VERSION "HNNBNNNYNNNNNNNNNNNNNNNNNNNNNNNNNNNNNNNNNN/4/%%%/4/'%**4NNN///"

NS_ :

BS_:

BU_: AAG BCM1 BCM2 ELV Gateway HDSG IEZS MFG MSBBR SAD SAD2 Schwerpanzer_Zusatz SitzMem_BFS SitzMem_FS SitzMem_HBFS SitzMem_HFS SitzMem_SR3 SpoilerSG TSG_BFS TSG_FS VSG VTS DK_Dummy

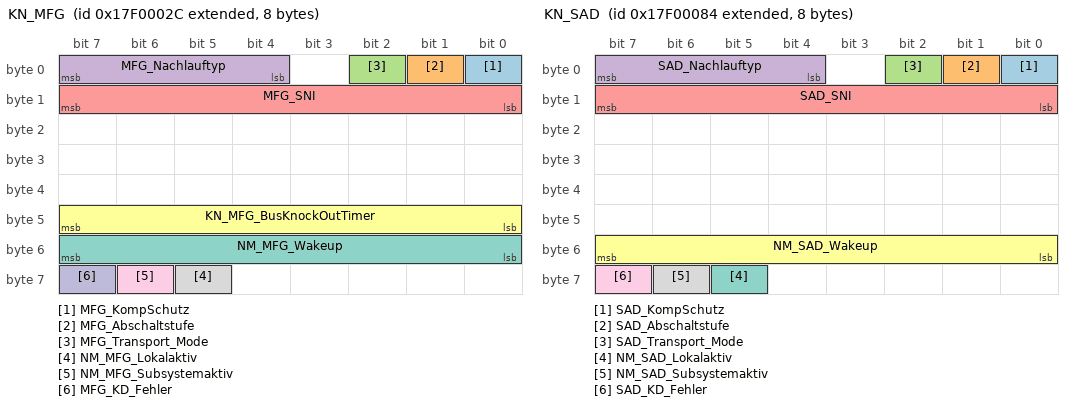
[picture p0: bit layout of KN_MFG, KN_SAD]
BO_ 2549088300 KN_MFG: 8 MFG
 SG_ MFG_KompSchutz : 0|1@1+ (1,0) [0|1] "" Vector__XXX
 SG_ MFG_Abschaltstufe : 1|1@1+ (1,0) [0|1] "" Vector__XXX
 SG_ MFG_Transport_Mode : 2|1@1+ (1,0) [0|1] "" Vector__XXX
 SG_ MFG_Nachlauftyp : 4|4@1+ (1,0) [0|15] ""  Gateway
 SG_ MFG_SNI : 8|8@1+ (1,0) [0|255] ""  Gateway
 SG_ KN_MFG_BusKnockOutTimer : 40|8@1+ (1,0) [0|254] ""  Gateway
 SG_ NM_MFG_Wakeup : 48|8@1+ (1,0) [0|255] "" Vector__XXX
 SG_ NM_MFG_Lokalaktiv : 61|1@1+ (1,0) [0|1] ""  Gateway
 SG_ NM_MFG_Subsystemaktiv : 62|1@1+ (1,0) [0|1] ""  Gateway
 SG_ MFG_KD_Fehler : 63|1@1+ (1,0) [0|1] ""  Gateway

BO_ 2549088388 KN_SAD: 8 SAD
 SG_ SAD_KompSchutz : 0|1@1+ (1,0) [0|1] "" Vector__XXX
 SG_ SAD_Abschaltstufe : 1|1@1+ (1,0) [0|1] "" Vector__XXX
 SG_ SAD_Transport_Mode : 2|1@1+ (1,0) [0|1] "" Vector__XXX
 SG_ SAD_Nachlauftyp : 4|4@1+ (1,0) [0|15] ""  Gateway
 SG_ SAD_SNI : 8|8@1+ (1,0) [0|255] ""  Gateway
 SG_ NM_SAD_Wakeup : 48|8@1+ (1,0) [0|255] "" Vector__XXX
 SG_ NM_SAD_Lokalaktiv : 61|1@1+ (1,0) [0|1] ""  Gateway
 SG_ NM_SAD_Subsystemaktiv : 62|1@1+ (1,0) [0|1] ""  Gateway
 SG_ SAD_KD_Fehler : 63|1@1+ (1,0) [0|1] ""  Gateway

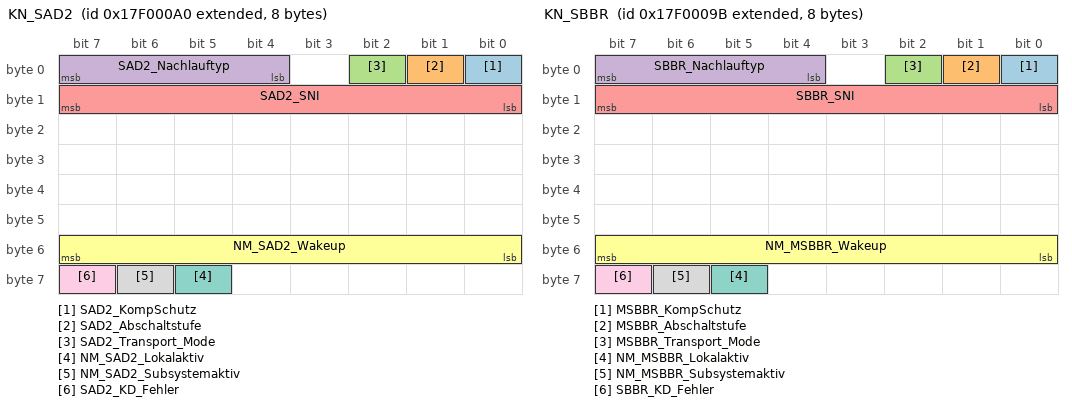
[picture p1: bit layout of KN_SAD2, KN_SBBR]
BO_ 2549088416 KN_SAD2: 8 SAD2
 SG_ SAD2_KompSchutz : 0|1@1+ (1,0) [0|1] "" Vector__XXX
 SG_ SAD2_Abschaltstufe : 1|1@1+ (1,0) [0|1] "" Vector__XXX
 SG_ SAD2_Transport_Mode : 2|1@1+ (1,0) [0|1] "" Vector__XXX
 SG_ SAD2_Nachlauftyp : 4|4@1+ (1,0) [0|15] ""  Gateway
 SG_ SAD2_SNI : 8|8@1+ (1,0) [0|255] ""  Gateway
 SG_ NM_SAD2_Wakeup : 48|8@1+ (1,0) [0|255] "" Vector__XXX
 SG_ NM_SAD2_Lokalaktiv : 61|1@1+ (1,0) [0|1] ""  Gateway
 SG_ NM_SAD2_Subsystemaktiv : 62|1@1+ (1,0) [0|1] "" Vector__XXX
 SG_ SAD2_KD_Fehler : 63|1@1+ (1,0) [0|1] ""  Gateway

BO_ 2549088411 KN_SBBR: 8 MSBBR
 SG_ MSBBR_KompSchutz : 0|1@1+ (1,0) [0|1] "" Vector__XXX
 SG_ MSBBR_Abschaltstufe : 1|1@1+ (1,0) [0|1] "" Vector__XXX
 SG_ MSBBR_Transport_Mode : 2|1@1+ (1,0) [0|1] "" Vector__XXX
 SG_ SBBR_Nachlauftyp : 4|4@1+ (1,0) [0|15] ""  Gateway
 SG_ SBBR_SNI : 8|8@1+ (1,0) [0|255] ""  Gateway
 SG_ NM_MSBBR_Wakeup : 48|8@1+ (1,0) [0|255] "" Vector__XXX
 SG_ NM_MSBBR_Lokalaktiv : 61|1@1+ (1,0) [0|1] ""  Gateway
 SG_ NM_MSBBR_Subsystemaktiv : 62|1@1+ (1,0) [0|1] ""  Gateway
 SG_ SBBR_KD_Fehler : 63|1@1+ (1,0) [0|1] ""  Gateway

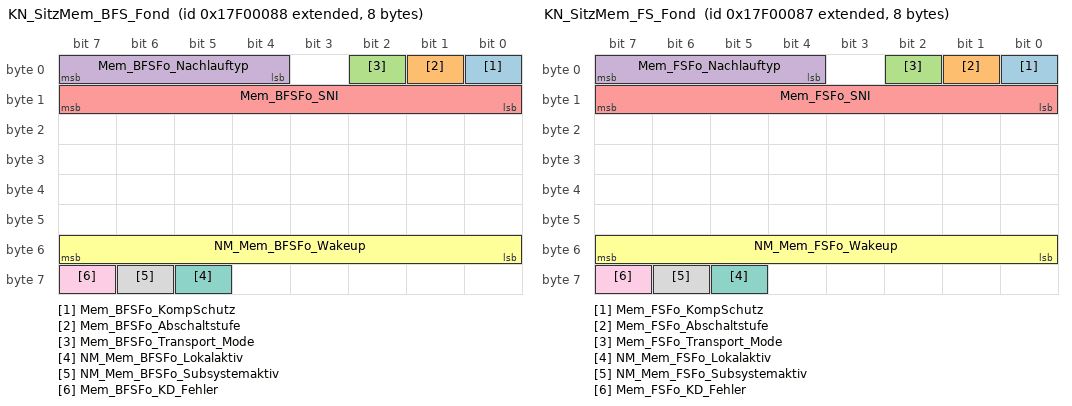
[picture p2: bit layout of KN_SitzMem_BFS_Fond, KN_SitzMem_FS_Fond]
BO_ 2549088392 KN_SitzMem_BFS_Fond: 8 SitzMem_HBFS
 SG_ Mem_BFSFo_KompSchutz : 0|1@1+ (1,0) [0|1] "" Vector__XXX
 SG_ Mem_BFSFo_Abschaltstufe : 1|1@1+ (1,0) [0|1] "" Vector__XXX
 SG_ Mem_BFSFo_Transport_Mode : 2|1@1+ (1,0) [0|1] "" Vector__XXX
 SG_ Mem_BFSFo_Nachlauftyp : 4|4@1+ (1,0) [0|15] ""  Gateway
 SG_ Mem_BFSFo_SNI : 8|8@1+ (1,0) [0|255] ""  Gateway
 SG_ NM_Mem_BFSFo_Wakeup : 48|8@1+ (1,0) [0|255] "" Vector__XXX
 SG_ NM_Mem_BFSFo_Lokalaktiv : 61|1@1+ (1,0) [0|1] ""  Gateway
 SG_ NM_Mem_BFSFo_Subsystemaktiv : 62|1@1+ (1,0) [0|1] ""  Gateway
 SG_ Mem_BFSFo_KD_Fehler : 63|1@1+ (1,0) [0|1] ""  Gateway

BO_ 2549088391 KN_SitzMem_FS_Fond: 8 SitzMem_HFS
 SG_ Mem_FSFo_KompSchutz : 0|1@1+ (1,0) [0|1] "" Vector__XXX
 SG_ Mem_FSFo_Abschaltstufe : 1|1@1+ (1,0) [0|1] "" Vector__XXX
 SG_ Mem_FSFo_Transport_Mode : 2|1@1+ (1,0) [0|1] "" Vector__XXX
 SG_ Mem_FSFo_Nachlauftyp : 4|4@1+ (1,0) [0|15] ""  Gateway
 SG_ Mem_FSFo_SNI : 8|8@1+ (1,0) [0|255] ""  Gateway
 SG_ NM_Mem_FSFo_Wakeup : 48|8@1+ (1,0) [0|255] "" Vector__XXX
 SG_ NM_Mem_FSFo_Lokalaktiv : 61|1@1+ (1,0) [0|1] ""  Gateway
 SG_ NM_Mem_FSFo_Subsystemaktiv : 62|1@1+ (1,0) [0|1] ""  Gateway
 SG_ Mem_FSFo_KD_Fehler : 63|1@1+ (1,0) [0|1] ""  Gateway

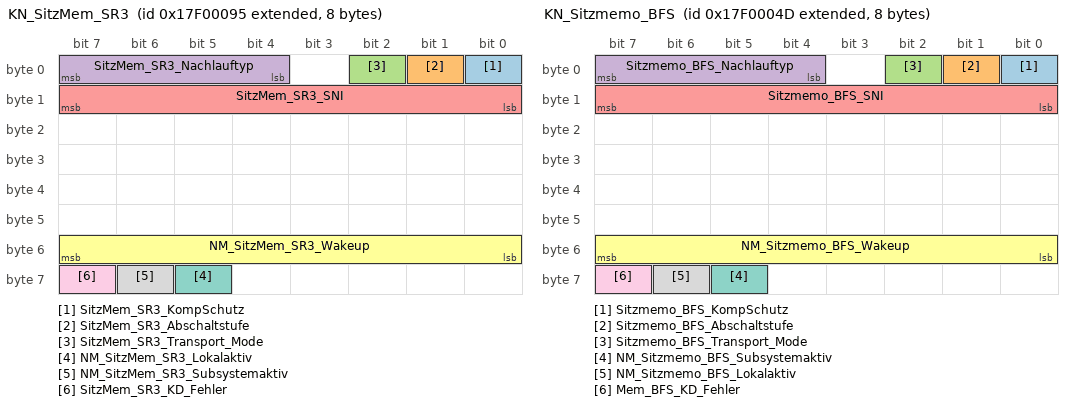
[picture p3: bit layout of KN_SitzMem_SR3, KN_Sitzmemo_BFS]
BO_ 2549088405 KN_SitzMem_SR3: 8 SitzMem_SR3
 SG_ SitzMem_SR3_KompSchutz : 0|1@1+ (1,0) [0|1] "" Vector__XXX
 SG_ SitzMem_SR3_Abschaltstufe : 1|1@1+ (1,0) [0|1] "" Vector__XXX
 SG_ SitzMem_SR3_Transport_Mode : 2|1@1+ (1,0) [0|1] "" Vector__XXX
 SG_ SitzMem_SR3_Nachlauftyp : 4|4@1+ (1,0) [0|15] ""  Gateway
 SG_ SitzMem_SR3_SNI : 8|8@1+ (1,0) [0|255] ""  Gateway
 SG_ NM_SitzMem_SR3_Wakeup : 48|8@1+ (1,0) [0|255] "" Vector__XXX
 SG_ NM_SitzMem_SR3_Lokalaktiv : 61|1@1+ (1,0) [0|1] ""  Gateway
 SG_ NM_SitzMem_SR3_Subsystemaktiv : 62|1@1+ (1,0) [0|1] "" Vector__XXX
 SG_ SitzMem_SR3_KD_Fehler : 63|1@1+ (1,0) [0|1] ""  Gateway

BO_ 2549088333 KN_Sitzmemo_BFS: 8 SitzMem_BFS
 SG_ Sitzmemo_BFS_KompSchutz : 0|1@1+ (1,0) [0|1] "" Vector__XXX
 SG_ Sitzmemo_BFS_Abschaltstufe : 1|1@1+ (1,0) [0|1] "" Vector__XXX
 SG_ Sitzmemo_BFS_Transport_Mode : 2|1@1+ (1,0) [0|1] "" Vector__XXX
 SG_ Sitzmemo_BFS_Nachlauftyp : 4|4@1+ (1,0) [0|15] ""  Gateway
 SG_ Sitzmemo_BFS_SNI : 8|8@1+ (1,0) [0|255] ""  Gateway
 SG_ NM_Sitzmemo_BFS_Wakeup : 48|8@1+ (1,0) [0|255] "" Vector__XXX
 SG_ NM_Sitzmemo_BFS_Subsystemaktiv : 61|1@1+ (1,0) [0|1] ""  Gateway
 SG_ NM_Sitzmemo_BFS_Lokalaktiv : 62|1@1+ (1,0) [0|1] ""  Gateway
 SG_ Mem_BFS_KD_Fehler : 63|1@1+ (1,0) [0|1] ""  Gateway

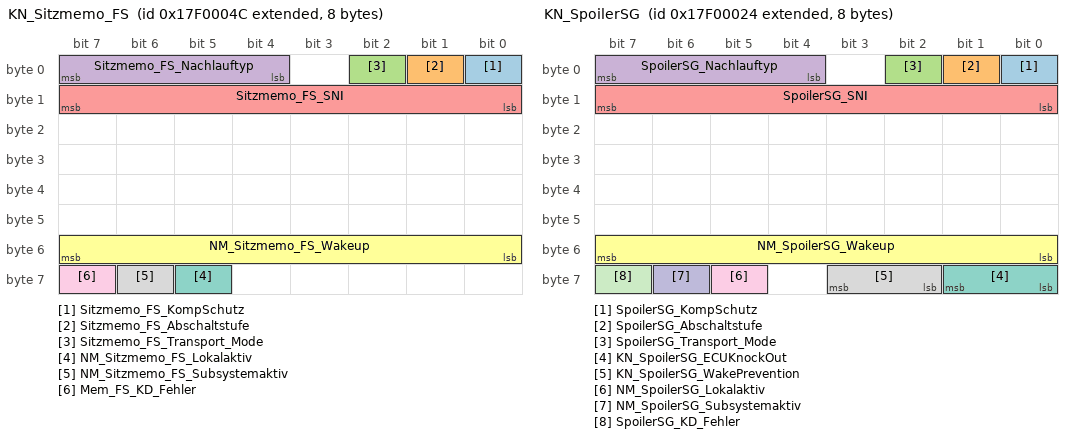
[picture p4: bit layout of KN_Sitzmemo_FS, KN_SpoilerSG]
BO_ 2549088332 KN_Sitzmemo_FS: 8 SitzMem_FS
 SG_ Sitzmemo_FS_KompSchutz : 0|1@1+ (1,0) [0|1] "" Vector__XXX
 SG_ Sitzmemo_FS_Abschaltstufe : 1|1@1+ (1,0) [0|1] "" Vector__XXX
 SG_ Sitzmemo_FS_Transport_Mode : 2|1@1+ (1,0) [0|1] "" Vector__XXX
 SG_ Sitzmemo_FS_Nachlauftyp : 4|4@1+ (1,0) [0|15] ""  Gateway
 SG_ Sitzmemo_FS_SNI : 8|8@1+ (1,0) [0|255] ""  Gateway
 SG_ NM_Sitzmemo_FS_Wakeup : 48|8@1+ (1,0) [0|255] "" Vector__XXX
 SG_ NM_Sitzmemo_FS_Lokalaktiv : 61|1@1+ (1,0) [0|1] ""  Gateway
 SG_ NM_Sitzmemo_FS_Subsystemaktiv : 62|1@1+ (1,0) [0|1] ""  Gateway
 SG_ Mem_FS_KD_Fehler : 63|1@1+ (1,0) [0|1] ""  Gateway

BO_ 2549088292 KN_SpoilerSG: 8 SpoilerSG
 SG_ SpoilerSG_KompSchutz : 0|1@1+ (1,0) [0|1] "" Vector__XXX
 SG_ SpoilerSG_Abschaltstufe : 1|1@1+ (1,0) [0|1] "" Vector__XXX
 SG_ SpoilerSG_Transport_Mode : 2|1@1+ (1,0) [0|1] "" Vector__XXX
 SG_ SpoilerSG_Nachlauftyp : 4|4@1+ (1,0) [0|15] ""  Gateway
 SG_ SpoilerSG_SNI : 8|8@1+ (1,0) [0|255] ""  Gateway
 SG_ NM_SpoilerSG_Wakeup : 48|8@1+ (1,0) [0|255] "" Vector__XXX
 SG_ KN_SpoilerSG_ECUKnockOut : 56|2@1+ (1,0) [0|3] ""  Gateway
 SG_ KN_SpoilerSG_WakePrevention : 58|2@1+ (1,0) [0|3] ""  Gateway
 SG_ NM_SpoilerSG_Lokalaktiv : 61|1@1+ (1,0) [0|1] "" Vector__XXX
 SG_ NM_SpoilerSG_Subsystemaktiv : 62|1@1+ (1,0) [0|1] "" Vector__XXX
 SG_ SpoilerSG_KD_Fehler : 63|1@1+ (1,0) [0|1] ""  Gateway

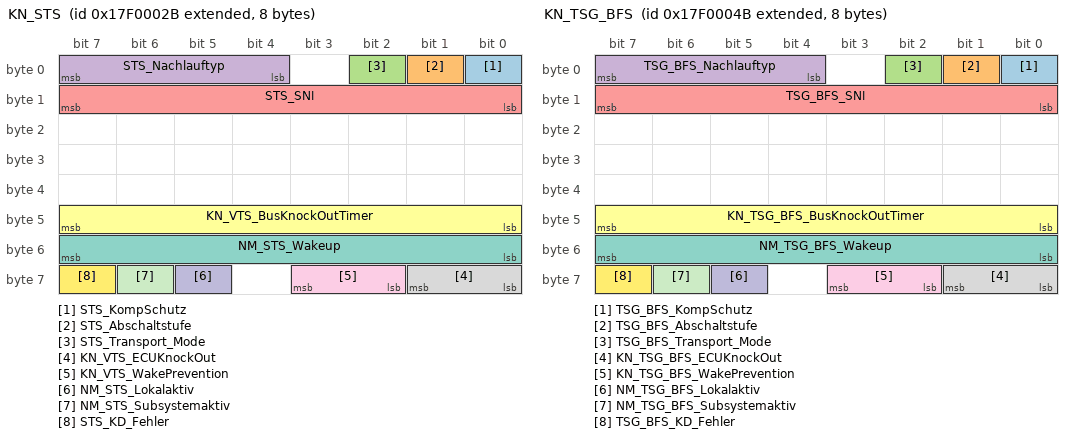
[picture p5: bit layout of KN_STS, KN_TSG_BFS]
BO_ 2549088299 KN_STS: 8 VTS
 SG_ STS_KompSchutz : 0|1@1+ (1,0) [0|1] "" Vector__XXX
 SG_ STS_Abschaltstufe : 1|1@1+ (1,0) [0|1] "" Vector__XXX
 SG_ STS_Transport_Mode : 2|1@1+ (1,0) [0|1] "" Vector__XXX
 SG_ STS_Nachlauftyp : 4|4@1+ (1,0) [0|15] ""  Gateway
 SG_ STS_SNI : 8|8@1+ (1,0) [0|255] ""  Gateway
 SG_ KN_VTS_BusKnockOutTimer : 40|8@1+ (1,0) [0|254] ""  Gateway
 SG_ NM_STS_Wakeup : 48|8@1+ (1,0) [0|255] "" Vector__XXX
 SG_ KN_VTS_ECUKnockOut : 56|2@1+ (1,0) [0|3] ""  Gateway
 SG_ KN_VTS_WakePrevention : 58|2@1+ (1,0) [0|3] ""  Gateway
 SG_ NM_STS_Lokalaktiv : 61|1@1+ (1,0) [0|1] ""  Gateway
 SG_ NM_STS_Subsystemaktiv : 62|1@1+ (1,0) [0|1] ""  Gateway
 SG_ STS_KD_Fehler : 63|1@1+ (1,0) [0|1] ""  Gateway

BO_ 2549088331 KN_TSG_BFS: 8 TSG_BFS
 SG_ TSG_BFS_KompSchutz : 0|1@1+ (1,0) [0|1] "" Vector__XXX
 SG_ TSG_BFS_Abschaltstufe : 1|1@1+ (1,0) [0|1] "" Vector__XXX
 SG_ TSG_BFS_Transport_Mode : 2|1@1+ (1,0) [0|1] "" Vector__XXX
 SG_ TSG_BFS_Nachlauftyp : 4|4@1+ (1,0) [0|15] ""  Gateway
 SG_ TSG_BFS_SNI : 8|8@1+ (1,0) [0|255] ""  Gateway
 SG_ KN_TSG_BFS_BusKnockOutTimer : 40|8@1+ (1,0) [0|254] ""  Gateway
 SG_ NM_TSG_BFS_Wakeup : 48|8@1+ (1,0) [0|255] "" Vector__XXX
 SG_ KN_TSG_BFS_ECUKnockOut : 56|2@1+ (1,0) [0|3] ""  Gateway
 SG_ KN_TSG_BFS_WakePrevention : 58|2@1+ (1,0) [0|3] ""  Gateway
 SG_ NM_TSG_BFS_Lokalaktiv : 61|1@1+ (1,0) [0|1] ""  Gateway
 SG_ NM_TSG_BFS_Subsystemaktiv : 62|1@1+ (1,0) [0|1] ""  Gateway
 SG_ TSG_BFS_KD_Fehler : 63|1@1+ (1,0) [0|1] ""  Gateway

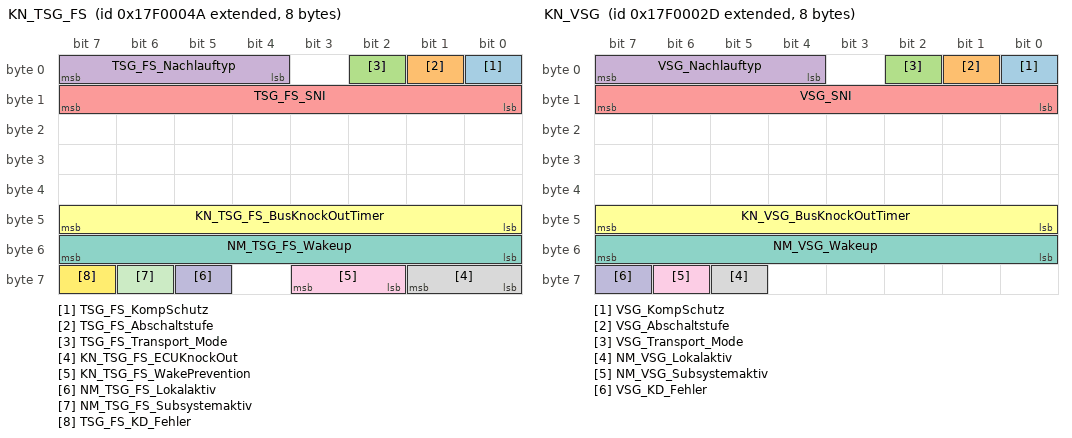
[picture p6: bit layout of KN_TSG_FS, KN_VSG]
BO_ 2549088330 KN_TSG_FS: 8 TSG_FS
 SG_ TSG_FS_KompSchutz : 0|1@1+ (1,0) [0|1] "" Vector__XXX
 SG_ TSG_FS_Abschaltstufe : 1|1@1+ (1,0) [0|1] "" Vector__XXX
 SG_ TSG_FS_Transport_Mode : 2|1@1+ (1,0) [0|1] "" Vector__XXX
 SG_ TSG_FS_Nachlauftyp : 4|4@1+ (1,0) [0|15] ""  Gateway
 SG_ TSG_FS_SNI : 8|8@1+ (1,0) [0|255] ""  Gateway
 SG_ KN_TSG_FS_BusKnockOutTimer : 40|8@1+ (1,0) [0|254] ""  Gateway
 SG_ NM_TSG_FS_Wakeup : 48|8@1+ (1,0) [0|255] "" Vector__XXX
 SG_ KN_TSG_FS_ECUKnockOut : 56|2@1+ (1,0) [0|3] ""  Gateway
 SG_ KN_TSG_FS_WakePrevention : 58|2@1+ (1,0) [0|3] ""  Gateway
 SG_ NM_TSG_FS_Lokalaktiv : 61|1@1+ (1,0) [0|1] ""  Gateway
 SG_ NM_TSG_FS_Subsystemaktiv : 62|1@1+ (1,0) [0|1] ""  Gateway
 SG_ TSG_FS_KD_Fehler : 63|1@1+ (1,0) [0|1] ""  Gateway

BO_ 2549088301 KN_VSG: 8 VSG
 SG_ VSG_KompSchutz : 0|1@1+ (1,0) [0|1] "" Vector__XXX
 SG_ VSG_Abschaltstufe : 1|1@1+ (1,0) [0|1] "" Vector__XXX
 SG_ VSG_Transport_Mode : 2|1@1+ (1,0) [0|1] "" Vector__XXX
 SG_ VSG_Nachlauftyp : 4|4@1+ (1,0) [0|15] ""  Gateway
 SG_ VSG_SNI : 8|8@1+ (1,0) [0|255] ""  Gateway
 SG_ KN_VSG_BusKnockOutTimer : 40|8@1+ (1,0) [0|254] ""  Gateway
 SG_ NM_VSG_Wakeup : 48|8@1+ (1,0) [0|255] "" Vector__XXX
 SG_ NM_VSG_Lokalaktiv : 61|1@1+ (1,0) [0|1] ""  Gateway
 SG_ NM_VSG_Subsystemaktiv : 62|1@1+ (1,0) [0|1] "" Vector__XXX
 SG_ VSG_KD_Fehler : 63|1@1+ (1,0) [0|1] ""  Gateway

BO_ 779 Kombi_01: 8 Gateway
 SG_ KBI_ABS_Lampe : 0|1@1+ (1,0) [0|1] "" Vector__XXX
 SG_ KBI_ESP_Lampe : 1|1@1+ (1,0) [0|1] ""  BCM1
 SG_ KBI_BKL_Lampe : 2|1@1+ (1,0) [0|1] "" Vector__XXX
 SG_ KBI_Airbag_Lampe : 3|1@1+ (1,0) [0|1] "" Vector__XXX
 SG_ KBI_SILA_gueltig : 4|1@1+ (1,0) [0|1] "" Vector__XXX
 SG_ KBI_Lenkung_Lampe : 5|1@1+ (1,0) [0|1] "" Vector__XXX
 SG_ KBI_Vorglueh_System_Lampe : 6|1@1+ (1,0) [0|1] "" Vector__XXX
 SG_ KBI_NV_in_Anzeige : 7|1@1+ (1,0) [0|1] "" Vector__XXX
 SG_ Kombi_01_BZ : 8|4@1+ (1,0) [0|15] "" Vector__XXX
 SG_ KBI_Anzeigestatus_ACC : 12|1@1+ (1,0) [0|1] "" Vector__XXX
 SG_ KBI_Anzeigestatus_GRA : 13|2@1+ (1,0) [0|3] "" Vector__XXX
 SG_ KBI_Oeldruck_Schalter : 15|1@1+ (1,0) [0|1] "" Vector__XXX
 SG_ KBI_Tankwarnung : 16|1@1+ (1,0) [0|1] ""  VTS
 SG_ KBI_MFA_v_Einheit_01 : 17|1@1+ (1,0) [0|1] "" Vector__XXX
 SG_ KBI_im_Stellgliedtest : 18|1@1+ (1,0) [0|1] "" Vector__XXX
 SG_ KBI_Anzeigefehler_LDW : 19|2@1+ (1,0) [0|3] "" Vector__XXX
 SG_ KBI_Oeldruckwarnung : 22|1@1+ (1,0) [0|1] "" Vector__XXX
 SG_ KBI_Handbremse : 23|1@1+ (1,0) [0|1] "" Vector__XXX
 SG_ KBI_V_Digital : 24|9@1+ (1,0) [0|511] "" Vector__XXX
 SG_ KBI_PLA_in_Anzeige : 33|1@1+ (1,0) [0|1] ""  BCM1
 SG_ KBI_Anzeigefehler_NV : 34|1@1+ (1,0) [0|1] "" Vector__XXX
 SG_ KBI_Anzeigestatus_LIM : 35|2@1+ (1,0) [0|3] "" Vector__XXX
 SG_ KBI_ARA_in_Anzeige : 37|1@1+ (1,0) [0|1] "" Vector__XXX
 SG_ KBI_angez_Geschw : 48|10@1+ (0.32,0) [0|325.12] "Unit_KiloMeterPerHour" Vector__XXX
 SG_ KBI_Einheit_Tacho : 58|1@1+ (1,0) [0|1] ""  VTS
 SG_ KBI_Konsistenz_ACC : 59|1@1+ (1,0) [0|1] "" Vector__XXX
 SG_ KBI_Fehler_Anzeige_ACC : 60|1@1+ (1,0) [0|1] "" Vector__XXX
 SG_ KBI_Anzeigefehler_SWA : 61|2@1+ (1,0) [0|3] "" Vector__XXX

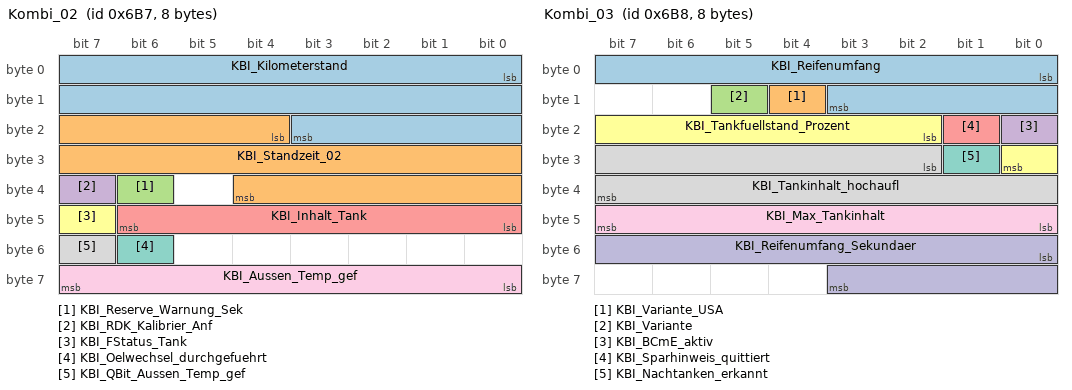
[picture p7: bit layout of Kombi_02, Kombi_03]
BO_ 1719 Kombi_02: 8 Gateway
 SG_ KBI_Kilometerstand : 0|20@1+ (1,0) [0|1048573] "Unit_KiloMeter" Vector__XXX
 SG_ KBI_Standzeit_02 : 20|17@1+ (1,0) [0|131068] "Unit_Secon"  BCM1
 SG_ KBI_Reserve_Warnung_Sek : 38|1@1+ (1,0) [0|1] "" Vector__XXX
 SG_ KBI_RDK_Kalibrier_Anf : 39|1@1+ (1,0) [0|1] "" Vector__XXX
 SG_ KBI_Inhalt_Tank : 40|7@1+ (1,0) [0|125] "Unit_Liter"  VTS
 SG_ KBI_FStatus_Tank : 47|1@1+ (1,0) [0|1] "" Vector__XXX
 SG_ KBI_Oelwechsel_durchgefuehrt : 54|1@1+ (1,0) [0|1] "" Vector__XXX
 SG_ KBI_QBit_Aussen_Temp_gef : 55|1@1+ (1,0) [0|1] ""  BCM1,BCM2,SpoilerSG
 SG_ KBI_Aussen_Temp_gef : 56|8@1+ (0.5,-50) [-50|75] "Unit_DegreCelsi"  SAD2,BCM1,BCM2,HDSG,SAD,SpoilerSG,TSG_BFS,TSG_FS,VSG,VTS

BO_ 1720 Kombi_03: 8 Gateway
 SG_ KBI_Reifenumfang : 0|12@1+ (1,0) [0|4095] "Unit_MilliMeter"  BCM2
 SG_ KBI_Variante_USA : 12|1@1+ (1,0) [0|1] "" Vector__XXX
 SG_ KBI_Variante : 13|1@1+ (1,0) [0|1] "" Vector__XXX
 SG_ KBI_BCmE_aktiv : 16|1@1+ (1,0) [0|1] "" Vector__XXX
 SG_ KBI_Sparhinweis_quittiert : 17|1@1+ (1,0) [0|1] "" Vector__XXX
 SG_ KBI_Tankfuellstand_Prozent : 18|7@1+ (1,0) [0|100] "Unit_PerCent"  VTS
 SG_ KBI_Nachtanken_erkannt : 25|1@1+ (1,0) [0|1] "" Vector__XXX
 SG_ KBI_Tankinhalt_hochaufl : 26|14@1+ (0.01,0) [0|163.81] "Unit_Liter" Vector__XXX
 SG_ KBI_Max_Tankinhalt : 40|8@1+ (0.5,0) [0|126.5] "" Vector__XXX
 SG_ KBI_Reifenumfang_Sekundaer : 48|12@1+ (1,0) [0|4095] "Unit_MilliMeter" Vector__XXX

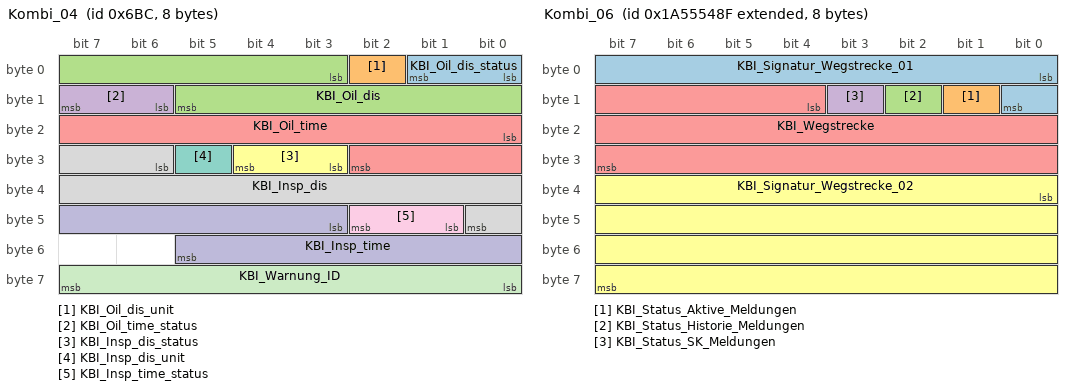
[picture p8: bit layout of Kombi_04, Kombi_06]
BO_ 1724 Kombi_04: 8 Gateway
 SG_ KBI_Oil_dis_status : 0|2@1+ (1,0) [0|3] ""  BCM2
 SG_ KBI_Oil_dis_unit : 2|1@1+ (1,0) [0|1] ""  BCM2
 SG_ KBI_Oil_dis : 3|11@1+ (100,0) [0|204700] ""  BCM2
 SG_ KBI_Oil_time_status : 14|2@1+ (1,0) [0|3] ""  BCM2
 SG_ KBI_Oil_time : 16|11@1+ (1,0) [0|2047] ""  BCM2
 SG_ KBI_Insp_dis_status : 27|2@1+ (1,0) [0|3] ""  BCM2
 SG_ KBI_Insp_dis_unit : 29|1@1+ (1,0) [0|1] ""  BCM2
 SG_ KBI_Insp_dis : 30|11@1+ (100,0) [0|204700] ""  BCM2
 SG_ KBI_Insp_time_status : 41|2@1+ (1,0) [0|3] ""  BCM2
 SG_ KBI_Insp_time : 43|11@1+ (1,0) [0|2047] ""  BCM2
 SG_ KBI_Warnung_ID : 56|8@1+ (1,0) [0|255] ""  BCM2

BO_ 2589283471 Kombi_06: 8 Gateway
 SG_ KBI_Signatur_Wegstrecke_01 : 0|9@1+ (1,0) [0|511] ""  BCM2
 SG_ KBI_Status_Aktive_Meldungen : 9|1@1+ (1,0) [0|1] "" Vector__XXX
 SG_ KBI_Status_Historie_Meldungen : 10|1@1+ (1,0) [0|1] "" Vector__XXX
 SG_ KBI_Status_SK_Meldungen : 11|1@1+ (1,0) [0|1] "" Vector__XXX
 SG_ KBI_Wegstrecke : 12|20@1+ (1,0) [0|1048575] ""  BCM2
 SG_ KBI_Signatur_Wegstrecke_02 : 32|32@1+ (1,0) [0|4294967295] ""  BCM2

BO_ 2549874958 KS_BCM1_Req: 8 Gateway
 SG_ KS_BCM1_Req_Data : 0|64@1+ (1,0) [0|1.84467440737096E+019] ""  BCM1

BO_ 2550006030 KS_BCM1_Resp: 8 BCM1
 SG_ KS_BCM1_Resp_Data : 0|64@1+ (1,0) [0|1.84467440737096E+019] ""  Gateway

BO_ 2549875083 KS_BCM2_Req: 8 Gateway
 SG_ KS_BCM2_Req_Data : 0|64@1+ (1,0) [0|1.84467440737096E+019] ""  BCM2

BO_ 2550006155 KS_BCM2_Resp: 8 BCM2
 SG_ KS_BCM2_Resp_Data : 0|64@1+ (1,0) [0|1.84467440737096E+019] ""  Gateway

BO_ 919 LDW_02: 8 Gateway
 SG_ LDW_Gong : 12|2@1+ (1,0) [0|3] "" Vector__XXX
 SG_ LDW_Frueh_Spaet : 14|2@1+ (1,0) [0|3] "" Vector__XXX
 SG_ LDW_Texte : 16|4@1+ (1,0) [0|15] "" Vector__XXX
 SG_ LDW_Seite_DLCTLC : 20|1@1+ (1,0) [0|1] "" Vector__XXX
 SG_ LDW_Lernmodus : 21|3@1+ (1,0) [0|7] "" Vector__XXX
 SG_ LDW_Anlaufsp_VLR : 24|4@1+ (1,0) [0|15] "" Vector__XXX
 SG_ LDW_Vib_Amp_VLR : 28|4@1+ (1,0) [0|15] "" Vector__XXX
 SG_ LDW_Anlaufzeit_VLR : 32|4@1+ (1,0) [0|15] "" Vector__XXX
 SG_ LDW_Lernmodus_seitenabhaengig : 36|4@1+ (1,0) [0|15] "" Vector__XXX
 SG_ LDW_DLC : 40|8@1+ (0.01,-1.25) [-1.25|1.25] "Unit_Meter" Vector__XXX
 SG_ LDW_TLC : 48|5@1+ (0.1,0) [0|3] "Unit_Secon" Vector__XXX
 SG_ HC_Uss_Anforderung : 53|1@1+ (1,0) [0|1] ""  BCM1
 SG_ EA_Warnblinken : 54|2@1+ (1,0) [0|3] "" Vector__XXX
 SG_ LDW_Warnung_links : 56|1@1+ (1,0) [0|1] "" Vector__XXX
 SG_ LDW_Warnung_rechts : 57|1@1+ (1,0) [0|1] "" Vector__XXX
 SG_ LDW_Codierinfo_fuer_VLR : 58|2@1+ (1,0) [0|3] "" Vector__XXX
 SG_ LDW_Status_LED_gelb : 61|1@1+ (1,0) [0|1] "" Vector__XXX
 SG_ LDW_Status_LED_gruen : 62|1@1+ (1,0) [0|1] "" Vector__XXX

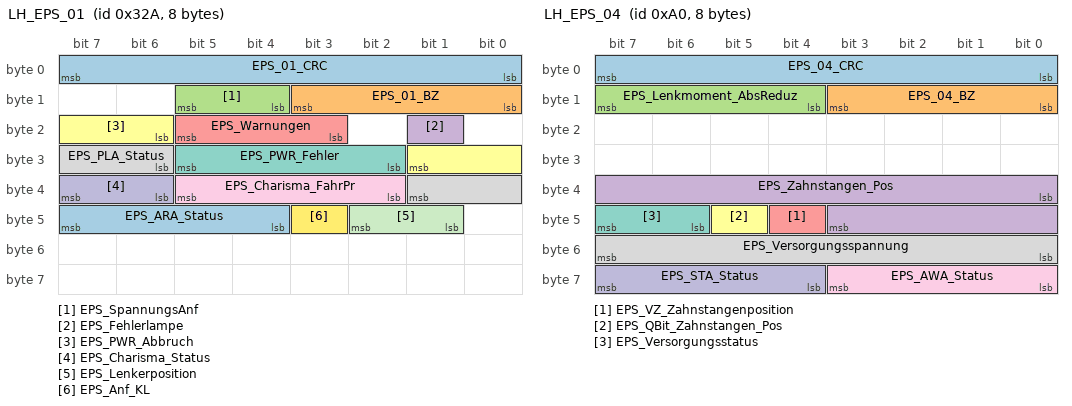
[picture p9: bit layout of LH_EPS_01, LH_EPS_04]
BO_ 810 LH_EPS_01: 8 Gateway
 SG_ EPS_01_CRC : 0|8@1+ (1,0) [0|255] ""  BCM1
 SG_ EPS_01_BZ : 8|4@1+ (1,0) [0|15] ""  BCM1
 SG_ EPS_SpannungsAnf : 12|2@1+ (1,0) [0|3] "" Vector__XXX
 SG_ EPS_Fehlerlampe : 17|1@1+ (1,0) [0|1] "" Vector__XXX
 SG_ EPS_Warnungen : 19|3@1+ (1,0) [0|7] "" Vector__XXX
 SG_ EPS_PWR_Abbruch : 22|4@1+ (1,0) [0|15] ""  BCM1
 SG_ EPS_PWR_Fehler : 26|4@1+ (1,0) [0|15] ""  BCM1
 SG_ EPS_PLA_Status : 30|4@1+ (1,0) [0|15] ""  BCM1
 SG_ EPS_Charisma_FahrPr : 34|4@1+ (1,0) [0|15] "" Vector__XXX
 SG_ EPS_Charisma_Status : 38|2@1+ (1,0) [0|3] "" Vector__XXX
 SG_ EPS_Lenkerposition : 41|2@1+ (1,0) [0|3] "" Vector__XXX
 SG_ EPS_Anf_KL : 43|1@1+ (1,0) [0|1] "" Vector__XXX
 SG_ EPS_ARA_Status : 44|4@1+ (1,0) [0|15] ""  BCM1

BO_ 160 LH_EPS_04: 8 Gateway
 SG_ EPS_04_CRC : 0|8@1+ (1,0) [0|255] ""  BCM1
 SG_ EPS_04_BZ : 8|4@1+ (1,0) [0|15] ""  BCM1
 SG_ EPS_Lenkmoment_AbsReduz : 12|4@1+ (0.62,0.61) [0.61|8.05] "Unit_NewtoMeter"  BCM1
 SG_ EPS_Zahnstangen_Pos : 32|12@1+ (0.02,0) [0|81.86] "Unit_MilliMeter"  BCM1
 SG_ EPS_VZ_Zahnstangenposition : 44|1@1+ (1,0) [0|1] ""  BCM1
 SG_ EPS_QBit_Zahnstangen_Pos : 45|1@1+ (1,0) [0|1] ""  BCM1
 SG_ EPS_Versorgungsstatus : 46|2@1+ (1,0) [0|3] "" Vector__XXX
 SG_ EPS_Versorgungsspannung : 48|8@1+ (0.05,5.05) [5.05|17.7] "Unit_Volt" Vector__XXX
 SG_ EPS_AWA_Status : 56|4@1+ (1,0) [0|15] "" Vector__XXX
 SG_ EPS_STA_Status : 60|4@1+ (1,0) [0|15] "" Vector__XXX

BO_ 981 Licht_Anf_01: 8 BCM1
 SG_ Licht_Anf_01_CRC : 0|8@1+ (1,0) [0|255] ""  AAG,BCM2,Gateway,MSBBR
 SG_ Licht_Anf_01_BZ : 8|4@1+ (1,0) [0|15] ""  AAG,BCM2,Gateway
 SG_ BCM1_Kurvenlicht_links_Anf : 12|1@1+ (1,0) [0|1] ""  Gateway
 SG_ BCM1_Kurvenlicht_rechts_Anf : 13|1@1+ (1,0) [0|1] ""  Gateway
 SG_ BCM1_Standlicht_Anf : 14|1@1+ (1,0) [0|1] ""  Gateway,MFG,MSBBR
 SG_ BCM1_Abblendlicht_Anf : 15|1@1+ (1,0) [0|1] ""  Gateway,MFG
 SG_ BCM1_Fernlicht_Anf : 16|1@1+ (1,0) [0|1] ""  Gateway,MFG
 SG_ BCM1_Nebellicht_Anf : 17|1@1+ (1,0) [0|1] ""  Gateway,MFG
 SG_ BCM1_Parklicht_li_Anf : 18|1@1+ (1,0) [0|1] ""  AAG,BCM2,Gateway,MSBBR
 SG_ BCM1_Parklicht_re_Anf : 19|1@1+ (1,0) [0|1] ""  AAG,BCM2,Gateway,MSBBR
 SG_ BCM1_Nebelschluss_Ahg_Anf : 20|1@1+ (1,0) [0|1] ""  AAG,Gateway,MFG
 SG_ BCM1_Nebelschluss_Fzg_Anf : 21|1@1+ (1,0) [0|1] ""  BCM2,Gateway,MFG,MSBBR
 SG_ BCM1_Schlusslicht_Anf : 22|1@1+ (1,0) [0|1] ""  AAG,BCM2,Gateway,MFG,MSBBR
 SG_ BCM_Rueckfahrlicht_Anf : 23|1@1+ (1,0) [0|1] ""  AAG,BCM2,Gateway,MFG,MSBBR,TSG_BFS,TSG_FS
 SG_ BCM1_Umfeldleuchten_Anf : 25|1@1+ (1,0) [0|1] ""  Gateway,TSG_BFS,TSG_FS
 SG_ BCM1_Tagfahrlicht_Anf : 26|1@1+ (1,0) [0|1] ""  Gateway,MFG
 SG_ BCM1_Regenlicht_Anf : 27|1@1+ (1,0) [0|1] ""  Gateway,MFG,MSBBR
 SG_ BCM1_Autobahnlicht_Anf : 28|1@1+ (1,0) [0|1] ""  Gateway,MFG
 SG_ BCM1_Touristen_Licht_Anf : 29|1@1+ (1,0) [0|1] ""  Gateway,MSBBR
 SG_ BCM1_Gleitende_Leuchtw_Anf : 32|1@1+ (1,0) [0|1] ""  Gateway
 SG_ BCM1_GLW_Fernlicht_Anf : 33|1@1+ (1,0) [0|1] ""  Gateway
 SG_ BCM1_Adaptive_Lichtvert_Anf : 34|1@1+ (1,0) [0|1] ""  Gateway
 SG_ BCM1_CH_LH_aktiv : 40|1@1+ (1,0) [0|1] ""  Gateway,MSBBR
 SG_ BCM1_Allwetterlicht_Anf : 41|1@1+ (1,0) [0|1] ""  Gateway,MSBBR

BO_ 982 Licht_hinten_01: 8 BCM2
 SG_ BCM2_Bremsl_durch_ECD : 5|1@1+ (1,0) [0|1] ""  Gateway
 SG_ LH_Aussenlicht_def : 7|1@1+ (1,0) [0|1] ""  Gateway,VTS
 SG_ LH_Standlicht_H_aktiv : 8|1@1+ (1,0) [0|1] ""  Gateway
 SG_ LH_Parklicht_HL_aktiv : 9|1@1+ (1,0) [0|1] ""  Gateway
 SG_ LH_Parklicht_HR_aktiv : 10|1@1+ (1,0) [0|1] ""  Gateway
 SG_ LH_Bremslicht_H_aktiv : 11|1@1+ (1,0) [0|1] ""  Gateway
 SG_ LH_Nebelschluss_aktiv : 12|1@1+ (1,0) [0|1] ""  BCM1,Gateway
 SG_ LH_Rueckfahrlicht_aktiv : 13|1@1+ (1,0) [0|1] ""  Gateway,SitzMem_FS,TSG_BFS,TSG_FS
 SG_ LH_Blinker_HL_akt : 14|1@1+ (1,0) [0|1] ""  Gateway
 SG_ LH_Blinker_HR_akt : 15|1@1+ (1,0) [0|1] ""  Gateway
 SG_ LH_Blinker_li_def : 16|1@1+ (1,0) [0|1] ""  Gateway,VTS
 SG_ LH_Bremsl_li_def : 17|1@1+ (1,0) [0|1] ""  Gateway,VTS
 SG_ LH_Schlusslicht_li_def : 18|1@1+ (1,0) [0|1] ""  Gateway,VTS
 SG_ LH_Rueckf_li_def : 19|1@1+ (1,0) [0|1] ""  Gateway,VTS
 SG_ LH_Nebel_li_def : 20|1@1+ (1,0) [0|1] ""  Gateway,VTS
 SG_ LH_Schluss_Brems_Nebel_li_def : 21|1@1+ (1,0) [0|1] ""  Gateway,VTS
 SG_ LH_Schluss_Brems_Nebel_re_def : 22|1@1+ (1,0) [0|1] ""  Gateway,VTS
 SG_ LH_Schluss_Brems_li_def : 24|1@1+ (1,0) [0|1] ""  Gateway,VTS
 SG_ LH_Schluss_Nebel_li_def : 25|1@1+ (1,0) [0|1] ""  Gateway,VTS
 SG_ LH_SL_BRL_BLK_li_def : 26|1@1+ (1,0) [0|1] ""  Gateway
 SG_ LH_Brems_Blk_li_def : 27|1@1+ (1,0) [0|1] ""  Gateway,VTS
 SG_ LH_Blinker_re_def : 32|1@1+ (1,0) [0|1] ""  Gateway,VTS
 SG_ LH_Bremsl_re_def : 33|1@1+ (1,0) [0|1] ""  Gateway,VTS
 SG_ LH_Schlusslicht_re_def : 34|1@1+ (1,0) [0|1] ""  Gateway,VTS
 SG_ LH_Rueckf_re_def : 35|1@1+ (1,0) [0|1] ""  Gateway,VTS
 SG_ LH_Nebel_re_def : 36|1@1+ (1,0) [0|1] ""  Gateway,VTS
 SG_ LH_Schluss_Brems_re_def : 40|1@1+ (1,0) [0|1] ""  Gateway,VTS
 SG_ LH_Schluss_Nebel_re_def : 41|1@1+ (1,0) [0|1] ""  Gateway,VTS
 SG_ LH_SL_BRL_BLK_re_def : 42|1@1+ (1,0) [0|1] ""  Gateway,VTS
 SG_ LH_Brems_Blk_re_def : 43|1@1+ (1,0) [0|1] ""  Gateway,VTS
 SG_ LH_Kennzl_def : 48|1@1+ (1,0) [0|1] ""  Gateway,VTS
 SG_ LH_3_Bremsl_def : 49|1@1+ (1,0) [0|1] ""  Gateway,VTS
 SG_ LH_Nebel_mi_def : 50|1@1+ (1,0) [0|1] ""  Gateway,VTS
 SG_ LH_Rueckf_mi_def : 51|1@1+ (1,0) [0|1] ""  Gateway,VTS
 SG_ LH_Bremsl_li_ges_def : 54|1@1+ (1,0) [0|1] ""  Gateway,VTS
 SG_ LH_Bremsl_re_ges_def : 55|1@1+ (1,0) [0|1] ""  Gateway,VTS

BO_ 1624 Licht_vorne_01: 8 BCM1
 SG_ Licht_Vorne_01_CRC : 0|8@1+ (1,0) [0|255] ""  BCM2,Gateway
 SG_ Licht_Vorne_01_BZ : 8|4@1+ (1,0) [0|15] ""  BCM2,Gateway
 SG_ LV_Standlicht_Anzeige : 12|1@1+ (1,0) [0|1] ""  Gateway,VTS
 SG_ LV_Abblendlicht_Anzeige : 13|1@1+ (1,0) [0|1] ""  Gateway,VTS
 SG_ LV_Fernlicht_Anzeige : 14|1@1+ (1,0) [0|1] ""  Gateway,VTS
 SG_ LV_Nebellicht_Anzeige : 15|1@1+ (1,0) [0|1] ""  Gateway,VTS
 SG_ LV_Nebelschlusslicht_Anzeige : 16|1@1+ (1,0) [0|1] ""  Gateway
 SG_ LV_Tagfahrlicht_Anzeige : 17|1@1+ (1,0) [0|1] ""  Gateway,VTS
 SG_ LV_AFL_aktiv_Anzeige : 18|1@1+ (1,0) [0|1] ""  Gateway
 SG_ LV_AFL_defekt : 19|1@1+ (1,0) [0|1] ""  Gateway,VTS
 SG_ LV_Blinker_li_def : 20|1@1+ (1,0) [0|1] ""  BCM2,Gateway,VTS
 SG_ LV_Standlicht_li_def : 21|1@1+ (1,0) [0|1] ""  Gateway,VTS
 SG_ LV_Abblendlicht_li_def : 22|1@1+ (1,0) [0|1] ""  Gateway
 SG_ LV_Fernlicht_li_def : 23|1@1+ (1,0) [0|1] ""  Gateway,VTS
 SG_ LV_Nebellicht_li_def : 24|1@1+ (1,0) [0|1] ""  Gateway,VTS
 SG_ LV_Blk_li_Seite_def : 25|1@1+ (1,0) [0|1] ""  Gateway,VTS
 SG_ LV_Tagfahrlicht_li_def : 26|1@1+ (1,0) [0|1] ""  Gateway,VTS
 SG_ LV_FLA_aktiv_Anzeige : 27|1@1+ (1,0) [0|1] ""  Gateway
 SG_ LV_FLA_defekt : 28|1@1+ (1,0) [0|1] ""  Gateway,VTS
 SG_ LV_FLA_Sensor_blockiert : 29|1@1+ (1,0) [0|1] ""  Gateway
 SG_ LV_Blinker_re_def : 30|1@1+ (1,0) [0|1] ""  BCM2,Gateway,VTS
 SG_ LV_Standlicht_re_def : 31|1@1+ (1,0) [0|1] ""  Gateway,VTS
 SG_ LV_Abblendlicht_re_def : 32|1@1+ (1,0) [0|1] ""  Gateway,VTS
 SG_ LV_Fernlicht_re_def : 33|1@1+ (1,0) [0|1] ""  Gateway,VTS
 SG_ LV_Nebellicht_re_def : 34|1@1+ (1,0) [0|1] ""  Gateway,VTS
 SG_ LV_Blk_re_Seite_def : 35|1@1+ (1,0) [0|1] ""  Gateway,VTS
 SG_ LV_Tagfahrlicht_re_def : 36|1@1+ (1,0) [0|1] ""  Gateway,VTS
 SG_ LV_Aussenlicht_def : 37|1@1+ (1,0) [0|1] ""  Gateway
 SG_ LV_Abblendlicht_TFL_li_def : 38|1@1+ (1,0) [0|1] ""  Gateway,VTS
 SG_ LV_Nebellicht_TFL_li_def : 39|1@1+ (1,0) [0|1] ""  Gateway,VTS
 SG_ LV_Standlicht_TFL_li_def : 40|1@1+ (1,0) [0|1] ""  Gateway,VTS
 SG_ LV_Abblend_Fernlicht_li_def : 41|1@1+ (1,0) [0|1] ""  Gateway,VTS
 SG_ LV_Abblendlicht_TFL_re_def : 42|1@1+ (1,0) [0|1] ""  Gateway,VTS
 SG_ LV_Nebellicht_TFL_re_def : 43|1@1+ (1,0) [0|1] ""  Gateway,VTS
 SG_ LV_Standlicht_TFL_re_def : 44|1@1+ (1,0) [0|1] ""  Gateway,VTS
 SG_ LV_Abblend_Fernlicht_re_def : 45|1@1+ (1,0) [0|1] ""  Gateway,VTS
 SG_ LV_Abbiegelicht_li_def : 46|1@1+ (1,0) [0|1] ""  Gateway
 SG_ LV_Abbiegelicht_re_def : 47|1@1+ (1,0) [0|1] ""  Gateway
 SG_ BCM1_Linksverkehr : 48|1@1+ (1,0) [0|1] ""  Gateway
 SG_ BCM1_Licht_Dunkelheit_aktiv : 49|1@1+ (1,0) [0|1] ""  Gateway,MFG
 SG_ LV_LED_Scheinwerfer_li_def : 50|1@1+ (1,0) [0|1] ""  Gateway
 SG_ LV_LED_Scheinwerfer_re_def : 51|1@1+ (1,0) [0|1] ""  Gateway
 SG_ LV_Blinker_VL_aktiv : 52|1@1+ (1,0) [0|1] ""  BCM2,Gateway
 SG_ LV_Blinker_VR_aktiv : 53|1@1+ (1,0) [0|1] ""  BCM2,Gateway

BO_ 917 LWR_AFS_01: 8 BCM1
 SG_ AFS_Abbiegelicht_li_Anf : 0|1@1+ (1,0) [0|1] ""  Gateway
 SG_ AFS_Abbiegelicht_re_Anf : 1|1@1+ (1,0) [0|1] ""  Gateway
 SG_ AFS_Abbiegelicht_Dimm_Anf : 2|1@1+ (1,0) [0|1] ""  Gateway
 SG_ AFS_Verfuegbarkeit_GLW : 3|1@1+ (1,0) [0|1] ""  Gateway
 SG_ AFS_Status_adaptive_LV : 4|1@1+ (1,0) [0|1] ""  Gateway
 SG_ AFS_Fernlicht_li_defekt : 5|1@1+ (1,0) [0|1] ""  Gateway
 SG_ AFS_Fernlicht_re_defekt : 6|1@1+ (1,0) [0|1] ""  Gateway
 SG_ AFS_Fernlicht_Status : 7|1@1+ (1,0) [0|1] ""  Gateway
 SG_ LWR_AFS_01_BZ : 8|4@1+ (1,0) [0|15] ""  Gateway
 SG_ AFS_Lampe : 12|1@1+ (1,0) [0|1] ""  Gateway
 SG_ LWR_Lampe : 13|1@1+ (1,0) [0|1] ""  Gateway
 SG_ AFS_Fehlertext : 14|1@1+ (1,0) [0|1] ""  Gateway
 SG_ AFS_LED_Blinkmode : 15|1@1+ (1,0) [0|1] ""  Gateway
 SG_ LWR_Touristenmodus_aktiv : 16|1@1+ (1,0) [0|1] ""  Gateway
 SG_ AFS_Charisma_FahrPr : 17|4@1+ (1,0) [0|15] ""  Gateway
 SG_ AFS_Charisma_Status : 21|2@1+ (1,0) [0|3] ""  Gateway
 SG_ LWR_Sicherheitsposition_re : 23|1@1+ (1,0) [0|1] ""  Gateway
 SG_ AFS_Allwetterlicht : 24|1@1+ (1,0) [0|1] ""  Gateway
 SG_ LWR_Touristenmodus_verbaut : 25|1@1+ (1,0) [0|1] ""  Gateway
 SG_ AFS_adaptive_LV_verbaut : 26|1@1+ (1,0) [0|1] ""  Gateway
 SG_ LWR_Reisemodus_Texte : 27|2@1+ (1,0) [0|3] ""  Gateway
 SG_ GLW_Sensor_blockiert : 29|1@1+ (1,0) [0|1] ""  Gateway
 SG_ AFS_Charisma_Umschaltung : 30|2@1+ (1,0) [0|3] ""  Gateway
 SG_ LWR_Pos_Schrittmotor : 32|8@1+ (0.4,0) [0|100] "Unit_PerCent"  Gateway
 SG_ LWR_Hoehenwert_VL : 40|8@1+ (1,-127) [-127|126] ""  Gateway
 SG_ LWR_Hoehenwert_HL : 48|8@1+ (1,-127) [-127|126] ""  Gateway
 SG_ AFS_Ersatzlicht_Links : 56|1@1+ (1,0) [0|1] ""  Gateway
 SG_ AFS_Ersatzlicht_Rechts : 57|1@1+ (1,0) [0|1] ""  Gateway
 SG_ LWR_AFS_Grundeinstellung : 58|1@1+ (1,0) [0|1] ""  Gateway
 SG_ LWR_AFS_Parametrisierung : 59|1@1+ (1,0) [0|1] ""  Gateway
 SG_ LWR_Initialisierungslauf : 60|1@1+ (1,0) [0|1] ""  Gateway
 SG_ LWR_Sicherheitsposition_li : 61|1@1+ (1,0) [0|1] ""  Gateway
 SG_ LWR_Modus : 62|1@1+ (1,0) [0|1] ""  Gateway

CM_ SG_ 2549088300 MFG_KompSchutz "Funktionseinschränkung aufgrund Komponentenschutz aktiv";
CM_ SG_ 2549088300 MFG_Abschaltstufe "Funktionseinschränkung aufgrund aktiver Abschaltstufe";
CM_ SG_ 2549088300 MFG_Transport_Mode "Funktionseinschränkung aufgrund aktivem Transport Mode und/oder Transport Schutz";
CM_ SG_ 2549088300 MFG_Nachlauftyp "Abgebildet wird die von der Hardware vorgegebene Möglichkeit, die Kommunikation nach Klemme 15 = AUS aufrecht zu erhalten. Es wird ein Init-Wert gesendet.
0 = Kommunikation nur bei KL15=EIN (kein Nachlauf, nicht weckfähig)
1 = Kommunikation nach KL15=AU";
CM_ SG_ 2549088300 MFG_SNI "Das Signal beinhaltet den Source Node Identifier (Knotenadresse, die auch in der Abbildungsvorschrift zur CAN-ID für die NM-High Botschaft verwendet wird).";
CM_ SG_ 2549088300 KN_MFG_BusKnockOutTimer "Ausgabe des BusKnockOut-Timer in der Knotenbotschaft";
CM_ SG_ 2549088300 NM_MFG_Wakeup "enthält die Weckursache; stehen mehrere Weckursachen parallel an, dann muss der kleinste Wert übertragen werden
";
CM_ SG_ 2549088300 NM_MFG_Lokalaktiv "Zeigt an ob das SG nach Klemme15 AUS und nach entsprechender MAX Aktivzeit noch aktiv war
B8";
CM_ SG_ 2549088300 NM_MFG_Subsystemaktiv "Zeigt an ob ein Subsystem des SGs nach Klemme15 AUS und nach entsprechender MAX Aktivzeit noch aktiv war";
CM_ SG_ 2549088300 MFG_KD_Fehler "Status Kundendienstfehlerspeichereinträge
";
CM_ SG_ 2549088388 SAD_KompSchutz "Funktionseinschränkung aufgrund Komponentenschutz aktiv";
CM_ SG_ 2549088388 SAD_Abschaltstufe "Funktionseinschränkung aufgrund aktiver Abschaltstufe";
CM_ SG_ 2549088388 SAD_Transport_Mode "Funktionseinschränkung aufgrund aktivem Transport Mode und/oder Transport Schutz";
CM_ SG_ 2549088388 SAD_Nachlauftyp "Abgebildet wird die von der Hardware vorgegebene Möglichkeit, die Kommunikation nach Klemme 15 = AUS aufrecht zu erhalten. Es wird ein Init-Wert gesendet.
0 = Kommunikation nur bei KL15=EIN (kein Nachlauf, nicht weckfähig)
1 = Kommunikation nach KL15=AU";
CM_ SG_ 2549088388 SAD_SNI "Das Signal beinhaltet den Source Node Identifier (Knotenadresse, die auch in der Abbildungsvorschrift zur CAN-ID für die NM-High Botschaft verwendet wird).";
CM_ SG_ 2549088388 NM_SAD_Wakeup "enthält die Weckursache; stehen mehrere Weckursachen parallel an, dann muss der kleinste Wert übertragen werden";
CM_ SG_ 2549088388 NM_SAD_Lokalaktiv "Zeigt an ob das SG nach Klemme15 AUS und nach entsprechender MAX Aktivzeit noch aktiv war
alt";
CM_ SG_ 2549088388 NM_SAD_Subsystemaktiv "Zeigt an ob ein Subsystem des SGs nach Klemme15 AUS und nach entsprechender MAX Aktivzeit noch aktiv war";
CM_ SG_ 2549088388 SAD_KD_Fehler "Status Kundendienst-Fehlerspeicher";
CM_ SG_ 2549088416 SAD2_KompSchutz "Funktionseinschränkung aufgrund Komponentenschutz aktiv";
CM_ SG_ 2549088416 SAD2_Abschaltstufe "Funktionseinschränkung aufgrund aktiver Abschaltstufe";
CM_ SG_ 2549088416 SAD2_Transport_Mode "Funktionseinschränkung aufgrund aktivem Transport Mode und/oder Transport Schutz";
CM_ SG_ 2549088416 SAD2_Nachlauftyp "Abgebildet wird die von der Hardware vorgegebene Möglichkeit, die Kommunikation nach Klemme 15 = AUS aufrecht zu erhalten. Es wird ein Init-Wert gesendet.
0 = Kommunikation nur bei KL15=EIN (kein Nachlauf, nicht weckfähig)
1 = Kommunikation nach KL15=AU";
CM_ SG_ 2549088416 SAD2_SNI "Das Signal beinhaltet den Source Node Identifier (Knotenadresse, die auch in der Abbildungsvorschrift zur CAN-ID für die NM-High Botschaft verwendet wird).";
CM_ SG_ 2549088416 NM_SAD2_Wakeup "enthält die Weckursache; stehen mehrere Weckursachen parallel an, dann muss der kleinste Wert übertragen werden
";
CM_ SG_ 2549088416 NM_SAD2_Lokalaktiv "Zeigt an ob das SG nach Klemme15 AUS und nach entsprechender MAX Aktivzeit noch aktiv war
alt";
CM_ SG_ 2549088416 NM_SAD2_Subsystemaktiv "Zeigt an ob ein Subsystem des SGs nach Klemme15 AUS und nach entsprechender MAX Aktivzeit noch aktiv war";
CM_ SG_ 2549088416 SAD2_KD_Fehler "Status Kundendienst-Fehlerspeicher";
CM_ SG_ 2549088411 MSBBR_KompSchutz "Funktionseinschränkung aufgrund Komponentenschutz aktiv";
CM_ SG_ 2549088411 MSBBR_Abschaltstufe "Funktionseinschränkung aufgrund aktiver Abschaltstufe";
CM_ SG_ 2549088411 MSBBR_Transport_Mode "Funktionseinschränkung aufgrund aktivem Transport Mode und/oder Transport Schutz";
CM_ SG_ 2549088411 SBBR_Nachlauftyp "Abgebildet wird die von der Hardware vorgegebene Möglichkeit, die Kommunikation nach Klemme 15 = AUS aufrecht zu erhalten. Es wird ein Init-Wert gesendet.
0 = Kommunikation nur bei KL15=EIN (kein Nachlauf, nicht weckfähig)
1 = Kommunikation nach KL15=AU";
CM_ SG_ 2549088411 SBBR_SNI "Das Signal beinhaltet den Source Node Identifier (Knotenadresse, die auch in der Abbildungsvorschrift zur CAN-ID für die NM-High Botschaft verwendet wird).";
CM_ SG_ 2549088411 NM_MSBBR_Wakeup "enthält die Weckursache; stehen mehrere Weckursachen parallel an, dann muss der kleinste Wert übertragen werden";
CM_ SG_ 2549088411 NM_MSBBR_Lokalaktiv "Zeigt an ob das SG nach Klemme15 AUS und nach entsprechender MAX Aktivzeit noch aktiv war
B8";
CM_ SG_ 2549088411 NM_MSBBR_Subsystemaktiv "Zeigt an ob ein Subsystem des SGs nach Klemme15 AUS und nach entsprechender MAX Aktivzeit noch aktiv war";
CM_ SG_ 2549088411 SBBR_KD_Fehler "Status Kundendienst-Fehlerspeicher";
CM_ SG_ 2549088392 Mem_BFSFo_KompSchutz "Funktionseinschränkung aufgrund Komponentenschutz aktiv";
CM_ SG_ 2549088392 Mem_BFSFo_Abschaltstufe "Funktionseinschränkung aufgrund aktiver Abschaltstufe";
CM_ SG_ 2549088392 Mem_BFSFo_Transport_Mode "Funktionseinschränkung aufgrund aktivem Transport Mode und/oder Transport Schutz";
CM_ SG_ 2549088392 Mem_BFSFo_Nachlauftyp "Abgebildet wird die von der Hardware vorgegebene Möglichkeit, die Kommunikation nach Klemme 15 = AUS aufrecht zu erhalten. Es wird ein Init-Wert gesendet.
0 = Kommunikation nur bei KL15=EIN (kein Nachlauf, nicht weckfähig)
1 = Kommunikation nach KL15=AU";
CM_ SG_ 2549088392 Mem_BFSFo_SNI "Das Signal beinhaltet den Source Node Identifier (Knotenadresse, die auch in der Abbildungsvorschrift zur CAN-ID für die NM-High Botschaft verwendet wird).";
CM_ SG_ 2549088392 NM_Mem_BFSFo_Wakeup "enthält die Weckursache; stehen mehrere Weckursachen parallel an, dann muss der kleinste Wert übertragen werden";
CM_ SG_ 2549088392 NM_Mem_BFSFo_Lokalaktiv "Zeigt an ob das SG nach Klemme15 AUS und nach entsprechender MAX Aktivzeit noch aktiv war";
CM_ SG_ 2549088392 NM_Mem_BFSFo_Subsystemaktiv "Zeigt an ob ein Subsystem des SGs nach Klemme15 AUS und nach entsprechender MAX Aktivzeit noch aktiv war";
CM_ SG_ 2549088392 Mem_BFSFo_KD_Fehler "Status Kundendienstfehlerspeichereinträge
";
CM_ SG_ 2549088391 Mem_FSFo_KompSchutz "Funktionseinschränkung aufgrund Komponentenschutz aktiv";
CM_ SG_ 2549088391 Mem_FSFo_Abschaltstufe "Funktionseinschränkung aufgrund aktiver Abschaltstufe";
CM_ SG_ 2549088391 Mem_FSFo_Transport_Mode "Funktionseinschränkung aufgrund aktivem Transport Mode und/oder Transport Schutz";
CM_ SG_ 2549088391 Mem_FSFo_Nachlauftyp "Abgebildet wird die von der Hardware vorgegebene Möglichkeit, die Kommunikation nach Klemme 15 = AUS aufrecht zu erhalten. Es wird ein Init-Wert gesendet.
0 = Kommunikation nur bei KL15=EIN (kein Nachlauf, nicht weckfähig)
1 = Kommunikation nach KL15=AU";
CM_ SG_ 2549088391 Mem_FSFo_SNI "Das Signal beinhaltet den Source Node Identifier (Knotenadresse, die auch in der Abbildungsvorschrift zur CAN-ID für die NM-High Botschaft verwendet wird).";
CM_ SG_ 2549088391 NM_Mem_FSFo_Wakeup "enthält die Weckursache; stehen mehrere Weckursachen parallel an, dann muss der kleinste Wert übertragen werden";
CM_ SG_ 2549088391 NM_Mem_FSFo_Lokalaktiv "Zeigt an ob das SG nach Klemme15 AUS und nach entsprechender MAX Aktivzeit noch aktiv war";
CM_ SG_ 2549088391 NM_Mem_FSFo_Subsystemaktiv "Zeigt an ob ein Subsystem des SGs nach Klemme15 AUS und nach entsprechender MAX Aktivzeit noch aktiv war";
CM_ SG_ 2549088391 Mem_FSFo_KD_Fehler "Status Kundendienstfehlerspeichereinträge
";
CM_ SG_ 2549088405 SitzMem_SR3_KompSchutz "Funktionseinschränkung aufgrund Komponentenschutz aktiv";
CM_ SG_ 2549088405 SitzMem_SR3_Abschaltstufe "Funktionseinschränkung aufgrund aktiver Abschaltstufe";
CM_ SG_ 2549088405 SitzMem_SR3_Transport_Mode "Funktionseinschränkung aufgrund aktivem Transport Mode und/oder Transport Schutz";
CM_ SG_ 2549088405 SitzMem_SR3_Nachlauftyp "Abgebildet wird die von der Hardware vorgegebene Möglichkeit, die Kommunikation nach Klemme 15 = AUS aufrecht zu erhalten. Es wird ein Init-Wert gesendet.
0 = Kommunikation nur bei KL15=EIN (kein Nachlauf, nicht weckfähig)
1 = Kommunikation nach KL15=AU";
CM_ SG_ 2549088405 SitzMem_SR3_SNI "Das Signal beinhaltet den Source Node Identifier (Knotenadresse, die auch in der Abbildungsvorschrift zur CAN-ID für die NM-High Botschaft verwendet wird).";
CM_ SG_ 2549088405 NM_SitzMem_SR3_Wakeup "enthält die Weckursache; stehen mehrere Weckursachen parallel an, dann muss der kleinste Wert übertragen werden";
CM_ SG_ 2549088405 NM_SitzMem_SR3_Lokalaktiv "Zeigt an ob das SG nach Klemme15 AUS und nach entsprechender MAX Aktivzeit noch aktiv war";
CM_ SG_ 2549088405 NM_SitzMem_SR3_Subsystemaktiv "Zeigt an ob ein Subsystem des SGs nach Klemme15 AUS und nach entsprechender MAX Aktivzeit noch aktiv war";
CM_ SG_ 2549088405 SitzMem_SR3_KD_Fehler "Status Kundendienstfehlerspeichereinträge
";
CM_ SG_ 2549088333 Sitzmemo_BFS_KompSchutz "Funktionseinschränkung aufgrund Komponentenschutz aktiv";
CM_ SG_ 2549088333 Sitzmemo_BFS_Abschaltstufe "Funktionseinschränkung aufgrund aktiver Abschaltstufe";
CM_ SG_ 2549088333 Sitzmemo_BFS_Transport_Mode "Funktionseinschränkung aufgrund aktivem Transport Mode und/oder Transport Schutz";
CM_ SG_ 2549088333 Sitzmemo_BFS_Nachlauftyp "Abgebildet wird die von der Hardware vorgegebene Möglichkeit, die Kommunikation nach Klemme 15 = AUS aufrecht zu erhalten. Es wird ein Init-Wert gesendet.
0 = Kommunikation nur bei KL15=EIN (kein Nachlauf, nicht weckfähig)
1 = Kommunikation nach KL15=AU";
CM_ SG_ 2549088333 Sitzmemo_BFS_SNI "Das Signal beinhaltet den Source Node Identifier (Knotenadresse, die auch in der Abbildungsvorschrift zur CAN-ID für die NM-High Botschaft verwendet wird).";
CM_ SG_ 2549088333 NM_Sitzmemo_BFS_Wakeup "enthält die Weckursache; stehen mehrere Weckursachen parallel an, dann muss der kleinste Wert übertragen werden";
CM_ SG_ 2549088333 NM_Sitzmemo_BFS_Subsystemaktiv "Zeigt an ob ein Subsystem des SGs nach Klemme15 AUS und nach entsprechender MAX Aktivzeit noch aktiv war";
CM_ SG_ 2549088333 NM_Sitzmemo_BFS_Lokalaktiv "Zeigt an ob das SG nach Klemme15 AUS und nach entsprechender MAX Aktivzeit noch aktiv war";
CM_ SG_ 2549088333 Mem_BFS_KD_Fehler "Status Kundendienstfehlerspeichereinträge
";
CM_ SG_ 2549088332 Sitzmemo_FS_KompSchutz "Funktionseinschränkung aufgrund Komponentenschutz aktiv";
CM_ SG_ 2549088332 Sitzmemo_FS_Abschaltstufe "Funktionseinschränkung aufgrund aktiver Abschaltstufe";
CM_ SG_ 2549088332 Sitzmemo_FS_Transport_Mode "Funktionseinschränkung aufgrund aktivem Transport Mode und/oder Transport Schutz";
CM_ SG_ 2549088332 Sitzmemo_FS_Nachlauftyp "Abgebildet wird die von der Hardware vorgegebene Möglichkeit, die Kommunikation nach Klemme 15 = AUS aufrecht zu erhalten. Es wird ein Init-Wert gesendet.
0 = Kommunikation nur bei KL15=EIN (kein Nachlauf, nicht weckfähig)
1 = Kommunikation nach KL15=AU";
CM_ SG_ 2549088332 Sitzmemo_FS_SNI "Das Signal beinhaltet den Source Node Identifier (Knotenadresse, die auch in der Abbildungsvorschrift zur CAN-ID für die NM-High Botschaft verwendet wird).";
CM_ SG_ 2549088332 NM_Sitzmemo_FS_Wakeup "enthält die Weckursache; stehen mehrere Weckursachen parallel an, dann muss der kleinste Wert übertragen werden";
CM_ SG_ 2549088332 NM_Sitzmemo_FS_Lokalaktiv "Zeigt an ob das SG nach Klemme15 AUS und nach entsprechender MAX Aktivzeit noch aktiv war";
CM_ SG_ 2549088332 NM_Sitzmemo_FS_Subsystemaktiv "Zeigt an ob ein Subsystem des SGs nach Klemme15 AUS und nach entsprechender MAX Aktivzeit noch aktiv war";
CM_ SG_ 2549088332 Mem_FS_KD_Fehler "Status Kundendienstfehlerspeichereinträge
";
CM_ SG_ 2549088292 SpoilerSG_KompSchutz "Funktionseinschränkung aufgrund Komponentenschutz aktiv";
CM_ SG_ 2549088292 SpoilerSG_Abschaltstufe "Funktionseinschränkung aufgrund aktiver Abschaltstufe";
CM_ SG_ 2549088292 SpoilerSG_Transport_Mode "Funktionseinschränkung aufgrund aktivem Transport Mode und/oder Transport Schutz";
CM_ SG_ 2549088292 SpoilerSG_Nachlauftyp "Abgebildet wird die von der Hardware vorgegebene Möglichkeit, die Kommunikation nach Klemme 15 = AUS aufrecht zu erhalten. Es wird ein Init-Wert gesendet.
0 = Kommunikation nur bei KL15=EIN (kein Nachlauf, nicht weckfähig)
1 = Kommunikation nach KL15=AU";
CM_ SG_ 2549088292 SpoilerSG_SNI "Das Signal beinhaltet den Source Node Identifier (Knotenadresse, die auch in der Abbildungsvorschrift zur CAN-ID für die NM-High Botschaft verwendet wird).";
CM_ SG_ 2549088292 NM_SpoilerSG_Wakeup "enthält die Weckursache; stehen mehrere Weckursachen parallel an, dann muss der kleinste Wert übertragen werden";
CM_ SG_ 2549088292 KN_SpoilerSG_ECUKnockOut "Ausgabe des ECUKnockout-Status in der Knotenbotschaft";
CM_ SG_ 2549088292 KN_SpoilerSG_WakePrevention "Ausgabe des WakePrevention-Status in der Knotenbotschaft";
CM_ SG_ 2549088292 NM_SpoilerSG_Lokalaktiv "Zeigt an ob das SG nach Klemme15 AUS und nach entsprechender MAX Aktivzeit noch aktiv war
B8";
CM_ SG_ 2549088292 NM_SpoilerSG_Subsystemaktiv "Zeigt an ob ein Subsystem des SGs nach Klemme15 AUS und nach entsprechender MAX Aktivzeit noch aktiv war";
CM_ SG_ 2549088292 SpoilerSG_KD_Fehler "Status Kundendienstfehlerspeichereinträge
";
CM_ SG_ 2549088299 STS_KompSchutz "Funktionseinschränkung aufgrund Komponentenschutz aktiv";
CM_ SG_ 2549088299 STS_Abschaltstufe "Funktionseinschränkung aufgrund aktiver Abschaltstufe";
CM_ SG_ 2549088299 STS_Transport_Mode "Funktionseinschränkung aufgrund aktivem Transport Mode und/oder Transport Schutz";
CM_ SG_ 2549088299 STS_Nachlauftyp "Abgebildet wird die von der Hardware vorgegebene Möglichkeit, die Kommunikation nach Klemme 15 = AUS aufrecht zu erhalten. Es wird ein Init-Wert gesendet.
0 = Kommunikation nur bei KL15=EIN (kein Nachlauf, nicht weckfähig)
1 = Kommunikation nach KL15=AU";
CM_ SG_ 2549088299 STS_SNI "Das Signal beinhaltet den Source Node Identifier (Knotenadresse, die auch in der Abbildungsvorschrift zur CAN-ID für die NM-High Botschaft verwendet wird).";
CM_ SG_ 2549088299 KN_VTS_BusKnockOutTimer "Ausgabe des BusKnockOut-Timer in der Knotenbotschaft";
CM_ SG_ 2549088299 NM_STS_Wakeup "enthält die Weckursache; stehen mehrere Weckursachen parallel an, dann muss der kleinste Wert übertragen werden";
CM_ SG_ 2549088299 KN_VTS_ECUKnockOut "Ausgabe des ECUKnockout-Status in der Knotenbotschaft";
CM_ SG_ 2549088299 KN_VTS_WakePrevention "Ausgabe des WakePrevention-Status in der Knotenbotschaft";
CM_ SG_ 2549088299 NM_STS_Lokalaktiv "Zeigt an ob das SG nach Klemme15 AUS und nach entsprechender MAX Aktivzeit noch aktiv war
alt";
CM_ SG_ 2549088299 NM_STS_Subsystemaktiv "Zeigt an ob ein Subsystem des SGs nach Klemme15 AUS und nach entsprechender MAX Aktivzeit noch aktiv war";
CM_ SG_ 2549088299 STS_KD_Fehler "Status Kundendienstfehlerspeichereinträge
";
CM_ SG_ 2549088331 TSG_BFS_KompSchutz "Funktionseinschränkung aufgrund Komponentenschutz aktiv";
CM_ SG_ 2549088331 TSG_BFS_Abschaltstufe "Funktionseinschränkung aufgrund aktiver Abschaltstufe";
CM_ SG_ 2549088331 TSG_BFS_Transport_Mode "Funktionseinschränkung aufgrund aktivem Transport Mode und/oder Transport Schutz";
CM_ SG_ 2549088331 TSG_BFS_Nachlauftyp "Abgebildet wird die von der Hardware vorgegebene Möglichkeit, die Kommunikation nach Klemme 15 = AUS aufrecht zu erhalten. Es wird ein Init-Wert gesendet.
0 = Kommunikation nur bei KL15=EIN (kein Nachlauf, nicht weckfähig)
1 = Kommunikation nach KL15=AU";
CM_ SG_ 2549088331 TSG_BFS_SNI "Das Signal beinhaltet den Source Node Identifier (Knotenadresse, die auch in der Abbildungsvorschrift zur CAN-ID für die NM-High Botschaft verwendet wird).";
CM_ SG_ 2549088331 KN_TSG_BFS_BusKnockOutTimer "Ausgabe des BusKnockOut-Timer in der Knotenbotschaft";
CM_ SG_ 2549088331 NM_TSG_BFS_Wakeup "enthält die Weckursache; stehen mehrere Weckursachen parallel an, dann muss der kleinste Wert übertragen werden";
CM_ SG_ 2549088331 KN_TSG_BFS_ECUKnockOut "Ausgabe des ECUKnockout-Status in der Knotenbotschaft";
CM_ SG_ 2549088331 KN_TSG_BFS_WakePrevention "Ausgabe des WakePrevention-Status in der Knotenbotschaft";
CM_ SG_ 2549088331 NM_TSG_BFS_Lokalaktiv "Zeigt an ob das SG nach Klemme15 AUS und nach entsprechender MAX Aktivzeit noch aktiv war";
CM_ SG_ 2549088331 NM_TSG_BFS_Subsystemaktiv "Zeigt an ob ein Subsystem des SGs nach Klemme15 AUS und nach entsprechender MAX Aktivzeit noch aktiv war";
CM_ SG_ 2549088331 TSG_BFS_KD_Fehler "Status Kundendienstfehlerspeichereinträge
";
CM_ SG_ 2549088330 TSG_FS_KompSchutz "Funktionseinschränkung aufgrund Komponentenschutz aktiv";
CM_ SG_ 2549088330 TSG_FS_Abschaltstufe "Funktionseinschränkung aufgrund aktiver Abschaltstufe";
CM_ SG_ 2549088330 TSG_FS_Transport_Mode "Funktionseinschränkung aufgrund aktivem Transport Mode und/oder Transport Schutz";
CM_ SG_ 2549088330 TSG_FS_Nachlauftyp "Abgebildet wird die von der Hardware vorgegebene Möglichkeit, die Kommunikation nach Klemme 15 = AUS aufrecht zu erhalten. Es wird ein Init-Wert gesendet.
0 = Kommunikation nur bei KL15=EIN (kein Nachlauf, nicht weckfähig)
1 = Kommunikation nach KL15=AU";
CM_ SG_ 2549088330 TSG_FS_SNI "Das Signal beinhaltet den Source Node Identifier (Knotenadresse, die auch in der Abbildungsvorschrift zur CAN-ID für die NM-High Botschaft verwendet wird).";
CM_ SG_ 2549088330 KN_TSG_FS_BusKnockOutTimer "Ausgabe des BusKnockOut-Timer in der Knotenbotschaft";
CM_ SG_ 2549088330 NM_TSG_FS_Wakeup "enthält die Weckursache; stehen mehrere Weckursachen parallel an, dann muss der kleinste Wert übertragen werden";
CM_ SG_ 2549088330 KN_TSG_FS_ECUKnockOut "Ausgabe des ECUKnockout-Status in der Knotenbotschaft";
CM_ SG_ 2549088330 KN_TSG_FS_WakePrevention "Ausgabe des WakePrevention-Status in der Knotenbotschaft";
CM_ SG_ 2549088330 NM_TSG_FS_Lokalaktiv "Zeigt an ob das SG nach Klemme15 AUS und nach entsprechender MAX Aktivzeit noch aktiv war";
CM_ SG_ 2549088330 NM_TSG_FS_Subsystemaktiv "Zeigt an ob ein Subsystem des SGs nach Klemme15 AUS und nach entsprechender MAX Aktivzeit noch aktiv war";
CM_ SG_ 2549088330 TSG_FS_KD_Fehler "Status Kundendienstfehlerspeichereinträge
";
CM_ SG_ 2549088301 VSG_KompSchutz "Funktionseinschränkung aufgrund Komponentenschutz aktiv";
CM_ SG_ 2549088301 VSG_Abschaltstufe "Funktionseinschränkung aufgrund aktiver Abschaltstufe";
CM_ SG_ 2549088301 VSG_Transport_Mode "Funktionseinschränkung aufgrund aktivem Transport Mode und/oder Transport Schutz";
CM_ SG_ 2549088301 VSG_Nachlauftyp "Abgebildet wird die von der Hardware vorgegebene Möglichkeit, die Kommunikation nach Klemme 15 = AUS aufrecht zu erhalten. Es wird ein Init-Wert gesendet.
0 = Kommunikation nur bei KL15=EIN (kein Nachlauf, nicht weckfähig)
1 = Kommunikation nach KL15=AU";
CM_ SG_ 2549088301 VSG_SNI "Das Signal beinhaltet den Source Node Identifier (Knotenadresse, die auch in der Abbildungsvorschrift zur CAN-ID für die NM-High Botschaft verwendet wird).";
CM_ SG_ 2549088301 KN_VSG_BusKnockOutTimer "Ausgabe des BusKnockOut-Timer in der Knotenbotschaft";
CM_ SG_ 2549088301 NM_VSG_Wakeup "enthält die Weckursache; stehen mehrere Weckursachen parallel an, dann muss der kleinste Wert übertragen werden";
CM_ SG_ 2549088301 NM_VSG_Lokalaktiv "Zeigt an ob das SG nach Klemme15 AUS und nach entsprechender MAX Aktivzeit noch aktiv war";
CM_ SG_ 2549088301 NM_VSG_Subsystemaktiv "Zeigt an ob ein Subsystem des SGs nach Klemme15 AUS und nach entsprechender MAX Aktivzeit noch aktiv war";
CM_ SG_ 2549088301 VSG_KD_Fehler "Status Kundendienstfehlerspeichereinträge
";
CM_ BO_ 779 "MQB";
CM_ SG_ 779 KBI_ABS_Lampe "ABS-Sicherheits-Lampe wurde eingeschaltet.";
CM_ SG_ 779 KBI_ESP_Lampe "ESP-Sicherheits-Lampe wurde eingeschaltet ";
CM_ SG_ 779 KBI_BKL_Lampe "Sicherheits-Lampe Bremskontrolle wurde eingeschaltet;
";
CM_ SG_ 779 KBI_Airbag_Lampe "Airbag Sicherheits-Lampe wurde eingeschaltet ";
CM_ SG_ 779 KBI_SILA_gueltig "Rückmeldeinformation (Bit 1-6) ist gültig";
CM_ SG_ 779 KBI_Lenkung_Lampe "Sicherheits-Lampe der Lenkung (Lenkhilfe EPS, Audi-Dynamic-Steering ...) wurde eingeschaltet.

0x0 = Lenkungs-Lampe aus
0x1 = Lenkungs-Lampe ein";
CM_ SG_ 779 KBI_Vorglueh_System_Lampe "Rückmeldung der Vorglühlampe bzw. Motor Systemlampe (MO_Systemlampe) an den Motor (bei Diesel und Otto!). Hardwaremässig gleiche LED im Kombi (EPC- oder Glühwendel), Unterscheidung nur über Ziffernblatt.";
CM_ SG_ 779 KBI_NV_in_Anzeige "Das Bit gibt dem NV die Information, ob NV-Bild im Kombi in der Anzeige ist. (Information ist notwendig um Kontrasverstellungen nur dann zuzulassen, wenn der Fahrer das Feedback über das  Kombidisplay bekommt.)";
CM_ SG_ 779 KBI_Anzeigestatus_ACC "Status der ACC-Anzeige im nicht permanenten Displaybereich";
CM_ SG_ 779 KBI_Anzeigestatus_GRA "Anzeigestatus der GRA High Wunschgeschwindigkeitsanzeige im Kombiinstrument.
Bei VW bedeutet 'nicht vorhanden' GRA-low fähig (LED immer verbaut).
0 = nicht vorhanden
1 = Wunschgeschwindigkeits-Anzeigemöglichkeit vorhanden
2 = reserviert
3 = Fehler (B";
CM_ SG_ 779 KBI_Oeldruck_Schalter "Das Signal bildet den Status des Öldrucks über den am Kombi angeschlossenen Öldruckschalter ab.";
CM_ SG_ 779 KBI_Tankwarnung "Fahrer wird gewarnt, dass er den Reservebereich erreicht hat. Fzg.spezifische Warnschwelle";
CM_ SG_ 779 KBI_MFA_v_Einheit_01 "Einheit der Geschwindigkeit, die vom Fahrer im Car-Menü gewählt wurde. Veränderliche Grösse, im Gegensatz zur Einheit des Tachokranzes.";
CM_ SG_ 779 KBI_im_Stellgliedtest "Kombi im Stellgliedtest, Signal muss eingelesen werden, um Fehlfunktion aufgrund der Bewegung der Stellglieder (Drehzahlmesser, Tacho) des Kombis zu verhindern";
CM_ SG_ 779 KBI_Oeldruckwarnung "Öldruckwarnung im Kombi aktiv";
CM_ SG_ 779 KBI_Handbremse "Handbremsen-Information vom Kombi.
Das Signal bezieht sich ausschließlich auf den Zustand der konventionellen Handbremse.";
CM_ SG_ 779 KBI_V_Digital "Ausgabe der im Kombi angezeigten digitalen Geschwindigkeit.

Einheit ist im KBI_MFA_v_Einheit_01 definiert";
CM_ SG_ 779 KBI_PLA_in_Anzeige "Das Signal wird als aktive Rückmeldung genutzt, ob die Info des PLA im Kombi angezeigt wird. Wenn nach Anforderung des Displays das Signal zweimal auf 0 ist, wird der Parkvorgang abgebrochen.
Ein Kombi, dass PLA Anzeige nicht unterstützt, schickt dauerha";
CM_ SG_ 779 KBI_Anzeigefehler_NV "Über dieses Signal teilt das Kombiinstrument dem Nightvision-Steuergerät mit, dass ein Fehler vom Kombiinstrument diagnostiziert wurde, der zur Abschaltung der Nightvision-Funktion führen muss.";
CM_ SG_ 779 KBI_Anzeigestatus_LIM "Anzeigestatus der Speedlimiter Wunschgeschwindigkeitsanzeige im Kombiinstrument (permanenter Anzeigebereich)
0 = nicht vorhanden
1 = Wunschgeschwindigkeits-Anzeigemöglichkeit vorhanden
2 = reserviert
3 = Fehler (Botschaftsüberwachung, Timeout, Akustik";
CM_ SG_ 779 KBI_ARA_in_Anzeige "Anzeige von ARA im Kombi aktiv";
CM_ SG_ 779 KBI_angez_Geschw "Im Tacho angezeigte Geschwindigkeit inklusive der Voreilung

";
CM_ SG_ 779 KBI_Einheit_Tacho "Information, ob es sich um Meilen- oder Kmh-Kombi handelt, Einheit des Tachos entspricht dem Zifferblatt, Grösse ist nicht veränderlich";
CM_ SG_ 779 KBI_Konsistenz_ACC "Rückmeldung an ACC, dass die Botschaften zur Ansteuerung von Anzeigen nicht bzw. nicht konsistent empfangen wurden (Timeout-, BZ-, CHK- und DLC-Fehler)                                                                                                        ";
CM_ SG_ 779 KBI_Fehler_Anzeige_ACC "Rückmeldung an ACC, dass mindestens eine der ACC-relevanten Anzeigen -rote Fahrerübernahme, Mitteldisplay, Gong - fehlerhaft sind.";
CM_ SG_ 779 KBI_Anzeigefehler_SWA "Signal bezieht sich nur auf die SWA-Lampe, Vorhalt für Kombis mit SWA-Lampe. ";
CM_ SG_ 1719 KBI_Kilometerstand "Fehler wird ausgegeben, falls Kilometerstand nicht restaurierbar
";
CM_ SG_ 1719 KBI_Standzeit_02 "Zähler welcher die Standzeit des Motors wiedergibt.
Das Signal beschreibt den Anteil der Motor-Standzeit zwischen Zündung aus und nächstem Motorstart.";
CM_ SG_ 1719 KBI_Reserve_Warnung_Sek "Signalisiert die Reservewarnung für die Energiespeicher CNG, LPG, HV-Batterie.
Fahrer wird gewarnt, dass er den Reservebereich erreicht hat. Fzg.spezifische Warnschwelle.";
CM_ SG_ 1719 KBI_RDK_Kalibrier_Anf "Bei gesetztem Bit soll die RDK die aktuellen Istdrücke zu Solldrücken übernehmen (nur bei Nichtverbau einer Headunit erforderlich).";
CM_ SG_ 1719 KBI_Inhalt_Tank "Restmenge 2 bzw. 2,5l nicht auflösbar

";
CM_ SG_ 1719 KBI_FStatus_Tank "Signal wird gesetzt:

a) Während der Fehlerentprellzeit (20 s Entprellung)

b) Bei erkanntem Fehler wird der Tankinhalt während der laufenden KL15-Phase über den 
    Verbrauch zurückgerechnet. In dieser Zeit ist das Bit ebenfalls gesetzt. Nach einem";
CM_ SG_ 1719 KBI_Oelwechsel_durchgefuehrt "Nach einen Ölwechsel (Service) ist die Ethanol Warmfahrwarnung zu unterdrücken.";
CM_ SG_ 1719 KBI_QBit_Aussen_Temp_gef "0x0 = gültiger Wert
0x1 = Ersatz-, Init- oder Fehlerwert";
CM_ SG_ 1720 KBI_Reifenumfang "Mittlerer Radumfang aus der K-Zahl gerechnet in Millimeter.  Byte 2 Bit 5,4 reserviert, Byte 2 Bit 3..0 und Byte 1 Bit 7..0; Wertebereich 0..4096 mm
";
CM_ SG_ 1720 KBI_Variante_USA "In diesem Signal wird die HW-Variante des Kombis ausgegeben, ACC plausibilisiert auf dieses Signal hin seine US-Codierung";
CM_ SG_ 1720 KBI_Variante "Zeigt an ob es sich um ein konventionelles Zeiger-Kombiinstrument handelt oder um eine Volldisplay-Kombiinstrument";
CM_ SG_ 1720 KBI_BCmE_aktiv "Anzeige BCmE aktiv (BCmE-Screen oder Einsparhinweis in der Anzeige)";
CM_ SG_ 1720 KBI_Sparhinweis_quittiert "angezeigter Sparhinweis ist quittiert. Signal wird nach zwei Sendebotschaften wieder auf '0' gesetzt.";
CM_ SG_ 1720 KBI_Tankfuellstand_Prozent "Tankfüllstand in %";
CM_ SG_ 1720 KBI_Nachtanken_erkannt "Statusinformation Nachtankmodus";
CM_ SG_ 1720 KBI_Tankinhalt_hochaufl "angezeigter Tankinhalt hochauflösend zur Restreichweitenberechnung";
CM_ SG_ 1720 KBI_Max_Tankinhalt "Mitteilung des maximalen Tankinhalts an das Reichweitenmodul";
CM_ SG_ 1720 KBI_Reifenumfang_Sekundaer "Fahrzeuge mit unterschiedlichen Reifenumfängen Vorderachse / Hinterachse:

Primärachse: KBI_Reifenumfang
Sekundärachse: KBI_Reifenumfang_Sekundaer
";
CM_ SG_ 1724 KBI_Oil_dis_status "Ölwechselstatus Distanz:";
CM_ SG_ 1724 KBI_Oil_dis_unit "Einheit Distanz bis zum Ölwechsel:";
CM_ SG_ 1724 KBI_Oil_dis "Distanz bis zum Ölwechsel:

Einheitenloser Wert. Einheit im Signal 'KBI_Oil_distance_unit'";
CM_ SG_ 1724 KBI_Oil_time_status "Ölwechselstatus Zeit:";
CM_ SG_ 1724 KBI_Oil_time "Zeit bis zum Ölwechsel:

Angabe in Tagen";
CM_ SG_ 1724 KBI_Insp_dis_status "Einheit Distanz bis zur Inspektion:";
CM_ SG_ 1724 KBI_Insp_dis_unit "Einheit Distanz bis zur Inspektion:";
CM_ SG_ 1724 KBI_Insp_dis "Distanz bis zur Inspektion:

Einheitenloser Wert. Einheit im Signal 'KBI_Inspection_distance_unit'";
CM_ SG_ 1724 KBI_Insp_time_status "Inspektionsstatus Zeit:";
CM_ SG_ 1724 KBI_Insp_time "Zeit bis zur Inspektion:

Angabe in Tagen";
CM_ SG_ 1724 KBI_Warnung_ID "ID, die einer Warnung im Kombi entspricht und entsprechend der Anzeige im Kombi gesetzt wird.";
CM_ SG_ 2589283471 KBI_Signatur_Wegstrecke_01 "Signatur_01 der Wegstreckendaten des Kombiinstruments";
CM_ SG_ 2589283471 KBI_Status_Aktive_Meldungen "Signalisiert im Kombi eine Änderung im Servicekey 3 Messwerteblock für aktive Meldungen  ";
CM_ SG_ 2589283471 KBI_Status_Historie_Meldungen "Signalisiert im Kombi eine Änderung im Servicekey 3 Messwerteblock für Historie Meldungen  ";
CM_ SG_ 2589283471 KBI_Status_SK_Meldungen "Signalisiert im Kombi eine Änderung im Servicekey 3 Messwerteblock für Servicekey Meldungen  ";
CM_ SG_ 2589283471 KBI_Wegstrecke "Kilometerstand des Kombis zu Wegstreckensicherheitszwecken";
CM_ SG_ 2589283471 KBI_Signatur_Wegstrecke_02 "Signatur_02 der Wegstreckendaten des Kombiinstruments";
CM_ SG_ 2549874958 KS_BCM1_Req_Data "Komponentenschutz (Funktion 01h). Request mit NA des Slaves.";
CM_ SG_ 2550006030 KS_BCM1_Resp_Data "Komponentenschutz (Funktion 01h). Response mit eigener NA.";
CM_ SG_ 2549875083 KS_BCM2_Req_Data "Komponentenschutz (Funktion 01h). Request mit NA des Slaves.";
CM_ SG_ 2550006155 KS_BCM2_Resp_Data "Komponentenschutz (Funktion 01h). Response mit eigener NA.";
CM_ BO_ 919 "ab MQB ohne CHK/BZ, LDW_SW_Warnung_links/rechts, KD-Fehler und mit Zyklus 100ms";
CM_ SG_ 919 LDW_Gong "Löst ein definiertes akustisches Signal aus.";
CM_ SG_ 919 LDW_Frueh_Spaet "Im MMI eingestellter, aktiver Lenkeingriffszeitpunkt:
0: frueh, frueh aktiv
1: frueh, spaet aktiv
2: spaet, spaet aktiv
3: Fehler";
CM_ SG_ 919 LDW_Texte "Bei Anzeige eines Fehlertextes im Kombi ertönt ein akustisches Signal";
CM_ SG_ 919 LDW_Seite_DLCTLC "Zuordnung auf welche Seite sich LDW_DLC bzw. LDW_TLC beziehen";
CM_ SG_ 919 LDW_Lernmodus "Signal dient zur Ansteuerung von Funktionsanzeigen im Mitteldisplay des Kombiinstruments (neue Funktion im MLB)";
CM_ SG_ 919 LDW_Lernmodus_seitenabhaengig "Signal dient zur Ansteuerung von Funktionsanzeigen im Mitteldisplay des Kombiinstruments für die Seitenabhänige Liniendetektion (neue Funktion ab D4)";
CM_ SG_ 919 LDW_DLC "distance to line, Abstand vom Fahrzeug zur Fahrbahnmarkierung
Der Wert gibt die Breite der Restspur zur Linie wieder (Abstand vom Fahrzeugäußerem zur Linie) (Wert POSITIV wenn Fahrzeug in der Spur - Wert NEGATIV wenn Fahrzeug über der Linie)";
CM_ SG_ 919 LDW_TLC "time to line, Zeit bis das Fahrzeug die Fahrbahnmarkierung überquert";
CM_ SG_ 919 HC_Uss_Anforderung "Ansteuerung der vorderen PLA (VLS, VRS) und APS Sensoren (VL, VR)
0 = Ultraschallsensoren Aus
1 = Ultraschallsensoren An";
CM_ SG_ 919 EA_Warnblinken "Anforderung Warnblinken durch Funktion Emergency Alert";
CM_ SG_ 919 LDW_Codierinfo_fuer_VLR "Vorhalt LDW-Codierinfo";
CM_ SG_ 919 LDW_Status_LED_gruen " ";
CM_ BO_ 810 "MQB: 50ms (für CAN-SG), geändertes Charisma, Entfall KD-Fehler";
CM_ SG_ 810 EPS_01_CRC "Für MLB:
'Berechnung siehe Lastenheft 'Kommunikationsabsicherung für FlexRay und CAN''

Ab MQB und MLBevo:
'Berechnung siehe Lastenheft 'End-to-End Kommunikationsabsicherung''

Endwerte siehe Begleitdokument 'S-PDU Kennungsfolgen'
";
CM_ SG_ 810 EPS_SpannungsAnf "Forderung des EPS-SG's zur Spannungsanhebung.";
CM_ SG_ 810 EPS_Fehlerlampe "Steuert direkt die Fehlerlampe Lenkhilfe (gelb); kein Aufprüfen bei Neustart, keine Rückleseinformation in Kombi-Botschaft (nur für VW526 Hybrid)";
CM_ SG_ 810 EPS_Warnungen "Diese Bits werden verwendet, um im Kombi Texte, Lampen oder Bilder für die Lenkhilfe darzustellen
Audi MLB/RSe:
Text_1: Lenkung defekt (Prio 1)
Text_2: Lenkung Systemstörung (Prio 2)
VW526:
Text_1 (ID_TXT_1026.1): Ausfall Lenkunterstützung
Text_2 (I";
CM_ SG_ 810 EPS_PWR_Abbruch "Dieses Signal gibt das Abbruchkriterium für PLA und ARA an.";
CM_ SG_ 810 EPS_PWR_Fehler "Gibt den Fehler aus wenn eine Lenkwinkelanforderung nicht ausgeführt werden konnte.";
CM_ SG_ 810 EPS_PLA_Status "Zustand der Statusmaschine der EPS für die korrespondierenden Statusmaschine im PLA.";
CM_ SG_ 810 EPS_Charisma_FahrPr "MLBevo: Aktuelles Fahrprogramm des Charisma-Teilnehmers (siehe Systemlastenheft Drive Select)
MQB: Istwert der Kennlinie (siehe Systemlastenheft MQB FPA)";
CM_ SG_ 810 EPS_Charisma_Status "Rückmeldung an den Charisma-Master

Wert 0x3 ist nur für Fahrzeuge ab MQB relevant";
CM_ SG_ 810 EPS_Lenkerposition "Position des Lenkers im Fahrzeug";
CM_ SG_ 810 EPS_Anf_KL "Nach Überschreiten einer oberen Grenztemperatur innerhalb des Steuergerätes der Lenkhilfe fordert die EPS die Zuschaltung einer externen Kühlung durch den Kühlerlüfter an.
Es besteht kein technischer Zusammenhang mit einer Batterie_ab - Erkennung in der ";
CM_ SG_ 810 EPS_ARA_Status "Anforderung vom Anhängerrangierassistent. 
16 Statuswerte";
CM_ SG_ 160 EPS_04_CRC "Für MLB:
'Berechnung siehe Lastenheft 'Kommunikationsabsicherung für FlexRay und CAN''

Ab MQB und MLBevo:
'Berechnung siehe Lastenheft 'End-to-End Kommunikationsabsicherung''

Endwerte siehe Begleitdokument 'S-PDU Kennungsfolgen'";
CM_ SG_ 160 EPS_04_BZ "Botschaftszähler";
CM_ SG_ 160 EPS_Lenkmoment_AbsReduz "Gibt den Absolutwert des aktuelle Handlenkmoment mit einer Auflösung von 0 ,62 Nm aus";
CM_ SG_ 160 EPS_Zahnstangen_Pos "Position/Verschiebung der Zahnstange bzgl. Lenkungsmitte";
CM_ SG_ 160 EPS_VZ_Zahnstangenposition "Vorzeichen der Position/Verschiebung der Zahnstange bzgl. Lenkungsmitte
Vorzeichen:
(Fahreransicht: positiv = links von der Nullstellung des Lenkrades)
Nullstellung = +0mm";
CM_ SG_ 160 EPS_QBit_Zahnstangen_Pos "beschreibt die Qualität/Vertrauenswürdigkeit der Zahnstangenposition";
CM_ SG_ 160 EPS_Versorgungsstatus "Erkennung Störung im Versorgungspfad
";
CM_ SG_ 160 EPS_Versorgungsspannung "Gibt die am Steuergerät anliegende Spannung aus.
";
CM_ SG_ 160 EPS_AWA_Status "beschreibt den Status der AWA-Funktion im EPS-Steuergerät. (Ausweich-Assistent)";
CM_ SG_ 160 EPS_STA_Status "beschreibt den Status der STA-Funktion im EPS-Steuergerät. (Stauassistent)";
CM_ SG_ 981 Licht_Anf_01_CRC "Für MLB:
'Berechnung siehe Lastenheft 'Kommunikationsabsicherung für FlexRay und CAN''

Ab MQB und MLBevo:
'Berechnung siehe Lastenheft 'End-to-End Kommunikationsabsicherung''

Endwerte siehe Begleitdokument 'S-PDU Kennungsfolgen'";
CM_ SG_ 981 Licht_Anf_01_BZ "4bit Botschaftszaehler, wird mit jeder Sendebotschaft inkrementiert";
CM_ SG_ 981 BCM1_Kurvenlicht_links_Anf "Ansteuerung linkes Kurvenlicht/Abbiegelicht duch BCM1";
CM_ SG_ 981 BCM1_Kurvenlicht_rechts_Anf "Ansteuerung rechtes Kurvenlicht/Abbiegelicht duch BCM1";
CM_ SG_ 981 BCM1_Standlicht_Anf "Anforderung: Schlusslicht (Sollzustand)";
CM_ SG_ 981 BCM1_Abblendlicht_Anf "Anforderung Abblendlicht
";
CM_ SG_ 981 BCM1_Fernlicht_Anf "Anforderung Fernlicht
";
CM_ SG_ 981 BCM1_Nebellicht_Anf "Anforderung Nebellicht
";
CM_ SG_ 981 BCM1_Parklicht_li_Anf "Anforderung: Parklicht links (Sollzustand)
";
CM_ SG_ 981 BCM1_Parklicht_re_Anf "Anforderung: Parklicht rechts (Sollzustand)
";
CM_ SG_ 981 BCM1_Nebelschluss_Ahg_Anf "Anforderung: Nebelschlusslicht Anhänger (Sollzustand)
";
CM_ SG_ 981 BCM1_Nebelschluss_Fzg_Anf "Anforderung: Nebelschlusslicht Fahrzeug (Sollzustand)
";
CM_ SG_ 981 BCM1_Schlusslicht_Anf "Anforderung: Schlusslicht Fahrzeug (Sollzustand)
";
CM_ SG_ 981 BCM_Rueckfahrlicht_Anf "Anforderung Rückfahrlicht (Sollzustand). 
Das Signal wird entprellt (typisch 400ms) und bei KL15EIN gesendet. Das Signal ist unabhängig von der Position des Heckdeckels (kein Überhitzungsschutz).";
CM_ SG_ 981 BCM1_Umfeldleuchten_Anf "Anforderung für Umfeldleuchten";
CM_ SG_ 981 BCM1_Tagfahrlicht_Anf "Anforderung: Tagfahrlicht (Sollzustand)";
CM_ SG_ 981 BCM1_Regenlicht_Anf "Anforderung: Regenlicht (Sollzustand)
";
CM_ SG_ 981 BCM1_Autobahnlicht_Anf "Anforderung Autobahnlicht
";
CM_ SG_ 981 BCM1_Touristen_Licht_Anf "Anforderung: Touristenlicht (Sollzustand)";
CM_ SG_ 981 BCM1_Gleitende_Leuchtw_Anf "Funktion 'Gleitende Leuchtweite' im AFS-SG  freischalten";
CM_ SG_ 981 BCM1_GLW_Fernlicht_Anf "Harte Fernlichtanforderung von BCM1 an die Funktion 'gleitende Leuchtweite' im AFS-SG";
CM_ SG_ 981 BCM1_Adaptive_Lichtvert_Anf "Funktion 'Adaptive Lichtverteilung' im AFS-SG  Ein- und Ausschalten";
CM_ SG_ 981 BCM1_CH_LH_aktiv "Status Comming / Leaving Home
";
CM_ SG_ 981 BCM1_Allwetterlicht_Anf "Anforderung eines Allwetterlichts (über AFS-SG realisiert): Licht für schlechte Sichtverhältnisse";
CM_ BO_ 982 "MQB";
CM_ SG_ 982 BCM2_Bremsl_durch_ECD "Bremslicht (ECD-Bremsung)
";
CM_ SG_ 982 LH_Aussenlicht_def "Aussenlicht kann nicht mehr korrekt angesteuert werden (EEPROM Codierung kann nicht mehr ausgelesen werden)
";
CM_ SG_ 982 LH_Standlicht_H_aktiv "Standlicht hinten
";
CM_ SG_ 982 LH_Parklicht_HL_aktiv "Parklicht hinten links 
";
CM_ SG_ 982 LH_Parklicht_HR_aktiv "Parklicht hinten rechts 
";
CM_ SG_ 982 LH_Bremslicht_H_aktiv "Bremslicht hinten
";
CM_ SG_ 982 LH_Nebelschluss_aktiv "Nebelschlusslicht
";
CM_ SG_ 982 LH_Rueckfahrlicht_aktiv "Rueckfahrlicht
";
CM_ SG_ 982 LH_Blinker_HL_akt "Blinker hinten links
";
CM_ SG_ 982 LH_Blinker_HR_akt "Blinker hinten rechts
";
CM_ SG_ 982 LH_Blinker_li_def "Fehlerstatus Blinker hinten links
";
CM_ SG_ 982 LH_Bremsl_li_def "Fehlerstatus Bremslicht hinten links (Detektion Einzelausfall)
";
CM_ SG_ 982 LH_Schlusslicht_li_def "Fehlererkennung Schlusslicht hinten links
";
CM_ SG_ 982 LH_Rueckf_li_def "Fehlererkennung Rückfahrlicht hinten links
";
CM_ SG_ 982 LH_Nebel_li_def "Fehlererkennung Nebelschlusslicht hinten links
";
CM_ SG_ 982 LH_Schluss_Brems_Nebel_li_def "Signal wird gesetzt, wenn eine Unterbrechung oder  ein Kurzschluss am Lampenausgang für Schluss_Brems_Nebelschlusslicht erkannt wird.";
CM_ SG_ 982 LH_Schluss_Brems_Nebel_re_def "Signal wird gesetzt, wenn eine Unterbrechung oder  ein Kurzschluss am Lampenausgang für Schluss_Brems_Nebelschlusslicht erkannt wird.";
CM_ SG_ 982 LH_Schluss_Brems_li_def "Konfiguration SL+ BRL + PL links und SL+ BRL  links
";
CM_ SG_ 982 LH_Schluss_Nebel_li_def "Konfiguration SL + NSL links oder SL + NSL + PL links
";
CM_ SG_ 982 LH_SL_BRL_BLK_li_def "Konfiguration SL + BRL + BLK links oder SL + BRL + BLK + PL links
";
CM_ SG_ 982 LH_Brems_Blk_li_def "Konfiguration BRL + BLK links 
";
CM_ SG_ 982 LH_Blinker_re_def "Fehlerstatus Blinker hinten rechts
";
CM_ SG_ 982 LH_Bremsl_re_def "Fehlerstatus Bremslicht hinten rechts  (Detektion Einzelausfall)
";
CM_ SG_ 982 LH_Schlusslicht_re_def "Fehlererkennung Schlusslicht hinten rechts
";
CM_ SG_ 982 LH_Rueckf_re_def "Fehlererkennung Rückfahrlicht hinten rechts
";
CM_ SG_ 982 LH_Nebel_re_def "Fehlererkennung Nebelschlusslicht hinten rechts
";
CM_ SG_ 982 LH_Schluss_Brems_re_def "Konfiguration SL+ BRL + PL rechts und SL+ BRL  rechts
";
CM_ SG_ 982 LH_Schluss_Nebel_re_def "Konfiguration SL + NSL rechts oder SL + NSL + PL rechts
";
CM_ SG_ 982 LH_SL_BRL_BLK_re_def "Konfiguration SL + BRL + BLK rechts oder SL + BRL + BLK + PL rechts
";
CM_ SG_ 982 LH_Brems_Blk_re_def "Konfiguration BRL + BLK rechts
";
CM_ SG_ 982 LH_Kennzl_def "Fehlerstatus Kennzeichenbeleuchtung hinten
";
CM_ SG_ 982 LH_3_Bremsl_def "Fehlerstatus 3. Bremsleuchte
";
CM_ SG_ 982 LH_Nebel_mi_def "Fehlererkennung Nebelschlusslicht hinten Mitte


";
CM_ SG_ 982 LH_Rueckf_mi_def "Fehlererkennung Rückfahrlicht Mitte
";
CM_ SG_ 982 LH_Bremsl_li_ges_def "Fehlerstatus Bremslicht hinten links (Detektion Totalausfall)
";
CM_ SG_ 982 LH_Bremsl_re_ges_def "Fehlerstatus Bremslicht hinten rechts (Detektion Totalausfall)";
CM_ SG_ 1624 Licht_Vorne_01_CRC "Für MLB:
'Berechnung siehe Lastenheft 'Kommunikationsabsicherung für FlexRay und CAN''

Ab MQB und MLBevo:
'Berechnung siehe Lastenheft 'End-to-End Kommunikationsabsicherung''

Endwerte siehe Begleitdokument 'S-PDU Kennungsfolgen'";
CM_ SG_ 1624 LV_Standlicht_Anzeige "Anzeige Standlicht
";
CM_ SG_ 1624 LV_Abblendlicht_Anzeige "Abblendlicht aktiv";
CM_ SG_ 1624 LV_Fernlicht_Anzeige "Fernlicht_aktiv";
CM_ SG_ 1624 LV_Nebellicht_Anzeige "Nebellicht_aktiv
";
CM_ SG_ 1624 LV_Nebelschlusslicht_Anzeige "Nebelschlusslicht_aktiv
";
CM_ SG_ 1624 LV_Tagfahrlicht_Anzeige "Anzeige Tagfahrlicht
";
CM_ SG_ 1624 LV_AFL_aktiv_Anzeige "Anzeige AFL-Funktion";
CM_ SG_ 1624 LV_AFL_defekt "Fehlerstatus AFL
";
CM_ SG_ 1624 LV_Blinker_li_def "Fehlerstatus Blinker vorne links
";
CM_ SG_ 1624 LV_Standlicht_li_def "Fehlerstatus Standlicht vorne links
";
CM_ SG_ 1624 LV_Abblendlicht_li_def "Fehlerstatus Abblendlicht vorne links 
";
CM_ SG_ 1624 LV_Fernlicht_li_def "Fehlerstatus Fernlicht vorne links
";
CM_ SG_ 1624 LV_Nebellicht_li_def "Fehlerstatus Nebelscheinwerfer vorne links
";
CM_ SG_ 1624 LV_Blk_li_Seite_def "Fehlerstatus Seitenblinker links
";
CM_ SG_ 1624 LV_Tagfahrlicht_li_def "Fehlerstatus Tagfahrlicht links
";
CM_ SG_ 1624 LV_FLA_aktiv_Anzeige "Ansteuerung FLA-Lampe im Kombi (BCM1 Bedienmaster)";
CM_ SG_ 1624 LV_FLA_defekt "Fehlerstatus FLA (Anzeige des entsprechenden Fehlertext im Kombi)";
CM_ SG_ 1624 LV_FLA_Sensor_blockiert "Status FLA-Sensor (Anzeige des entsprechenden Fehlertext im Kombi)";
CM_ SG_ 1624 LV_Blinker_re_def "Fehlerstatus Blinker vorne rechts
";
CM_ SG_ 1624 LV_Standlicht_re_def "Fehlerstatus Standlicht vorne rechts
";
CM_ SG_ 1624 LV_Abblendlicht_re_def "Fehlerstatus Abblendlicht vorne rechts
";
CM_ SG_ 1624 LV_Fernlicht_re_def "Fehlerstatus Fernlicht vorne rechts
";
CM_ SG_ 1624 LV_Nebellicht_re_def "Fehlerstatus Nebelscheinwerfer vorne rechts
";
CM_ SG_ 1624 LV_Blk_re_Seite_def "Fehlerstatus Blinker Seite rechts
";
CM_ SG_ 1624 LV_Tagfahrlicht_re_def "Fehlerstatus Tagfahrlicht rechts";
CM_ SG_ 1624 LV_Aussenlicht_def "Aussenlicht kann nicht mehr korrekt angesteuert werden (EEPROM Codierung kann nicht mehr ausgelesen werden)
";
CM_ SG_ 1624 LV_Abblendlicht_TFL_li_def "Fehlerstatus Abblendlicht und Tagfahrlicht links
";
CM_ SG_ 1624 LV_Nebellicht_TFL_li_def "Fehlerstatus Nebellicht und Tagfahrlicht links ";
CM_ SG_ 1624 LV_Standlicht_TFL_li_def "Fehlerstatus Standlicht und Tagfahrlicht links ";
CM_ SG_ 1624 LV_Abblend_Fernlicht_li_def "Fehlerstatus Abblendlicht und Fernlicht links ";
CM_ SG_ 1624 LV_Abblendlicht_TFL_re_def "Fehlerstatus Abblendlicht und Tagfahrlicht rechts ";
CM_ SG_ 1624 LV_Nebellicht_TFL_re_def "Fehlerstatus Nebellicht und Tagfahrlicht rechts";
CM_ SG_ 1624 LV_Standlicht_TFL_re_def "Fehlerstatus Standlicht und Tagfahrlicht rechts ";
CM_ SG_ 1624 LV_Abblend_Fernlicht_re_def "Fehlerstatus Abblendlicht und Fernlicht rechts";
CM_ SG_ 1624 LV_Abbiegelicht_li_def "Fehlerstatus Abbiegelicht vorne links
";
CM_ SG_ 1624 LV_Abbiegelicht_re_def "Fehlerstatus Abbiegelicht vorne rechts
";
CM_ SG_ 1624 BCM1_Linksverkehr "Information über Aufbauzustand des Fzg:
0 = Scheinwerfer für Rechtsverkehr
1 = Scheinwerfer für Linksverkehr";
CM_ SG_ 1624 BCM1_Licht_Dunkelheit_aktiv "Licht aktiv aufgrund von Dunkelheit (nicht bei Autobahn-, Tagfahr- oder Regenlicht)
";
CM_ SG_ 1624 LV_LED_Scheinwerfer_li_def "Fehlerstatus LED-Scheinwerfer links
";
CM_ SG_ 1624 LV_LED_Scheinwerfer_re_def "Fehlerstatus LED-Scheinwerfer rechts";
CM_ SG_ 1624 LV_Blinker_VL_aktiv "Blinker vorne links
";
CM_ SG_ 1624 LV_Blinker_VR_aktiv "Blinker vorne links
";
CM_ BO_ 917 "MLB";
CM_ SG_ 917 AFS_Abbiegelicht_li_Anf "Anforderung das Abbiegelicht links einzuschalten";
CM_ SG_ 917 AFS_Abbiegelicht_re_Anf "Anforderung das Abbiegelicht rechts einzuschalten";
CM_ SG_ 917 AFS_Abbiegelicht_Dimm_Anf "Beschreibt ob das Abbiegelicht gedimmt oder hart einschalten werden soll. Dimmkurve ist Empfänger hinterlegt.";
CM_ SG_ 917 AFS_Verfuegbarkeit_GLW "Beschreibt die Verfügbarkeit der Gleitenden Leuchtweite / Fernlichtassistenz - Verfügbarkeit bedeutet, dass die Funktion Gleitende Leuchtweite möglich ist";
CM_ SG_ 917 AFS_Status_adaptive_LV "Gibt den Status der adaptiven Lichtverteilung an";
CM_ SG_ 917 AFS_Fernlicht_li_defekt "Beschreibt ob das Fernlicht des linken Scheinwerfers defekt ist";
CM_ SG_ 917 AFS_Fernlicht_re_defekt "Beschreibt ob das Fernlicht des rechten Scheinwerfers defekt ist";
CM_ SG_ 917 AFS_Fernlicht_Status "Beschreibt ob das Fernlicht aktiv oder inaktiv ist";
CM_ SG_ 917 AFS_Lampe "Status der Fehlerlampe: aktuell anliegender Fehlerzustand des dynamischen oder statischen Kurvenlichtes";
CM_ SG_ 917 LWR_Lampe "Status der Fehlerlampe: aktuell anliegender Fehlerzustand";
CM_ SG_ 917 AFS_Fehlertext "Fehlertext wird im Kombi angezeigt (z.Zt nur bei VW)";
CM_ SG_ 917 AFS_LED_Blinkmode "Lampe soll im Warnfall mit 1Hz blinken, wenn das Bit gesetzt ist (z.Zt nur bei VW)";
CM_ SG_ 917 LWR_Touristenmodus_aktiv "Über MMI sendet BCM1 eine Anforderung Touristenmodus an die LWR. Diese sendet als Rückmeldung an BCM1, dass der Touristenmodus aktiv geschaltet wurde";
CM_ SG_ 917 AFS_Charisma_FahrPr "MLBevo: Aktuelles Fahrprogramm des Charisma-Teilnehmers (siehe Systemlastenheft Drive Select)
MQB: Istwert der Kennlinie (siehe Systemlastenheft MQB FPA)";
CM_ SG_ 917 AFS_Charisma_Status "Charisma Systemstatus des Charisma-Teilnehmers

Wert 0x3 ist nur für Fahrzeuge ab MQB relevant";
CM_ SG_ 917 LWR_Sicherheitsposition_re "Rechter Scheinwerfer in Sicherheitsposition.";
CM_ SG_ 917 AFS_Allwetterlicht "Status ¿Allwetterlicht¿ - Licht für schlechte Sichtverhältnisse
(bei Defekt -> nicht aktiv)";
CM_ SG_ 917 LWR_Touristenmodus_verbaut "Verfügbarkeit der Touristenfunktion im AFS/LWR-SG.
(Das BCM steuert mit diesem Signal die Einblendung des entsprechenden Menüs)";
CM_ SG_ 917 AFS_adaptive_LV_verbaut "Verfügbarkeit der adaptiven Lichtverteilung im AFS-SG.
(Das BCM steuert mit diesem Signal die Einblendung des entsprechenden Menüs)";
CM_ SG_ 917 LWR_Reisemodus_Texte "Anzeige der eingestellten Verkehrsart bei aktivem Touristenlicht";
CM_ SG_ 917 GLW_Sensor_blockiert "Das Signal zeigt an, dass die Kamera zur Zeit keine Sicht hat. 
Verhalten wie Fernlichassisten. 
Weiterleitung des Signals vom BCM an das KOMBI";
CM_ SG_ 917 AFS_Charisma_Umschaltung "Erkennung  Umschaltaufforderung des Charisma-Teilnehmers";
CM_ SG_ 917 LWR_Pos_Schrittmotor "Position des Aktuators in Prozent des maximalen Stellweges; vor dem Initialisierungslauf (Motorstart) wird der Initwert ausgegeben: 
0% : tiefste Stellung (auf Block) des Schrittmotors;
100% : maximaler Verstellweg des Schrittmotors (nicht die Grenze de";
CM_ SG_ 917 LWR_Hoehenwert_VL "Aktueller Höhensensorwert Vorne Links

0x7F = 0 mm";
CM_ SG_ 917 LWR_Hoehenwert_HL "Aktueller Höhensensorwert Hinten Links
MSS LB überträgt den Aktueller Höhensensorwert Vorne Rechts.

0x7F = 0 mm";
CM_ SG_ 917 AFS_Ersatzlicht_Links "Bei aktivierter Ersatzlichtfunktion wird das Abblendlicht ausgeschaltet und eine Ersatzlichtquelle eingeschaltet (z.Zt. B7)";
CM_ SG_ 917 AFS_Ersatzlicht_Rechts "Bei aktivierter Ersatzlichtfunktion wird das Abblendlicht ausgeschaltet und eine Ersatzlichtquelle eingeschaltet (z.Zt. B7)";
CM_ SG_ 917 LWR_AFS_Grundeinstellung "Grundeinstellung des Abblendlichtes am Lichteinstellkasten im Service oder Bandende mit Tester erfolgt! (auch für das dynamische Kurvernlicht)";
CM_ SG_ 917 LWR_AFS_Parametrisierung "Parametrisierung wählt die Fahrzeugvariante und die AFS-Variante aus";
CM_ SG_ 917 LWR_Initialisierungslauf "Initialisierungslauf der Schrittmotoren, erfolgt defaultmäßig beim Motorstart";
CM_ SG_ 917 LWR_Sicherheitsposition_li "Rechter Scheinwerfer in Sicherheitsposition.";
CM_ SG_ 917 LWR_Modus "Schnelle oder langsame Regelart der LWR";
BA_DEF_ BO_  "DiagRequest" ENUM  "No","Yes";
BA_DEF_ BO_  "DiagResponse" ENUM  "No","Yes";
BA_DEF_ BO_  "DiagState" ENUM  "No","Yes";
BA_DEF_ BO_  "GenMsgChkConstant" HEX 0 4095;
BA_DEF_ BO_  "GenMsgCycleTime" INT 0 65535;
BA_DEF_ BO_  "GenMsgCycleTimeFast" INT 0 65535;
BA_DEF_ BO_  "GenMsgDelayTime" INT 0 100000;
BA_DEF_ BO_  "GenMsgILSupport" ENUM  "No","Yes";
BA_DEF_ BO_  "GenMsgNrOfRepetition" INT 0 100;
BA_DEF_ BO_  "GenMsgPDUConstants" STRING ;
BA_DEF_ BO_  "GenMsgSendType" ENUM  "Cyclic","not_used","not_used","not_used","not_used","not_used","not_used","IfActive","NoMsgSendType";
BA_DEF_ BO_  "GenMsgStartDelayTime" INT 0 100000;
BA_DEF_ BO_  "NmMessage" ENUM  "No","Yes";
BA_DEF_ BO_  "NmhMessage" ENUM  "No","Yes";
BA_DEF_ BO_  "MsgType" ENUM  "Application","NM ","NMH","TP2.0","ISO-TP ","BAP","EID";
BA_DEF_ BO_  "VAGTP20_API" HEX 0 255;
BA_DEF_ BO_  "VAGTP20_DynConnection" ENUM  "No","Yes";
BA_DEF_ BO_  "VAGTP20_DynSetup" ENUM  "No","Yes";
BA_DEF_ BO_  "VAGTP20_StatConnection" ENUM  "No","Yes";
BA_DEF_ SG_  "GenSigActiveRepetitions" INT -2147483648 2147483647;
BA_DEF_ SG_  "GenSigInactiveValue" INT -2147483648 2147483647;
BA_DEF_ SG_  "GenSigSendType" ENUM  "Cyclic","OnWrite","OnWriteWithRepetition","OnChange","OnChangeWithRepetition","IfActive","IfActiveWithRepetition","NoSigSendType","OnChangeAndIfActive","OnChangeAndIfActiveWithRepetition";
BA_DEF_ SG_  "GenSigStartValue" INT -2147483648 2147483647;
BA_DEF_ SG_  "NWM-WakeupAllowed" ENUM  "No","Yes";
BA_DEF_ SG_  "GenSigFuncType" ENUM  "NoFunction","MsgCounter","CRC-8","XOR","XOR-2","DatedBit","SW-Kl15","CHK","Constant","Protocol","CRC-8-SAE_J1850";
BA_DEF_ SG_  "GenSigSwitchedByIgnition" ENUM  "No","Yes";
BA_DEF_ SG_  "Fehlerwert" HEX 0 2147483647;
BA_DEF_ SG_  "GenSigMissingSourceValue" HEX 0 2147483647;
BA_DEF_REL_ BU_SG_REL_  "GenSigTimeoutTime" INT 0 65535;
BA_DEF_DEF_  "DiagRequest" "No";
BA_DEF_DEF_  "DiagResponse" "No";
BA_DEF_DEF_  "DiagState" "No";
BA_DEF_DEF_  "GenMsgChkConstant" 0;
BA_DEF_DEF_  "GenMsgCycleTime" 0;
BA_DEF_DEF_  "GenMsgCycleTimeFast" 0;
BA_DEF_DEF_  "GenMsgDelayTime" 0;
BA_DEF_DEF_  "GenMsgILSupport" "No";
BA_DEF_DEF_  "GenMsgNrOfRepetition" 0;
BA_DEF_DEF_  "GenMsgPDUConstants" "";
BA_DEF_DEF_  "GenMsgSendType" "NoMsgSendType";
BA_DEF_DEF_  "GenMsgStartDelayTime" 0;
BA_DEF_DEF_  "NmMessage" "No";
BA_DEF_DEF_  "NmhMessage" "No";
BA_DEF_DEF_  "MsgType" "Application";
BA_DEF_DEF_  "VAGTP20_API" 0;
BA_DEF_DEF_  "VAGTP20_DynConnection" "No";
BA_DEF_DEF_  "VAGTP20_DynSetup" "No";
BA_DEF_DEF_  "VAGTP20_StatConnection" "No";
BA_DEF_DEF_  "GenSigActiveRepetitions" 0;
BA_DEF_DEF_  "GenSigInactiveValue" 0;
BA_DEF_DEF_  "GenSigSendType" "NoSigSendType";
BA_DEF_DEF_  "GenSigStartValue" 0;
BA_DEF_DEF_  "NWM-WakeupAllowed" "No";
BA_DEF_DEF_  "GenSigFuncType" "NoFunction";
BA_DEF_DEF_  "GenSigSwitchedByIgnition" "Yes";
BA_DEF_DEF_  "Fehlerwert" 0;
BA_DEF_DEF_  "GenSigMissingSourceValue" 0;
BA_DEF_DEF_REL_ "GenSigTimeoutTime" 0;
BA_ "GenMsgSendType" BO_ 2549088300 0;
BA_ "GenMsgILSupport" BO_ 2549088300 1;
BA_ "GenMsgCycleTime" BO_ 2549088300 500;
BA_ "GenMsgSendType" BO_ 2549088388 0;
BA_ "GenMsgILSupport" BO_ 2549088388 1;
BA_ "GenMsgCycleTime" BO_ 2549088388 500;
BA_ "GenMsgSendType" BO_ 2549088416 0;
BA_ "GenMsgILSupport" BO_ 2549088416 1;
BA_ "GenMsgCycleTime" BO_ 2549088416 500;
BA_ "GenMsgSendType" BO_ 2549088411 0;
BA_ "GenMsgILSupport" BO_ 2549088411 1;
BA_ "GenMsgCycleTime" BO_ 2549088411 500;
BA_ "GenMsgSendType" BO_ 2549088392 0;
BA_ "GenMsgILSupport" BO_ 2549088392 1;
BA_ "GenMsgCycleTime" BO_ 2549088392 500;
BA_ "GenMsgSendType" BO_ 2549088391 0;
BA_ "GenMsgILSupport" BO_ 2549088391 1;
BA_ "GenMsgCycleTime" BO_ 2549088391 500;
BA_ "GenMsgSendType" BO_ 2549088405 0;
BA_ "GenMsgILSupport" BO_ 2549088405 1;
BA_ "GenMsgCycleTime" BO_ 2549088405 500;
BA_ "GenMsgSendType" BO_ 2549088333 0;
BA_ "GenMsgILSupport" BO_ 2549088333 1;
BA_ "GenMsgCycleTime" BO_ 2549088333 500;
BA_ "GenMsgSendType" BO_ 2549088332 0;
BA_ "GenMsgILSupport" BO_ 2549088332 1;
BA_ "GenMsgCycleTime" BO_ 2549088332 500;
BA_ "GenMsgSendType" BO_ 2549088292 0;
BA_ "GenMsgILSupport" BO_ 2549088292 1;
BA_ "GenMsgCycleTime" BO_ 2549088292 500;
BA_ "GenMsgSendType" BO_ 2549088299 0;
BA_ "GenMsgILSupport" BO_ 2549088299 1;
BA_ "GenMsgCycleTime" BO_ 2549088299 500;
BA_ "GenMsgSendType" BO_ 2549088331 0;
BA_ "GenMsgILSupport" BO_ 2549088331 1;
BA_ "GenMsgCycleTime" BO_ 2549088331 500;
BA_ "GenMsgSendType" BO_ 2549088330 0;
BA_ "GenMsgILSupport" BO_ 2549088330 1;
BA_ "GenMsgCycleTime" BO_ 2549088330 500;
BA_ "GenMsgSendType" BO_ 2549088301 0;
BA_ "GenMsgILSupport" BO_ 2549088301 1;
BA_ "GenMsgCycleTime" BO_ 2549088301 500;
BA_ "GenMsgSendType" BO_ 779 0;
BA_ "GenMsgILSupport" BO_ 779 1;
BA_ "GenMsgDelayTime" BO_ 779 50;
BA_ "GenMsgCycleTime" BO_ 779 200;
BA_ "GenMsgSendType" BO_ 1719 0;
BA_ "GenMsgILSupport" BO_ 1719 1;
BA_ "GenMsgDelayTime" BO_ 1719 100;
BA_ "GenMsgCycleTime" BO_ 1719 1000;
BA_ "GenMsgSendType" BO_ 1720 0;
BA_ "GenMsgILSupport" BO_ 1720 1;
BA_ "GenMsgCycleTime" BO_ 1720 1000;
BA_ "GenMsgSendType" BO_ 1724 0;
BA_ "GenMsgILSupport" BO_ 1724 1;
BA_ "GenMsgCycleTime" BO_ 1724 1000;
BA_ "GenMsgSendType" BO_ 2589283471 0;
BA_ "GenMsgILSupport" BO_ 2589283471 1;
BA_ "GenMsgDelayTime" BO_ 2589283471 100;
BA_ "GenMsgCycleTime" BO_ 2589283471 1000;
BA_ "MsgType" BO_ 2549874958 4;
BA_ "MsgType" BO_ 2550006030 4;
BA_ "MsgType" BO_ 2549875083 4;
BA_ "MsgType" BO_ 2550006155 4;
BA_ "GenMsgSendType" BO_ 919 0;
BA_ "GenMsgILSupport" BO_ 919 1;
BA_ "GenMsgDelayTime" BO_ 919 40;
BA_ "GenMsgCycleTime" BO_ 919 80;
BA_ "GenMsgSendType" BO_ 810 0;
BA_ "GenMsgPDUConstants" BO_ 810 "0x29,0x29,0x29,0x29,0x29,0x29,0x29,0x29,0x29,0x29,0x29,0x29,0x29,0x29,0x29,0x29";
BA_ "GenMsgILSupport" BO_ 810 1;
BA_ "GenMsgCycleTime" BO_ 810 40;
BA_ "GenMsgChkConstant" BO_ 810 41;
BA_ "GenMsgSendType" BO_ 160 0;
BA_ "GenMsgPDUConstants" BO_ 160 "0x4a,0xb4,0xe8,0x24,0x99,0x5a,0x59,0x8b,0x1e,0xaa,0x94,0xb6,0x09,0xd5,0xaf,0x97";
BA_ "GenMsgILSupport" BO_ 160 1;
BA_ "GenMsgCycleTime" BO_ 160 10;
BA_ "GenMsgSendType" BO_ 981 0;
BA_ "GenMsgPDUConstants" BO_ 981 "0xc5,0x39,0xc7,0xf9,0x92,0xd8,0x24,0xce,0xf1,0xb5,0x7a,0xc4,0xbc,0x60,0xe3,0xd1";
BA_ "GenMsgILSupport" BO_ 981 1;
BA_ "GenMsgCycleTime" BO_ 981 100;
BA_ "GenMsgSendType" BO_ 982 0;
BA_ "GenMsgILSupport" BO_ 982 1;
BA_ "GenMsgCycleTime" BO_ 982 100;
BA_ "GenMsgSendType" BO_ 1624 0;
BA_ "GenMsgPDUConstants" BO_ 1624 "0x46,0x0f,0xe0,0xcc,0xbe,0xb1,0xd7,0xf1,0x1f,0x31,0xc1,0x25,0xb4,0x3e,0xc8,0xa3";
BA_ "GenMsgILSupport" BO_ 1624 1;
BA_ "GenMsgDelayTime" BO_ 1624 50;
BA_ "GenMsgCycleTime" BO_ 1624 1000;
BA_ "GenMsgSendType" BO_ 917 0;
BA_ "GenMsgILSupport" BO_ 917 1;
BA_ "GenMsgDelayTime" BO_ 917 10;
BA_ "GenMsgCycleTime" BO_ 917 100;
BA_ "GenSigSwitchedByIgnition" SG_ 2549088300 MFG_KompSchutz 0;
BA_ "GenSigSendType" SG_ 2549088300 MFG_KompSchutz 0;
BA_ "GenSigSwitchedByIgnition" SG_ 2549088300 MFG_Abschaltstufe 0;
BA_ "GenSigSendType" SG_ 2549088300 MFG_Abschaltstufe 0;
BA_ "GenSigSwitchedByIgnition" SG_ 2549088300 MFG_Transport_Mode 0;
BA_ "GenSigSendType" SG_ 2549088300 MFG_Transport_Mode 0;
BA_ "GenSigSwitchedByIgnition" SG_ 2549088300 MFG_Nachlauftyp 0;
BA_ "GenSigStartValue" SG_ 2549088300 MFG_Nachlauftyp 2;
BA_ "GenSigSendType" SG_ 2549088300 MFG_Nachlauftyp 0;
BA_ "GenSigSwitchedByIgnition" SG_ 2549088300 MFG_SNI 0;
BA_ "GenSigStartValue" SG_ 2549088300 MFG_SNI 44;
BA_ "GenSigSendType" SG_ 2549088300 MFG_SNI 0;
BA_ "GenSigSwitchedByIgnition" SG_ 2549088300 KN_MFG_BusKnockOutTimer 0;
BA_ "GenSigSendType" SG_ 2549088300 KN_MFG_BusKnockOutTimer 0;
BA_ "GenSigSwitchedByIgnition" SG_ 2549088300 NM_MFG_Wakeup 0;
BA_ "NWM-WakeupAllowed" SG_ 2549088300 NM_MFG_Wakeup 1;
BA_ "GenSigSendType" SG_ 2549088300 NM_MFG_Wakeup 0;
BA_ "GenSigSwitchedByIgnition" SG_ 2549088300 NM_MFG_Lokalaktiv 0;
BA_ "GenSigSendType" SG_ 2549088300 NM_MFG_Lokalaktiv 0;
BA_ "GenSigSwitchedByIgnition" SG_ 2549088300 NM_MFG_Subsystemaktiv 0;
BA_ "GenSigSendType" SG_ 2549088300 NM_MFG_Subsystemaktiv 0;
BA_ "GenSigSwitchedByIgnition" SG_ 2549088300 MFG_KD_Fehler 0;
BA_ "GenSigSendType" SG_ 2549088300 MFG_KD_Fehler 0;
BA_ "GenSigSwitchedByIgnition" SG_ 2549088388 SAD_KompSchutz 0;
BA_ "GenSigSendType" SG_ 2549088388 SAD_KompSchutz 0;
BA_ "GenSigSwitchedByIgnition" SG_ 2549088388 SAD_Abschaltstufe 0;
BA_ "GenSigSendType" SG_ 2549088388 SAD_Abschaltstufe 0;
BA_ "GenSigSwitchedByIgnition" SG_ 2549088388 SAD_Transport_Mode 0;
BA_ "GenSigSendType" SG_ 2549088388 SAD_Transport_Mode 0;
BA_ "GenSigSwitchedByIgnition" SG_ 2549088388 SAD_Nachlauftyp 0;
BA_ "GenSigStartValue" SG_ 2549088388 SAD_Nachlauftyp 2;
BA_ "GenSigSendType" SG_ 2549088388 SAD_Nachlauftyp 0;
BA_ "GenSigSwitchedByIgnition" SG_ 2549088388 SAD_SNI 0;
BA_ "GenSigStartValue" SG_ 2549088388 SAD_SNI 132;
BA_ "GenSigSendType" SG_ 2549088388 SAD_SNI 0;
BA_ "GenSigSwitchedByIgnition" SG_ 2549088388 NM_SAD_Wakeup 0;
BA_ "NWM-WakeupAllowed" SG_ 2549088388 NM_SAD_Wakeup 1;
BA_ "GenSigSendType" SG_ 2549088388 NM_SAD_Wakeup 0;
BA_ "GenSigSwitchedByIgnition" SG_ 2549088388 NM_SAD_Lokalaktiv 0;
BA_ "GenSigSendType" SG_ 2549088388 NM_SAD_Lokalaktiv 0;
BA_ "GenSigSwitchedByIgnition" SG_ 2549088388 NM_SAD_Subsystemaktiv 0;
BA_ "GenSigSendType" SG_ 2549088388 NM_SAD_Subsystemaktiv 0;
BA_ "GenSigSwitchedByIgnition" SG_ 2549088388 SAD_KD_Fehler 0;
BA_ "GenSigSendType" SG_ 2549088388 SAD_KD_Fehler 0;
BA_ "GenSigSwitchedByIgnition" SG_ 2549088416 SAD2_KompSchutz 0;
BA_ "GenSigSendType" SG_ 2549088416 SAD2_KompSchutz 0;
BA_ "GenSigSwitchedByIgnition" SG_ 2549088416 SAD2_Abschaltstufe 0;
BA_ "GenSigSendType" SG_ 2549088416 SAD2_Abschaltstufe 0;
BA_ "GenSigSwitchedByIgnition" SG_ 2549088416 SAD2_Transport_Mode 0;
BA_ "GenSigSendType" SG_ 2549088416 SAD2_Transport_Mode 0;
BA_ "GenSigSwitchedByIgnition" SG_ 2549088416 SAD2_Nachlauftyp 0;
BA_ "GenSigStartValue" SG_ 2549088416 SAD2_Nachlauftyp 2;
BA_ "GenSigSendType" SG_ 2549088416 SAD2_Nachlauftyp 0;
BA_ "GenSigSwitchedByIgnition" SG_ 2549088416 SAD2_SNI 0;
BA_ "GenSigStartValue" SG_ 2549088416 SAD2_SNI 160;
BA_ "GenSigSendType" SG_ 2549088416 SAD2_SNI 0;
BA_ "GenSigSwitchedByIgnition" SG_ 2549088416 NM_SAD2_Wakeup 0;
BA_ "NWM-WakeupAllowed" SG_ 2549088416 NM_SAD2_Wakeup 1;
BA_ "GenSigSendType" SG_ 2549088416 NM_SAD2_Wakeup 0;
BA_ "GenSigSwitchedByIgnition" SG_ 2549088416 NM_SAD2_Lokalaktiv 0;
BA_ "GenSigSendType" SG_ 2549088416 NM_SAD2_Lokalaktiv 0;
BA_ "GenSigSwitchedByIgnition" SG_ 2549088416 NM_SAD2_Subsystemaktiv 0;
BA_ "GenSigSendType" SG_ 2549088416 NM_SAD2_Subsystemaktiv 0;
BA_ "GenSigSwitchedByIgnition" SG_ 2549088416 SAD2_KD_Fehler 0;
BA_ "GenSigSendType" SG_ 2549088416 SAD2_KD_Fehler 0;
BA_ "GenSigSwitchedByIgnition" SG_ 2549088411 MSBBR_KompSchutz 0;
BA_ "GenSigSendType" SG_ 2549088411 MSBBR_KompSchutz 0;
BA_ "GenSigSwitchedByIgnition" SG_ 2549088411 MSBBR_Abschaltstufe 0;
BA_ "GenSigSendType" SG_ 2549088411 MSBBR_Abschaltstufe 0;
BA_ "GenSigSwitchedByIgnition" SG_ 2549088411 MSBBR_Transport_Mode 0;
BA_ "GenSigSendType" SG_ 2549088411 MSBBR_Transport_Mode 0;
BA_ "GenSigSwitchedByIgnition" SG_ 2549088411 SBBR_Nachlauftyp 0;
BA_ "GenSigStartValue" SG_ 2549088411 SBBR_Nachlauftyp 2;
BA_ "GenSigSendType" SG_ 2549088411 SBBR_Nachlauftyp 0;
BA_ "GenSigSwitchedByIgnition" SG_ 2549088411 SBBR_SNI 0;
BA_ "GenSigStartValue" SG_ 2549088411 SBBR_SNI 155;
BA_ "GenSigSendType" SG_ 2549088411 SBBR_SNI 0;
BA_ "GenSigSwitchedByIgnition" SG_ 2549088411 NM_MSBBR_Wakeup 0;
BA_ "NWM-WakeupAllowed" SG_ 2549088411 NM_MSBBR_Wakeup 1;
BA_ "GenSigSendType" SG_ 2549088411 NM_MSBBR_Wakeup 0;
BA_ "GenSigSwitchedByIgnition" SG_ 2549088411 NM_MSBBR_Lokalaktiv 0;
BA_ "GenSigSendType" SG_ 2549088411 NM_MSBBR_Lokalaktiv 0;
BA_ "GenSigSwitchedByIgnition" SG_ 2549088411 NM_MSBBR_Subsystemaktiv 0;
BA_ "GenSigSendType" SG_ 2549088411 NM_MSBBR_Subsystemaktiv 0;
BA_ "GenSigSwitchedByIgnition" SG_ 2549088411 SBBR_KD_Fehler 0;
BA_ "GenSigSendType" SG_ 2549088411 SBBR_KD_Fehler 0;
BA_ "GenSigSwitchedByIgnition" SG_ 2549088392 Mem_BFSFo_KompSchutz 0;
BA_ "GenSigSendType" SG_ 2549088392 Mem_BFSFo_KompSchutz 0;
BA_ "GenSigSwitchedByIgnition" SG_ 2549088392 Mem_BFSFo_Abschaltstufe 0;
BA_ "GenSigSendType" SG_ 2549088392 Mem_BFSFo_Abschaltstufe 0;
BA_ "GenSigSwitchedByIgnition" SG_ 2549088392 Mem_BFSFo_Transport_Mode 0;
BA_ "GenSigSendType" SG_ 2549088392 Mem_BFSFo_Transport_Mode 0;
BA_ "GenSigSwitchedByIgnition" SG_ 2549088392 Mem_BFSFo_Nachlauftyp 0;
BA_ "GenSigStartValue" SG_ 2549088392 Mem_BFSFo_Nachlauftyp 2;
BA_ "GenSigSendType" SG_ 2549088392 Mem_BFSFo_Nachlauftyp 0;
BA_ "GenSigSwitchedByIgnition" SG_ 2549088392 Mem_BFSFo_SNI 0;
BA_ "GenSigStartValue" SG_ 2549088392 Mem_BFSFo_SNI 136;
BA_ "GenSigSendType" SG_ 2549088392 Mem_BFSFo_SNI 0;
BA_ "GenSigSwitchedByIgnition" SG_ 2549088392 NM_Mem_BFSFo_Wakeup 0;
BA_ "NWM-WakeupAllowed" SG_ 2549088392 NM_Mem_BFSFo_Wakeup 1;
BA_ "GenSigSendType" SG_ 2549088392 NM_Mem_BFSFo_Wakeup 0;
BA_ "GenSigSwitchedByIgnition" SG_ 2549088392 NM_Mem_BFSFo_Lokalaktiv 0;
BA_ "GenSigSendType" SG_ 2549088392 NM_Mem_BFSFo_Lokalaktiv 0;
BA_ "GenSigSwitchedByIgnition" SG_ 2549088392 NM_Mem_BFSFo_Subsystemaktiv 0;
BA_ "GenSigSendType" SG_ 2549088392 NM_Mem_BFSFo_Subsystemaktiv 0;
BA_ "GenSigSwitchedByIgnition" SG_ 2549088392 Mem_BFSFo_KD_Fehler 0;
BA_ "GenSigSendType" SG_ 2549088392 Mem_BFSFo_KD_Fehler 0;
BA_ "GenSigSwitchedByIgnition" SG_ 2549088391 Mem_FSFo_KompSchutz 0;
BA_ "GenSigSendType" SG_ 2549088391 Mem_FSFo_KompSchutz 0;
BA_ "GenSigSwitchedByIgnition" SG_ 2549088391 Mem_FSFo_Abschaltstufe 0;
BA_ "GenSigSendType" SG_ 2549088391 Mem_FSFo_Abschaltstufe 0;
BA_ "GenSigSwitchedByIgnition" SG_ 2549088391 Mem_FSFo_Transport_Mode 0;
BA_ "GenSigSendType" SG_ 2549088391 Mem_FSFo_Transport_Mode 0;
BA_ "GenSigSwitchedByIgnition" SG_ 2549088391 Mem_FSFo_Nachlauftyp 0;
BA_ "GenSigStartValue" SG_ 2549088391 Mem_FSFo_Nachlauftyp 2;
BA_ "GenSigSendType" SG_ 2549088391 Mem_FSFo_Nachlauftyp 0;
BA_ "GenSigSwitchedByIgnition" SG_ 2549088391 Mem_FSFo_SNI 0;
BA_ "GenSigStartValue" SG_ 2549088391 Mem_FSFo_SNI 135;
BA_ "GenSigSendType" SG_ 2549088391 Mem_FSFo_SNI 0;
BA_ "GenSigSwitchedByIgnition" SG_ 2549088391 NM_Mem_FSFo_Wakeup 0;
BA_ "NWM-WakeupAllowed" SG_ 2549088391 NM_Mem_FSFo_Wakeup 1;
BA_ "GenSigSendType" SG_ 2549088391 NM_Mem_FSFo_Wakeup 0;
BA_ "GenSigSwitchedByIgnition" SG_ 2549088391 NM_Mem_FSFo_Lokalaktiv 0;
BA_ "GenSigSendType" SG_ 2549088391 NM_Mem_FSFo_Lokalaktiv 0;
BA_ "GenSigSwitchedByIgnition" SG_ 2549088391 NM_Mem_FSFo_Subsystemaktiv 0;
BA_ "GenSigSendType" SG_ 2549088391 NM_Mem_FSFo_Subsystemaktiv 0;
BA_ "GenSigSwitchedByIgnition" SG_ 2549088391 Mem_FSFo_KD_Fehler 0;
BA_ "GenSigSendType" SG_ 2549088391 Mem_FSFo_KD_Fehler 0;
BA_ "GenSigSwitchedByIgnition" SG_ 2549088405 SitzMem_SR3_KompSchutz 0;
BA_ "GenSigSendType" SG_ 2549088405 SitzMem_SR3_KompSchutz 0;
BA_ "GenSigSwitchedByIgnition" SG_ 2549088405 SitzMem_SR3_Abschaltstufe 0;
BA_ "GenSigSendType" SG_ 2549088405 SitzMem_SR3_Abschaltstufe 0;
BA_ "GenSigSwitchedByIgnition" SG_ 2549088405 SitzMem_SR3_Transport_Mode 0;
BA_ "GenSigSendType" SG_ 2549088405 SitzMem_SR3_Transport_Mode 0;
BA_ "GenSigSwitchedByIgnition" SG_ 2549088405 SitzMem_SR3_Nachlauftyp 0;
BA_ "GenSigStartValue" SG_ 2549088405 SitzMem_SR3_Nachlauftyp 2;
BA_ "GenSigSendType" SG_ 2549088405 SitzMem_SR3_Nachlauftyp 0;
BA_ "GenSigSwitchedByIgnition" SG_ 2549088405 SitzMem_SR3_SNI 0;
BA_ "GenSigStartValue" SG_ 2549088405 SitzMem_SR3_SNI 149;
BA_ "GenSigSendType" SG_ 2549088405 SitzMem_SR3_SNI 0;
BA_ "GenSigSwitchedByIgnition" SG_ 2549088405 NM_SitzMem_SR3_Wakeup 0;
BA_ "NWM-WakeupAllowed" SG_ 2549088405 NM_SitzMem_SR3_Wakeup 1;
BA_ "GenSigSendType" SG_ 2549088405 NM_SitzMem_SR3_Wakeup 0;
BA_ "GenSigSwitchedByIgnition" SG_ 2549088405 NM_SitzMem_SR3_Lokalaktiv 0;
BA_ "GenSigSendType" SG_ 2549088405 NM_SitzMem_SR3_Lokalaktiv 0;
BA_ "GenSigSwitchedByIgnition" SG_ 2549088405 NM_SitzMem_SR3_Subsystemaktiv 0;
BA_ "GenSigSendType" SG_ 2549088405 NM_SitzMem_SR3_Subsystemaktiv 0;
BA_ "GenSigSwitchedByIgnition" SG_ 2549088405 SitzMem_SR3_KD_Fehler 0;
BA_ "GenSigSendType" SG_ 2549088405 SitzMem_SR3_KD_Fehler 0;
BA_ "GenSigSwitchedByIgnition" SG_ 2549088333 Sitzmemo_BFS_KompSchutz 0;
BA_ "GenSigSendType" SG_ 2549088333 Sitzmemo_BFS_KompSchutz 0;
BA_ "GenSigSwitchedByIgnition" SG_ 2549088333 Sitzmemo_BFS_Abschaltstufe 0;
BA_ "GenSigSendType" SG_ 2549088333 Sitzmemo_BFS_Abschaltstufe 0;
BA_ "GenSigSwitchedByIgnition" SG_ 2549088333 Sitzmemo_BFS_Transport_Mode 0;
BA_ "GenSigSendType" SG_ 2549088333 Sitzmemo_BFS_Transport_Mode 0;
BA_ "GenSigSwitchedByIgnition" SG_ 2549088333 Sitzmemo_BFS_Nachlauftyp 0;
BA_ "GenSigStartValue" SG_ 2549088333 Sitzmemo_BFS_Nachlauftyp 2;
BA_ "GenSigSendType" SG_ 2549088333 Sitzmemo_BFS_Nachlauftyp 0;
BA_ "GenSigSwitchedByIgnition" SG_ 2549088333 Sitzmemo_BFS_SNI 0;
BA_ "GenSigStartValue" SG_ 2549088333 Sitzmemo_BFS_SNI 77;
BA_ "GenSigSendType" SG_ 2549088333 Sitzmemo_BFS_SNI 0;
BA_ "GenSigSwitchedByIgnition" SG_ 2549088333 NM_Sitzmemo_BFS_Wakeup 0;
BA_ "NWM-WakeupAllowed" SG_ 2549088333 NM_Sitzmemo_BFS_Wakeup 1;
BA_ "GenSigSendType" SG_ 2549088333 NM_Sitzmemo_BFS_Wakeup 0;
BA_ "GenSigSwitchedByIgnition" SG_ 2549088333 NM_Sitzmemo_BFS_Subsystemaktiv 0;
BA_ "GenSigSendType" SG_ 2549088333 NM_Sitzmemo_BFS_Subsystemaktiv 0;
BA_ "GenSigSwitchedByIgnition" SG_ 2549088333 NM_Sitzmemo_BFS_Lokalaktiv 0;
BA_ "GenSigSendType" SG_ 2549088333 NM_Sitzmemo_BFS_Lokalaktiv 0;
BA_ "GenSigSwitchedByIgnition" SG_ 2549088333 Mem_BFS_KD_Fehler 0;
BA_ "GenSigSendType" SG_ 2549088333 Mem_BFS_KD_Fehler 0;
BA_ "GenSigSwitchedByIgnition" SG_ 2549088332 Sitzmemo_FS_KompSchutz 0;
BA_ "GenSigSendType" SG_ 2549088332 Sitzmemo_FS_KompSchutz 0;
BA_ "GenSigSwitchedByIgnition" SG_ 2549088332 Sitzmemo_FS_Abschaltstufe 0;
BA_ "GenSigSendType" SG_ 2549088332 Sitzmemo_FS_Abschaltstufe 0;
BA_ "GenSigSwitchedByIgnition" SG_ 2549088332 Sitzmemo_FS_Transport_Mode 0;
BA_ "GenSigSendType" SG_ 2549088332 Sitzmemo_FS_Transport_Mode 0;
BA_ "GenSigSwitchedByIgnition" SG_ 2549088332 Sitzmemo_FS_Nachlauftyp 0;
BA_ "GenSigStartValue" SG_ 2549088332 Sitzmemo_FS_Nachlauftyp 2;
BA_ "GenSigSendType" SG_ 2549088332 Sitzmemo_FS_Nachlauftyp 0;
BA_ "GenSigSwitchedByIgnition" SG_ 2549088332 Sitzmemo_FS_SNI 0;
BA_ "GenSigStartValue" SG_ 2549088332 Sitzmemo_FS_SNI 76;
BA_ "GenSigSendType" SG_ 2549088332 Sitzmemo_FS_SNI 0;
BA_ "GenSigSwitchedByIgnition" SG_ 2549088332 NM_Sitzmemo_FS_Wakeup 0;
BA_ "NWM-WakeupAllowed" SG_ 2549088332 NM_Sitzmemo_FS_Wakeup 1;
BA_ "GenSigSendType" SG_ 2549088332 NM_Sitzmemo_FS_Wakeup 0;
BA_ "GenSigSwitchedByIgnition" SG_ 2549088332 NM_Sitzmemo_FS_Lokalaktiv 0;
BA_ "GenSigSendType" SG_ 2549088332 NM_Sitzmemo_FS_Lokalaktiv 0;
BA_ "GenSigSwitchedByIgnition" SG_ 2549088332 NM_Sitzmemo_FS_Subsystemaktiv 0;
BA_ "GenSigSendType" SG_ 2549088332 NM_Sitzmemo_FS_Subsystemaktiv 0;
BA_ "GenSigSwitchedByIgnition" SG_ 2549088332 Mem_FS_KD_Fehler 0;
BA_ "GenSigSendType" SG_ 2549088332 Mem_FS_KD_Fehler 0;
BA_ "GenSigSwitchedByIgnition" SG_ 2549088292 SpoilerSG_KompSchutz 0;
BA_ "GenSigSendType" SG_ 2549088292 SpoilerSG_KompSchutz 0;
BA_ "GenSigSwitchedByIgnition" SG_ 2549088292 SpoilerSG_Abschaltstufe 0;
BA_ "GenSigSendType" SG_ 2549088292 SpoilerSG_Abschaltstufe 0;
BA_ "GenSigSwitchedByIgnition" SG_ 2549088292 SpoilerSG_Transport_Mode 0;
BA_ "GenSigSendType" SG_ 2549088292 SpoilerSG_Transport_Mode 0;
BA_ "GenSigSwitchedByIgnition" SG_ 2549088292 SpoilerSG_Nachlauftyp 0;
BA_ "GenSigStartValue" SG_ 2549088292 SpoilerSG_Nachlauftyp 2;
BA_ "GenSigSendType" SG_ 2549088292 SpoilerSG_Nachlauftyp 0;
BA_ "GenSigSwitchedByIgnition" SG_ 2549088292 SpoilerSG_SNI 0;
BA_ "GenSigStartValue" SG_ 2549088292 SpoilerSG_SNI 36;
BA_ "GenSigSendType" SG_ 2549088292 SpoilerSG_SNI 0;
BA_ "GenSigSwitchedByIgnition" SG_ 2549088292 NM_SpoilerSG_Wakeup 0;
BA_ "NWM-WakeupAllowed" SG_ 2549088292 NM_SpoilerSG_Wakeup 1;
BA_ "GenSigSendType" SG_ 2549088292 NM_SpoilerSG_Wakeup 0;
BA_ "GenSigSwitchedByIgnition" SG_ 2549088292 KN_SpoilerSG_ECUKnockOut 0;
BA_ "GenSigSendType" SG_ 2549088292 KN_SpoilerSG_ECUKnockOut 0;
BA_ "GenSigSwitchedByIgnition" SG_ 2549088292 KN_SpoilerSG_WakePrevention 0;
BA_ "GenSigSendType" SG_ 2549088292 KN_SpoilerSG_WakePrevention 0;
BA_ "GenSigSwitchedByIgnition" SG_ 2549088292 NM_SpoilerSG_Lokalaktiv 0;
BA_ "GenSigSendType" SG_ 2549088292 NM_SpoilerSG_Lokalaktiv 0;
BA_ "GenSigSwitchedByIgnition" SG_ 2549088292 NM_SpoilerSG_Subsystemaktiv 0;
BA_ "GenSigSendType" SG_ 2549088292 NM_SpoilerSG_Subsystemaktiv 0;
BA_ "GenSigSwitchedByIgnition" SG_ 2549088292 SpoilerSG_KD_Fehler 0;
BA_ "GenSigSendType" SG_ 2549088292 SpoilerSG_KD_Fehler 0;
BA_ "GenSigSwitchedByIgnition" SG_ 2549088299 STS_KompSchutz 0;
BA_ "GenSigSendType" SG_ 2549088299 STS_KompSchutz 0;
BA_ "GenSigSwitchedByIgnition" SG_ 2549088299 STS_Abschaltstufe 0;
BA_ "GenSigSendType" SG_ 2549088299 STS_Abschaltstufe 0;
BA_ "GenSigSwitchedByIgnition" SG_ 2549088299 STS_Transport_Mode 0;
BA_ "GenSigSendType" SG_ 2549088299 STS_Transport_Mode 0;
BA_ "GenSigSwitchedByIgnition" SG_ 2549088299 STS_Nachlauftyp 0;
BA_ "GenSigStartValue" SG_ 2549088299 STS_Nachlauftyp 2;
BA_ "GenSigSendType" SG_ 2549088299 STS_Nachlauftyp 0;
BA_ "GenSigSwitchedByIgnition" SG_ 2549088299 STS_SNI 0;
BA_ "GenSigStartValue" SG_ 2549088299 STS_SNI 43;
BA_ "GenSigSendType" SG_ 2549088299 STS_SNI 0;
BA_ "GenSigSwitchedByIgnition" SG_ 2549088299 KN_VTS_BusKnockOutTimer 0;
BA_ "GenSigSendType" SG_ 2549088299 KN_VTS_BusKnockOutTimer 0;
BA_ "GenSigSwitchedByIgnition" SG_ 2549088299 NM_STS_Wakeup 0;
BA_ "NWM-WakeupAllowed" SG_ 2549088299 NM_STS_Wakeup 1;
BA_ "GenSigSendType" SG_ 2549088299 NM_STS_Wakeup 0;
BA_ "GenSigSwitchedByIgnition" SG_ 2549088299 KN_VTS_ECUKnockOut 0;
BA_ "GenSigSendType" SG_ 2549088299 KN_VTS_ECUKnockOut 0;
BA_ "GenSigSwitchedByIgnition" SG_ 2549088299 KN_VTS_WakePrevention 0;
BA_ "GenSigSendType" SG_ 2549088299 KN_VTS_WakePrevention 0;
BA_ "GenSigSwitchedByIgnition" SG_ 2549088299 NM_STS_Lokalaktiv 0;
BA_ "GenSigSendType" SG_ 2549088299 NM_STS_Lokalaktiv 0;
BA_ "GenSigSwitchedByIgnition" SG_ 2549088299 NM_STS_Subsystemaktiv 0;
BA_ "GenSigSendType" SG_ 2549088299 NM_STS_Subsystemaktiv 0;
BA_ "GenSigSwitchedByIgnition" SG_ 2549088299 STS_KD_Fehler 0;
BA_ "GenSigSendType" SG_ 2549088299 STS_KD_Fehler 0;
BA_ "GenSigSwitchedByIgnition" SG_ 2549088331 TSG_BFS_KompSchutz 0;
BA_ "GenSigSendType" SG_ 2549088331 TSG_BFS_KompSchutz 0;
BA_ "GenSigSwitchedByIgnition" SG_ 2549088331 TSG_BFS_Abschaltstufe 0;
BA_ "GenSigSendType" SG_ 2549088331 TSG_BFS_Abschaltstufe 0;
BA_ "GenSigSwitchedByIgnition" SG_ 2549088331 TSG_BFS_Transport_Mode 0;
BA_ "GenSigSendType" SG_ 2549088331 TSG_BFS_Transport_Mode 0;
BA_ "GenSigSwitchedByIgnition" SG_ 2549088331 TSG_BFS_Nachlauftyp 0;
BA_ "GenSigStartValue" SG_ 2549088331 TSG_BFS_Nachlauftyp 2;
BA_ "GenSigSendType" SG_ 2549088331 TSG_BFS_Nachlauftyp 0;
BA_ "GenSigSwitchedByIgnition" SG_ 2549088331 TSG_BFS_SNI 0;
BA_ "GenSigStartValue" SG_ 2549088331 TSG_BFS_SNI 75;
BA_ "GenSigSendType" SG_ 2549088331 TSG_BFS_SNI 0;
BA_ "GenSigSwitchedByIgnition" SG_ 2549088331 KN_TSG_BFS_BusKnockOutTimer 0;
BA_ "GenSigSendType" SG_ 2549088331 KN_TSG_BFS_BusKnockOutTimer 0;
BA_ "GenSigSwitchedByIgnition" SG_ 2549088331 NM_TSG_BFS_Wakeup 0;
BA_ "NWM-WakeupAllowed" SG_ 2549088331 NM_TSG_BFS_Wakeup 1;
BA_ "GenSigSendType" SG_ 2549088331 NM_TSG_BFS_Wakeup 0;
BA_ "GenSigSwitchedByIgnition" SG_ 2549088331 KN_TSG_BFS_ECUKnockOut 0;
BA_ "GenSigSendType" SG_ 2549088331 KN_TSG_BFS_ECUKnockOut 0;
BA_ "GenSigSwitchedByIgnition" SG_ 2549088331 KN_TSG_BFS_WakePrevention 0;
BA_ "GenSigSendType" SG_ 2549088331 KN_TSG_BFS_WakePrevention 0;
BA_ "GenSigSwitchedByIgnition" SG_ 2549088331 NM_TSG_BFS_Lokalaktiv 0;
BA_ "GenSigSendType" SG_ 2549088331 NM_TSG_BFS_Lokalaktiv 0;
BA_ "GenSigSwitchedByIgnition" SG_ 2549088331 NM_TSG_BFS_Subsystemaktiv 0;
BA_ "GenSigSendType" SG_ 2549088331 NM_TSG_BFS_Subsystemaktiv 0;
BA_ "GenSigSwitchedByIgnition" SG_ 2549088331 TSG_BFS_KD_Fehler 0;
BA_ "GenSigSendType" SG_ 2549088331 TSG_BFS_KD_Fehler 0;
BA_ "GenSigSwitchedByIgnition" SG_ 2549088330 TSG_FS_KompSchutz 0;
BA_ "GenSigSendType" SG_ 2549088330 TSG_FS_KompSchutz 0;
BA_ "GenSigSwitchedByIgnition" SG_ 2549088330 TSG_FS_Abschaltstufe 0;
BA_ "GenSigSendType" SG_ 2549088330 TSG_FS_Abschaltstufe 0;
BA_ "GenSigSwitchedByIgnition" SG_ 2549088330 TSG_FS_Transport_Mode 0;
BA_ "GenSigSendType" SG_ 2549088330 TSG_FS_Transport_Mode 0;
BA_ "GenSigSwitchedByIgnition" SG_ 2549088330 TSG_FS_Nachlauftyp 0;
BA_ "GenSigStartValue" SG_ 2549088330 TSG_FS_Nachlauftyp 2;
BA_ "GenSigSendType" SG_ 2549088330 TSG_FS_Nachlauftyp 0;
BA_ "GenSigSwitchedByIgnition" SG_ 2549088330 TSG_FS_SNI 0;
BA_ "GenSigStartValue" SG_ 2549088330 TSG_FS_SNI 74;
BA_ "GenSigSendType" SG_ 2549088330 TSG_FS_SNI 0;
BA_ "GenSigSwitchedByIgnition" SG_ 2549088330 KN_TSG_FS_BusKnockOutTimer 0;
BA_ "GenSigSendType" SG_ 2549088330 KN_TSG_FS_BusKnockOutTimer 0;
BA_ "GenSigSwitchedByIgnition" SG_ 2549088330 NM_TSG_FS_Wakeup 0;
BA_ "NWM-WakeupAllowed" SG_ 2549088330 NM_TSG_FS_Wakeup 1;
BA_ "GenSigSendType" SG_ 2549088330 NM_TSG_FS_Wakeup 0;
BA_ "GenSigSwitchedByIgnition" SG_ 2549088330 KN_TSG_FS_ECUKnockOut 0;
BA_ "GenSigSendType" SG_ 2549088330 KN_TSG_FS_ECUKnockOut 0;
BA_ "GenSigSwitchedByIgnition" SG_ 2549088330 KN_TSG_FS_WakePrevention 0;
BA_ "GenSigSendType" SG_ 2549088330 KN_TSG_FS_WakePrevention 0;
BA_ "GenSigSwitchedByIgnition" SG_ 2549088330 NM_TSG_FS_Lokalaktiv 0;
BA_ "GenSigSendType" SG_ 2549088330 NM_TSG_FS_Lokalaktiv 0;
BA_ "GenSigSwitchedByIgnition" SG_ 2549088330 NM_TSG_FS_Subsystemaktiv 0;
BA_ "GenSigSendType" SG_ 2549088330 NM_TSG_FS_Subsystemaktiv 0;
BA_ "GenSigSwitchedByIgnition" SG_ 2549088330 TSG_FS_KD_Fehler 0;
BA_ "GenSigSendType" SG_ 2549088330 TSG_FS_KD_Fehler 0;
BA_ "GenSigSwitchedByIgnition" SG_ 2549088301 VSG_KompSchutz 0;
BA_ "GenSigSendType" SG_ 2549088301 VSG_KompSchutz 0;
BA_ "GenSigSwitchedByIgnition" SG_ 2549088301 VSG_Abschaltstufe 0;
BA_ "GenSigSendType" SG_ 2549088301 VSG_Abschaltstufe 0;
BA_ "GenSigSwitchedByIgnition" SG_ 2549088301 VSG_Transport_Mode 0;
BA_ "GenSigSendType" SG_ 2549088301 VSG_Transport_Mode 0;
BA_ "GenSigSwitchedByIgnition" SG_ 2549088301 VSG_Nachlauftyp 0;
BA_ "GenSigStartValue" SG_ 2549088301 VSG_Nachlauftyp 2;
BA_ "GenSigSendType" SG_ 2549088301 VSG_Nachlauftyp 0;
BA_ "GenSigSwitchedByIgnition" SG_ 2549088301 VSG_SNI 0;
BA_ "GenSigStartValue" SG_ 2549088301 VSG_SNI 45;
BA_ "GenSigSendType" SG_ 2549088301 VSG_SNI 0;
BA_ "GenSigSwitchedByIgnition" SG_ 2549088301 KN_VSG_BusKnockOutTimer 0;
BA_ "GenSigSendType" SG_ 2549088301 KN_VSG_BusKnockOutTimer 0;
BA_ "GenSigSwitchedByIgnition" SG_ 2549088301 NM_VSG_Wakeup 0;
BA_ "NWM-WakeupAllowed" SG_ 2549088301 NM_VSG_Wakeup 1;
BA_ "GenSigSendType" SG_ 2549088301 NM_VSG_Wakeup 0;
BA_ "GenSigSwitchedByIgnition" SG_ 2549088301 NM_VSG_Lokalaktiv 0;
BA_ "GenSigSendType" SG_ 2549088301 NM_VSG_Lokalaktiv 0;
BA_ "GenSigSwitchedByIgnition" SG_ 2549088301 NM_VSG_Subsystemaktiv 0;
BA_ "GenSigSendType" SG_ 2549088301 NM_VSG_Subsystemaktiv 0;
BA_ "GenSigSwitchedByIgnition" SG_ 2549088301 VSG_KD_Fehler 0;
BA_ "GenSigSendType" SG_ 2549088301 VSG_KD_Fehler 0;
BA_ "GenSigSwitchedByIgnition" SG_ 779 KBI_ABS_Lampe 0;
BA_ "GenSigSendType" SG_ 779 KBI_ABS_Lampe 0;
BA_ "GenSigSwitchedByIgnition" SG_ 779 KBI_ESP_Lampe 0;
BA_ "GenSigSendType" SG_ 779 KBI_ESP_Lampe 3;
BA_ "GenSigSwitchedByIgnition" SG_ 779 KBI_BKL_Lampe 0;
BA_ "GenSigSendType" SG_ 779 KBI_BKL_Lampe 0;
BA_ "GenSigSwitchedByIgnition" SG_ 779 KBI_Airbag_Lampe 0;
BA_ "GenSigSendType" SG_ 779 KBI_Airbag_Lampe 0;
BA_ "GenSigSwitchedByIgnition" SG_ 779 KBI_SILA_gueltig 0;
BA_ "GenSigSendType" SG_ 779 KBI_SILA_gueltig 0;
BA_ "GenSigSwitchedByIgnition" SG_ 779 KBI_Lenkung_Lampe 0;
BA_ "GenSigSendType" SG_ 779 KBI_Lenkung_Lampe 3;
BA_ "GenSigSwitchedByIgnition" SG_ 779 KBI_Vorglueh_System_Lampe 0;
BA_ "GenSigSendType" SG_ 779 KBI_Vorglueh_System_Lampe 0;
BA_ "GenSigSwitchedByIgnition" SG_ 779 KBI_NV_in_Anzeige 0;
BA_ "GenSigSendType" SG_ 779 KBI_NV_in_Anzeige 0;
BA_ "GenSigSwitchedByIgnition" SG_ 779 Kombi_01_BZ 0;
BA_ "GenSigFuncType" SG_ 779 Kombi_01_BZ 1;
BA_ "GenSigSendType" SG_ 779 Kombi_01_BZ 0;
BA_ "GenSigSwitchedByIgnition" SG_ 779 KBI_Anzeigestatus_ACC 0;
BA_ "GenSigSendType" SG_ 779 KBI_Anzeigestatus_ACC 0;
BA_ "Fehlerwert" SG_ 779 KBI_Anzeigestatus_GRA 3;
BA_ "GenSigSwitchedByIgnition" SG_ 779 KBI_Anzeigestatus_GRA 0;
BA_ "GenSigSendType" SG_ 779 KBI_Anzeigestatus_GRA 0;
BA_ "GenSigSwitchedByIgnition" SG_ 779 KBI_Oeldruck_Schalter 0;
BA_ "GenSigSendType" SG_ 779 KBI_Oeldruck_Schalter 0;
BA_ "GenSigSwitchedByIgnition" SG_ 779 KBI_Tankwarnung 0;
BA_ "GenSigSendType" SG_ 779 KBI_Tankwarnung 3;
BA_ "GenSigSwitchedByIgnition" SG_ 779 KBI_MFA_v_Einheit_01 0;
BA_ "GenSigSendType" SG_ 779 KBI_MFA_v_Einheit_01 0;
BA_ "GenSigSwitchedByIgnition" SG_ 779 KBI_im_Stellgliedtest 0;
BA_ "GenSigSendType" SG_ 779 KBI_im_Stellgliedtest 0;
BA_ "GenSigSwitchedByIgnition" SG_ 779 KBI_Anzeigefehler_LDW 0;
BA_ "GenSigSendType" SG_ 779 KBI_Anzeigefehler_LDW 0;
BA_ "GenSigSwitchedByIgnition" SG_ 779 KBI_Oeldruckwarnung 0;
BA_ "GenSigSendType" SG_ 779 KBI_Oeldruckwarnung 0;
BA_ "GenSigSwitchedByIgnition" SG_ 779 KBI_Handbremse 0;
BA_ "GenSigSendType" SG_ 779 KBI_Handbremse 0;
BA_ "GenSigSwitchedByIgnition" SG_ 779 KBI_V_Digital 0;
BA_ "GenSigSendType" SG_ 779 KBI_V_Digital 0;
BA_ "GenSigSwitchedByIgnition" SG_ 779 KBI_PLA_in_Anzeige 0;
BA_ "GenSigSendType" SG_ 779 KBI_PLA_in_Anzeige 3;
BA_ "GenSigSwitchedByIgnition" SG_ 779 KBI_Anzeigefehler_NV 0;
BA_ "GenSigSendType" SG_ 779 KBI_Anzeigefehler_NV 0;
BA_ "Fehlerwert" SG_ 779 KBI_Anzeigestatus_LIM 3;
BA_ "GenSigSwitchedByIgnition" SG_ 779 KBI_Anzeigestatus_LIM 0;
BA_ "GenSigSendType" SG_ 779 KBI_Anzeigestatus_LIM 0;
BA_ "GenSigSwitchedByIgnition" SG_ 779 KBI_ARA_in_Anzeige 0;
BA_ "GenSigSendType" SG_ 779 KBI_ARA_in_Anzeige 0;
BA_ "GenSigSwitchedByIgnition" SG_ 779 KBI_angez_Geschw 0;
BA_ "GenSigSendType" SG_ 779 KBI_angez_Geschw 0;
BA_ "GenSigSwitchedByIgnition" SG_ 779 KBI_Einheit_Tacho 0;
BA_ "GenSigSendType" SG_ 779 KBI_Einheit_Tacho 0;
BA_ "GenSigSwitchedByIgnition" SG_ 779 KBI_Konsistenz_ACC 0;
BA_ "GenSigSendType" SG_ 779 KBI_Konsistenz_ACC 0;
BA_ "GenSigSwitchedByIgnition" SG_ 779 KBI_Fehler_Anzeige_ACC 0;
BA_ "GenSigSendType" SG_ 779 KBI_Fehler_Anzeige_ACC 0;
BA_ "GenSigSwitchedByIgnition" SG_ 779 KBI_Anzeigefehler_SWA 0;
BA_ "GenSigSendType" SG_ 779 KBI_Anzeigefehler_SWA 0;
BA_ "Fehlerwert" SG_ 1719 KBI_Kilometerstand 1048575;
BA_ "GenSigSwitchedByIgnition" SG_ 1719 KBI_Kilometerstand 0;
BA_ "GenSigStartValue" SG_ 1719 KBI_Kilometerstand 1048574;
BA_ "GenSigSendType" SG_ 1719 KBI_Kilometerstand 0;
BA_ "Fehlerwert" SG_ 1719 KBI_Standzeit_02 131071;
BA_ "GenSigSwitchedByIgnition" SG_ 1719 KBI_Standzeit_02 0;
BA_ "GenSigStartValue" SG_ 1719 KBI_Standzeit_02 131070;
BA_ "GenSigSendType" SG_ 1719 KBI_Standzeit_02 0;
BA_ "GenSigSwitchedByIgnition" SG_ 1719 KBI_Reserve_Warnung_Sek 0;
BA_ "GenSigSendType" SG_ 1719 KBI_Reserve_Warnung_Sek 3;
BA_ "GenSigSwitchedByIgnition" SG_ 1719 KBI_RDK_Kalibrier_Anf 0;
BA_ "GenSigSendType" SG_ 1719 KBI_RDK_Kalibrier_Anf 3;
BA_ "Fehlerwert" SG_ 1719 KBI_Inhalt_Tank 127;
BA_ "GenSigSwitchedByIgnition" SG_ 1719 KBI_Inhalt_Tank 0;
BA_ "GenSigStartValue" SG_ 1719 KBI_Inhalt_Tank 126;
BA_ "GenSigSendType" SG_ 1719 KBI_Inhalt_Tank 0;
BA_ "GenSigSwitchedByIgnition" SG_ 1719 KBI_FStatus_Tank 0;
BA_ "GenSigSendType" SG_ 1719 KBI_FStatus_Tank 0;
BA_ "GenSigSwitchedByIgnition" SG_ 1719 KBI_Oelwechsel_durchgefuehrt 0;
BA_ "GenSigSendType" SG_ 1719 KBI_Oelwechsel_durchgefuehrt 0;
BA_ "GenSigSwitchedByIgnition" SG_ 1719 KBI_QBit_Aussen_Temp_gef 0;
BA_ "GenSigStartValue" SG_ 1719 KBI_QBit_Aussen_Temp_gef 1;
BA_ "GenSigSendType" SG_ 1719 KBI_QBit_Aussen_Temp_gef 0;
BA_ "Fehlerwert" SG_ 1719 KBI_Aussen_Temp_gef 255;
BA_ "GenSigSwitchedByIgnition" SG_ 1719 KBI_Aussen_Temp_gef 0;
BA_ "GenSigStartValue" SG_ 1719 KBI_Aussen_Temp_gef 254;
BA_ "GenSigSendType" SG_ 1719 KBI_Aussen_Temp_gef 0;
BA_ "GenSigSwitchedByIgnition" SG_ 1720 KBI_Reifenumfang 0;
BA_ "GenSigFuncType" SG_ 1720 KBI_Reifenumfang 8;
BA_ "GenSigSendType" SG_ 1720 KBI_Reifenumfang 0;
BA_ "GenSigSwitchedByIgnition" SG_ 1720 KBI_Variante_USA 0;
BA_ "GenSigSendType" SG_ 1720 KBI_Variante_USA 0;
BA_ "GenSigSwitchedByIgnition" SG_ 1720 KBI_Variante 0;
BA_ "GenSigSendType" SG_ 1720 KBI_Variante 0;
BA_ "GenSigSwitchedByIgnition" SG_ 1720 KBI_BCmE_aktiv 0;
BA_ "GenSigSendType" SG_ 1720 KBI_BCmE_aktiv 0;
BA_ "GenSigSwitchedByIgnition" SG_ 1720 KBI_Sparhinweis_quittiert 0;
BA_ "GenSigSendType" SG_ 1720 KBI_Sparhinweis_quittiert 0;
BA_ "Fehlerwert" SG_ 1720 KBI_Tankfuellstand_Prozent 127;
BA_ "GenSigSwitchedByIgnition" SG_ 1720 KBI_Tankfuellstand_Prozent 0;
BA_ "GenSigStartValue" SG_ 1720 KBI_Tankfuellstand_Prozent 126;
BA_ "GenSigSendType" SG_ 1720 KBI_Tankfuellstand_Prozent 0;
BA_ "GenSigSwitchedByIgnition" SG_ 1720 KBI_Nachtanken_erkannt 0;
BA_ "GenSigSendType" SG_ 1720 KBI_Nachtanken_erkannt 0;
BA_ "Fehlerwert" SG_ 1720 KBI_Tankinhalt_hochaufl 16383;
BA_ "GenSigSwitchedByIgnition" SG_ 1720 KBI_Tankinhalt_hochaufl 0;
BA_ "GenSigStartValue" SG_ 1720 KBI_Tankinhalt_hochaufl 16382;
BA_ "GenSigSendType" SG_ 1720 KBI_Tankinhalt_hochaufl 0;
BA_ "Fehlerwert" SG_ 1720 KBI_Max_Tankinhalt 255;
BA_ "GenSigSwitchedByIgnition" SG_ 1720 KBI_Max_Tankinhalt 0;
BA_ "GenSigStartValue" SG_ 1720 KBI_Max_Tankinhalt 254;
BA_ "GenSigSendType" SG_ 1720 KBI_Max_Tankinhalt 0;
BA_ "GenSigSwitchedByIgnition" SG_ 1720 KBI_Reifenumfang_Sekundaer 0;
BA_ "GenSigSendType" SG_ 1720 KBI_Reifenumfang_Sekundaer 0;
BA_ "GenSigSwitchedByIgnition" SG_ 1724 KBI_Oil_dis_status 0;
BA_ "GenSigSendType" SG_ 1724 KBI_Oil_dis_status 0;
BA_ "GenSigSwitchedByIgnition" SG_ 1724 KBI_Oil_dis_unit 0;
BA_ "GenSigSendType" SG_ 1724 KBI_Oil_dis_unit 0;
BA_ "GenSigSwitchedByIgnition" SG_ 1724 KBI_Oil_dis 0;
BA_ "GenSigSendType" SG_ 1724 KBI_Oil_dis 0;
BA_ "GenSigSwitchedByIgnition" SG_ 1724 KBI_Oil_time_status 0;
BA_ "GenSigSendType" SG_ 1724 KBI_Oil_time_status 0;
BA_ "GenSigSwitchedByIgnition" SG_ 1724 KBI_Oil_time 0;
BA_ "GenSigSendType" SG_ 1724 KBI_Oil_time 0;
BA_ "GenSigSwitchedByIgnition" SG_ 1724 KBI_Insp_dis_status 0;
BA_ "GenSigSendType" SG_ 1724 KBI_Insp_dis_status 0;
BA_ "GenSigSwitchedByIgnition" SG_ 1724 KBI_Insp_dis_unit 0;
BA_ "GenSigSendType" SG_ 1724 KBI_Insp_dis_unit 0;
BA_ "GenSigSwitchedByIgnition" SG_ 1724 KBI_Insp_dis 0;
BA_ "GenSigSendType" SG_ 1724 KBI_Insp_dis 0;
BA_ "GenSigSwitchedByIgnition" SG_ 1724 KBI_Insp_time_status 0;
BA_ "GenSigSendType" SG_ 1724 KBI_Insp_time_status 0;
BA_ "GenSigSwitchedByIgnition" SG_ 1724 KBI_Insp_time 0;
BA_ "GenSigSendType" SG_ 1724 KBI_Insp_time 0;
BA_ "GenSigSwitchedByIgnition" SG_ 1724 KBI_Warnung_ID 0;
BA_ "GenSigSendType" SG_ 1724 KBI_Warnung_ID 0;
BA_ "GenSigSwitchedByIgnition" SG_ 2589283471 KBI_Signatur_Wegstrecke_01 0;
BA_ "GenSigSendType" SG_ 2589283471 KBI_Signatur_Wegstrecke_01 0;
BA_ "GenSigSwitchedByIgnition" SG_ 2589283471 KBI_Status_Aktive_Meldungen 0;
BA_ "GenSigSendType" SG_ 2589283471 KBI_Status_Aktive_Meldungen 3;
BA_ "GenSigSwitchedByIgnition" SG_ 2589283471 KBI_Status_Historie_Meldungen 0;
BA_ "GenSigSendType" SG_ 2589283471 KBI_Status_Historie_Meldungen 3;
BA_ "GenSigSwitchedByIgnition" SG_ 2589283471 KBI_Status_SK_Meldungen 0;
BA_ "GenSigSendType" SG_ 2589283471 KBI_Status_SK_Meldungen 3;
BA_ "GenSigSwitchedByIgnition" SG_ 2589283471 KBI_Wegstrecke 0;
BA_ "GenSigStartValue" SG_ 2589283471 KBI_Wegstrecke 1048575;
BA_ "GenSigSendType" SG_ 2589283471 KBI_Wegstrecke 0;
BA_ "GenSigSwitchedByIgnition" SG_ 2589283471 KBI_Signatur_Wegstrecke_02 0;
BA_ "GenSigSendType" SG_ 2589283471 KBI_Signatur_Wegstrecke_02 0;
BA_ "GenSigSwitchedByIgnition" SG_ 2549874958 KS_BCM1_Req_Data 0;
BA_ "GenSigFuncType" SG_ 2549874958 KS_BCM1_Req_Data 9;
BA_ "GenSigSwitchedByIgnition" SG_ 2550006030 KS_BCM1_Resp_Data 0;
BA_ "GenSigFuncType" SG_ 2550006030 KS_BCM1_Resp_Data 9;
BA_ "GenSigSwitchedByIgnition" SG_ 2549875083 KS_BCM2_Req_Data 0;
BA_ "GenSigFuncType" SG_ 2549875083 KS_BCM2_Req_Data 9;
BA_ "GenSigSwitchedByIgnition" SG_ 2550006155 KS_BCM2_Resp_Data 0;
BA_ "GenSigFuncType" SG_ 2550006155 KS_BCM2_Resp_Data 9;
BA_ "GenSigSendType" SG_ 919 LDW_Gong 0;
BA_ "Fehlerwert" SG_ 919 LDW_Frueh_Spaet 3;
BA_ "GenSigStartValue" SG_ 919 LDW_Frueh_Spaet 2;
BA_ "GenSigSendType" SG_ 919 LDW_Frueh_Spaet 0;
BA_ "GenSigSendType" SG_ 919 LDW_Texte 0;
BA_ "GenSigSendType" SG_ 919 LDW_Seite_DLCTLC 0;
BA_ "GenSigSendType" SG_ 919 LDW_Lernmodus 0;
BA_ "GenSigSendType" SG_ 919 LDW_Anlaufsp_VLR 3;
BA_ "GenSigSendType" SG_ 919 LDW_Vib_Amp_VLR 3;
BA_ "GenSigSendType" SG_ 919 LDW_Anlaufzeit_VLR 3;
BA_ "GenSigSendType" SG_ 919 LDW_Lernmodus_seitenabhaengig 3;
BA_ "GenSigStartValue" SG_ 919 LDW_DLC 250;
BA_ "GenSigSendType" SG_ 919 LDW_DLC 0;
BA_ "GenSigStartValue" SG_ 919 LDW_TLC 31;
BA_ "GenSigSendType" SG_ 919 LDW_TLC 0;
BA_ "GenSigSendType" SG_ 919 HC_Uss_Anforderung 0;
BA_ "GenSigSendType" SG_ 919 EA_Warnblinken 0;
BA_ "GenSigSendType" SG_ 919 LDW_Warnung_links 3;
BA_ "GenSigSendType" SG_ 919 LDW_Warnung_rechts 3;
BA_ "GenSigSendType" SG_ 919 LDW_Codierinfo_fuer_VLR 0;
BA_ "GenSigSendType" SG_ 919 LDW_Status_LED_gelb 0;
BA_ "GenSigSendType" SG_ 919 LDW_Status_LED_gruen 0;
BA_ "GenSigSwitchedByIgnition" SG_ 810 EPS_01_CRC 0;
BA_ "GenSigFuncType" SG_ 810 EPS_01_CRC 2;
BA_ "GenSigSendType" SG_ 810 EPS_01_CRC 0;
BA_ "GenSigSwitchedByIgnition" SG_ 810 EPS_01_BZ 0;
BA_ "GenSigFuncType" SG_ 810 EPS_01_BZ 1;
BA_ "GenSigSendType" SG_ 810 EPS_01_BZ 0;
BA_ "GenSigSwitchedByIgnition" SG_ 810 EPS_SpannungsAnf 0;
BA_ "GenSigSendType" SG_ 810 EPS_SpannungsAnf 0;
BA_ "GenSigSwitchedByIgnition" SG_ 810 EPS_Fehlerlampe 0;
BA_ "GenSigSendType" SG_ 810 EPS_Fehlerlampe 0;
BA_ "GenSigSwitchedByIgnition" SG_ 810 EPS_Warnungen 0;
BA_ "GenSigSendType" SG_ 810 EPS_Warnungen 0;
BA_ "GenSigSwitchedByIgnition" SG_ 810 EPS_PWR_Abbruch 0;
BA_ "GenSigSendType" SG_ 810 EPS_PWR_Abbruch 0;
BA_ "GenSigSwitchedByIgnition" SG_ 810 EPS_PWR_Fehler 0;
BA_ "GenSigSendType" SG_ 810 EPS_PWR_Fehler 0;
BA_ "GenSigSwitchedByIgnition" SG_ 810 EPS_PLA_Status 0;
BA_ "GenSigSendType" SG_ 810 EPS_PLA_Status 0;
BA_ "GenSigSwitchedByIgnition" SG_ 810 EPS_Charisma_FahrPr 0;
BA_ "GenSigSendType" SG_ 810 EPS_Charisma_FahrPr 0;
BA_ "GenSigSwitchedByIgnition" SG_ 810 EPS_Charisma_Status 0;
BA_ "GenSigSendType" SG_ 810 EPS_Charisma_Status 0;
BA_ "GenSigSwitchedByIgnition" SG_ 810 EPS_Lenkerposition 0;
BA_ "GenSigFuncType" SG_ 810 EPS_Lenkerposition 8;
BA_ "GenSigSendType" SG_ 810 EPS_Lenkerposition 0;
BA_ "GenSigSwitchedByIgnition" SG_ 810 EPS_Anf_KL 0;
BA_ "GenSigSendType" SG_ 810 EPS_Anf_KL 0;
BA_ "GenSigSwitchedByIgnition" SG_ 810 EPS_ARA_Status 0;
BA_ "GenSigSendType" SG_ 810 EPS_ARA_Status 0;
BA_ "GenSigSwitchedByIgnition" SG_ 160 EPS_04_CRC 0;
BA_ "GenSigFuncType" SG_ 160 EPS_04_CRC 2;
BA_ "GenSigSendType" SG_ 160 EPS_04_CRC 0;
BA_ "GenSigSwitchedByIgnition" SG_ 160 EPS_04_BZ 0;
BA_ "GenSigFuncType" SG_ 160 EPS_04_BZ 1;
BA_ "GenSigSendType" SG_ 160 EPS_04_BZ 0;
BA_ "Fehlerwert" SG_ 160 EPS_Lenkmoment_AbsReduz 15;
BA_ "GenSigSwitchedByIgnition" SG_ 160 EPS_Lenkmoment_AbsReduz 0;
BA_ "GenSigStartValue" SG_ 160 EPS_Lenkmoment_AbsReduz 14;
BA_ "GenSigSendType" SG_ 160 EPS_Lenkmoment_AbsReduz 0;
BA_ "Fehlerwert" SG_ 160 EPS_Zahnstangen_Pos 4095;
BA_ "GenSigSwitchedByIgnition" SG_ 160 EPS_Zahnstangen_Pos 0;
BA_ "GenSigStartValue" SG_ 160 EPS_Zahnstangen_Pos 4094;
BA_ "GenSigSendType" SG_ 160 EPS_Zahnstangen_Pos 0;
BA_ "GenSigSwitchedByIgnition" SG_ 160 EPS_VZ_Zahnstangenposition 0;
BA_ "GenSigSendType" SG_ 160 EPS_VZ_Zahnstangenposition 0;
BA_ "GenSigSwitchedByIgnition" SG_ 160 EPS_QBit_Zahnstangen_Pos 0;
BA_ "GenSigSendType" SG_ 160 EPS_QBit_Zahnstangen_Pos 0;
BA_ "GenSigSwitchedByIgnition" SG_ 160 EPS_Versorgungsstatus 0;
BA_ "GenSigSendType" SG_ 160 EPS_Versorgungsstatus 0;
BA_ "Fehlerwert" SG_ 160 EPS_Versorgungsspannung 255;
BA_ "GenSigSwitchedByIgnition" SG_ 160 EPS_Versorgungsspannung 0;
BA_ "GenSigStartValue" SG_ 160 EPS_Versorgungsspannung 254;
BA_ "GenSigSendType" SG_ 160 EPS_Versorgungsspannung 0;
BA_ "GenSigSwitchedByIgnition" SG_ 160 EPS_AWA_Status 0;
BA_ "GenSigStartValue" SG_ 160 EPS_AWA_Status 14;
BA_ "GenSigSendType" SG_ 160 EPS_AWA_Status 0;
BA_ "GenSigSwitchedByIgnition" SG_ 160 EPS_STA_Status 0;
BA_ "GenSigStartValue" SG_ 160 EPS_STA_Status 14;
BA_ "GenSigSendType" SG_ 160 EPS_STA_Status 0;
BA_ "GenSigSwitchedByIgnition" SG_ 981 Licht_Anf_01_CRC 0;
BA_ "GenSigFuncType" SG_ 981 Licht_Anf_01_CRC 2;
BA_ "GenSigSendType" SG_ 981 Licht_Anf_01_CRC 0;
BA_ "GenSigSwitchedByIgnition" SG_ 981 Licht_Anf_01_BZ 0;
BA_ "GenSigFuncType" SG_ 981 Licht_Anf_01_BZ 1;
BA_ "GenSigSendType" SG_ 981 Licht_Anf_01_BZ 0;
BA_ "GenSigSwitchedByIgnition" SG_ 981 BCM1_Kurvenlicht_links_Anf 0;
BA_ "GenSigSendType" SG_ 981 BCM1_Kurvenlicht_links_Anf 0;
BA_ "GenSigSwitchedByIgnition" SG_ 981 BCM1_Kurvenlicht_rechts_Anf 0;
BA_ "GenSigSendType" SG_ 981 BCM1_Kurvenlicht_rechts_Anf 0;
BA_ "GenSigSwitchedByIgnition" SG_ 981 BCM1_Standlicht_Anf 0;
BA_ "GenSigSendType" SG_ 981 BCM1_Standlicht_Anf 0;
BA_ "GenSigSwitchedByIgnition" SG_ 981 BCM1_Abblendlicht_Anf 0;
BA_ "GenSigSendType" SG_ 981 BCM1_Abblendlicht_Anf 0;
BA_ "GenSigSwitchedByIgnition" SG_ 981 BCM1_Fernlicht_Anf 0;
BA_ "GenSigSendType" SG_ 981 BCM1_Fernlicht_Anf 0;
BA_ "GenSigSwitchedByIgnition" SG_ 981 BCM1_Nebellicht_Anf 0;
BA_ "GenSigSendType" SG_ 981 BCM1_Nebellicht_Anf 0;
BA_ "GenSigSwitchedByIgnition" SG_ 981 BCM1_Parklicht_li_Anf 0;
BA_ "GenSigSendType" SG_ 981 BCM1_Parklicht_li_Anf 0;
BA_ "GenSigSwitchedByIgnition" SG_ 981 BCM1_Parklicht_re_Anf 0;
BA_ "GenSigSendType" SG_ 981 BCM1_Parklicht_re_Anf 0;
BA_ "GenSigSwitchedByIgnition" SG_ 981 BCM1_Nebelschluss_Ahg_Anf 0;
BA_ "GenSigSendType" SG_ 981 BCM1_Nebelschluss_Ahg_Anf 0;
BA_ "GenSigSwitchedByIgnition" SG_ 981 BCM1_Nebelschluss_Fzg_Anf 0;
BA_ "GenSigSendType" SG_ 981 BCM1_Nebelschluss_Fzg_Anf 0;
BA_ "GenSigSwitchedByIgnition" SG_ 981 BCM1_Schlusslicht_Anf 0;
BA_ "GenSigSendType" SG_ 981 BCM1_Schlusslicht_Anf 0;
BA_ "GenSigSwitchedByIgnition" SG_ 981 BCM_Rueckfahrlicht_Anf 0;
BA_ "GenSigSendType" SG_ 981 BCM_Rueckfahrlicht_Anf 0;
BA_ "GenSigSwitchedByIgnition" SG_ 981 BCM1_Umfeldleuchten_Anf 0;
BA_ "GenSigSendType" SG_ 981 BCM1_Umfeldleuchten_Anf 0;
BA_ "GenSigSwitchedByIgnition" SG_ 981 BCM1_Tagfahrlicht_Anf 0;
BA_ "GenSigSendType" SG_ 981 BCM1_Tagfahrlicht_Anf 0;
BA_ "GenSigSwitchedByIgnition" SG_ 981 BCM1_Regenlicht_Anf 0;
BA_ "GenSigSendType" SG_ 981 BCM1_Regenlicht_Anf 0;
BA_ "GenSigSwitchedByIgnition" SG_ 981 BCM1_Autobahnlicht_Anf 0;
BA_ "GenSigSendType" SG_ 981 BCM1_Autobahnlicht_Anf 0;
BA_ "GenSigSwitchedByIgnition" SG_ 981 BCM1_Touristen_Licht_Anf 0;
BA_ "GenSigSendType" SG_ 981 BCM1_Touristen_Licht_Anf 0;
BA_ "GenSigSwitchedByIgnition" SG_ 981 BCM1_Gleitende_Leuchtw_Anf 0;
BA_ "GenSigSendType" SG_ 981 BCM1_Gleitende_Leuchtw_Anf 0;
BA_ "GenSigSwitchedByIgnition" SG_ 981 BCM1_GLW_Fernlicht_Anf 0;
BA_ "GenSigSendType" SG_ 981 BCM1_GLW_Fernlicht_Anf 0;
BA_ "GenSigSwitchedByIgnition" SG_ 981 BCM1_Adaptive_Lichtvert_Anf 0;
BA_ "GenSigSendType" SG_ 981 BCM1_Adaptive_Lichtvert_Anf 0;
BA_ "GenSigSwitchedByIgnition" SG_ 981 BCM1_CH_LH_aktiv 0;
BA_ "GenSigSendType" SG_ 981 BCM1_CH_LH_aktiv 0;
BA_ "GenSigSwitchedByIgnition" SG_ 981 BCM1_Allwetterlicht_Anf 0;
BA_ "GenSigSendType" SG_ 981 BCM1_Allwetterlicht_Anf 0;
BA_ "GenSigSwitchedByIgnition" SG_ 982 BCM2_Bremsl_durch_ECD 0;
BA_ "GenSigSendType" SG_ 982 BCM2_Bremsl_durch_ECD 0;
BA_ "GenSigSwitchedByIgnition" SG_ 982 LH_Aussenlicht_def 0;
BA_ "GenSigSendType" SG_ 982 LH_Aussenlicht_def 0;
BA_ "GenSigSwitchedByIgnition" SG_ 982 LH_Standlicht_H_aktiv 0;
BA_ "GenSigSendType" SG_ 982 LH_Standlicht_H_aktiv 0;
BA_ "GenSigSwitchedByIgnition" SG_ 982 LH_Parklicht_HL_aktiv 0;
BA_ "GenSigSendType" SG_ 982 LH_Parklicht_HL_aktiv 0;
BA_ "GenSigSwitchedByIgnition" SG_ 982 LH_Parklicht_HR_aktiv 0;
BA_ "GenSigSendType" SG_ 982 LH_Parklicht_HR_aktiv 0;
BA_ "GenSigSwitchedByIgnition" SG_ 982 LH_Bremslicht_H_aktiv 0;
BA_ "GenSigSendType" SG_ 982 LH_Bremslicht_H_aktiv 0;
BA_ "GenSigSwitchedByIgnition" SG_ 982 LH_Nebelschluss_aktiv 0;
BA_ "GenSigSendType" SG_ 982 LH_Nebelschluss_aktiv 0;
BA_ "GenSigSwitchedByIgnition" SG_ 982 LH_Rueckfahrlicht_aktiv 0;
BA_ "GenSigSendType" SG_ 982 LH_Rueckfahrlicht_aktiv 0;
BA_ "GenSigSwitchedByIgnition" SG_ 982 LH_Blinker_HL_akt 0;
BA_ "GenSigSendType" SG_ 982 LH_Blinker_HL_akt 0;
BA_ "GenSigSwitchedByIgnition" SG_ 982 LH_Blinker_HR_akt 0;
BA_ "GenSigSendType" SG_ 982 LH_Blinker_HR_akt 0;
BA_ "GenSigSwitchedByIgnition" SG_ 982 LH_Blinker_li_def 0;
BA_ "GenSigSendType" SG_ 982 LH_Blinker_li_def 0;
BA_ "GenSigSwitchedByIgnition" SG_ 982 LH_Bremsl_li_def 0;
BA_ "GenSigSendType" SG_ 982 LH_Bremsl_li_def 0;
BA_ "GenSigSwitchedByIgnition" SG_ 982 LH_Schlusslicht_li_def 0;
BA_ "GenSigSendType" SG_ 982 LH_Schlusslicht_li_def 0;
BA_ "GenSigSwitchedByIgnition" SG_ 982 LH_Rueckf_li_def 0;
BA_ "GenSigSendType" SG_ 982 LH_Rueckf_li_def 0;
BA_ "GenSigSwitchedByIgnition" SG_ 982 LH_Nebel_li_def 0;
BA_ "GenSigSendType" SG_ 982 LH_Nebel_li_def 0;
BA_ "GenSigSwitchedByIgnition" SG_ 982 LH_Schluss_Brems_Nebel_li_def 0;
BA_ "GenSigSendType" SG_ 982 LH_Schluss_Brems_Nebel_li_def 0;
BA_ "GenSigSwitchedByIgnition" SG_ 982 LH_Schluss_Brems_Nebel_re_def 0;
BA_ "GenSigSendType" SG_ 982 LH_Schluss_Brems_Nebel_re_def 0;
BA_ "GenSigSwitchedByIgnition" SG_ 982 LH_Schluss_Brems_li_def 0;
BA_ "GenSigSendType" SG_ 982 LH_Schluss_Brems_li_def 0;
BA_ "GenSigSwitchedByIgnition" SG_ 982 LH_Schluss_Nebel_li_def 0;
BA_ "GenSigSendType" SG_ 982 LH_Schluss_Nebel_li_def 0;
BA_ "GenSigSwitchedByIgnition" SG_ 982 LH_SL_BRL_BLK_li_def 0;
BA_ "GenSigSendType" SG_ 982 LH_SL_BRL_BLK_li_def 0;
BA_ "GenSigSwitchedByIgnition" SG_ 982 LH_Brems_Blk_li_def 0;
BA_ "GenSigSendType" SG_ 982 LH_Brems_Blk_li_def 0;
BA_ "GenSigSwitchedByIgnition" SG_ 982 LH_Blinker_re_def 0;
BA_ "GenSigSendType" SG_ 982 LH_Blinker_re_def 0;
BA_ "GenSigSwitchedByIgnition" SG_ 982 LH_Bremsl_re_def 0;
BA_ "GenSigSendType" SG_ 982 LH_Bremsl_re_def 0;
BA_ "GenSigSwitchedByIgnition" SG_ 982 LH_Schlusslicht_re_def 0;
BA_ "GenSigSendType" SG_ 982 LH_Schlusslicht_re_def 0;
BA_ "GenSigSwitchedByIgnition" SG_ 982 LH_Rueckf_re_def 0;
BA_ "GenSigSendType" SG_ 982 LH_Rueckf_re_def 0;
BA_ "GenSigSwitchedByIgnition" SG_ 982 LH_Nebel_re_def 0;
BA_ "GenSigSendType" SG_ 982 LH_Nebel_re_def 0;
BA_ "GenSigSwitchedByIgnition" SG_ 982 LH_Schluss_Brems_re_def 0;
BA_ "GenSigSendType" SG_ 982 LH_Schluss_Brems_re_def 0;
BA_ "GenSigSwitchedByIgnition" SG_ 982 LH_Schluss_Nebel_re_def 0;
BA_ "GenSigSendType" SG_ 982 LH_Schluss_Nebel_re_def 0;
BA_ "GenSigSwitchedByIgnition" SG_ 982 LH_SL_BRL_BLK_re_def 0;
BA_ "GenSigSendType" SG_ 982 LH_SL_BRL_BLK_re_def 0;
BA_ "GenSigSwitchedByIgnition" SG_ 982 LH_Brems_Blk_re_def 0;
BA_ "GenSigSendType" SG_ 982 LH_Brems_Blk_re_def 0;
BA_ "GenSigSwitchedByIgnition" SG_ 982 LH_Kennzl_def 0;
BA_ "GenSigSendType" SG_ 982 LH_Kennzl_def 0;
BA_ "GenSigSwitchedByIgnition" SG_ 982 LH_3_Bremsl_def 0;
BA_ "GenSigSendType" SG_ 982 LH_3_Bremsl_def 0;
BA_ "GenSigSwitchedByIgnition" SG_ 982 LH_Nebel_mi_def 0;
BA_ "GenSigSendType" SG_ 982 LH_Nebel_mi_def 0;
BA_ "GenSigSwitchedByIgnition" SG_ 982 LH_Rueckf_mi_def 0;
BA_ "GenSigSendType" SG_ 982 LH_Rueckf_mi_def 0;
BA_ "GenSigSwitchedByIgnition" SG_ 982 LH_Bremsl_li_ges_def 0;
BA_ "GenSigSendType" SG_ 982 LH_Bremsl_li_ges_def 0;
BA_ "GenSigSwitchedByIgnition" SG_ 982 LH_Bremsl_re_ges_def 0;
BA_ "GenSigSendType" SG_ 982 LH_Bremsl_re_ges_def 0;
BA_ "GenSigFuncType" SG_ 1624 Licht_Vorne_01_CRC 2;
BA_ "GenSigSendType" SG_ 1624 Licht_Vorne_01_CRC 0;
BA_ "GenSigFuncType" SG_ 1624 Licht_Vorne_01_BZ 1;
BA_ "GenSigSendType" SG_ 1624 Licht_Vorne_01_BZ 0;
BA_ "GenSigSwitchedByIgnition" SG_ 1624 LV_Standlicht_Anzeige 0;
BA_ "GenSigSendType" SG_ 1624 LV_Standlicht_Anzeige 3;
BA_ "GenSigSwitchedByIgnition" SG_ 1624 LV_Abblendlicht_Anzeige 0;
BA_ "GenSigSendType" SG_ 1624 LV_Abblendlicht_Anzeige 3;
BA_ "GenSigSwitchedByIgnition" SG_ 1624 LV_Fernlicht_Anzeige 0;
BA_ "GenSigSendType" SG_ 1624 LV_Fernlicht_Anzeige 3;
BA_ "GenSigSwitchedByIgnition" SG_ 1624 LV_Nebellicht_Anzeige 0;
BA_ "GenSigSendType" SG_ 1624 LV_Nebellicht_Anzeige 3;
BA_ "GenSigSwitchedByIgnition" SG_ 1624 LV_Nebelschlusslicht_Anzeige 0;
BA_ "GenSigSendType" SG_ 1624 LV_Nebelschlusslicht_Anzeige 3;
BA_ "GenSigSwitchedByIgnition" SG_ 1624 LV_Tagfahrlicht_Anzeige 0;
BA_ "GenSigSendType" SG_ 1624 LV_Tagfahrlicht_Anzeige 3;
BA_ "GenSigSwitchedByIgnition" SG_ 1624 LV_AFL_aktiv_Anzeige 0;
BA_ "GenSigSendType" SG_ 1624 LV_AFL_aktiv_Anzeige 3;
BA_ "GenSigSwitchedByIgnition" SG_ 1624 LV_AFL_defekt 0;
BA_ "GenSigSendType" SG_ 1624 LV_AFL_defekt 3;
BA_ "GenSigSwitchedByIgnition" SG_ 1624 LV_Blinker_li_def 0;
BA_ "GenSigSendType" SG_ 1624 LV_Blinker_li_def 3;
BA_ "GenSigSwitchedByIgnition" SG_ 1624 LV_Standlicht_li_def 0;
BA_ "GenSigSendType" SG_ 1624 LV_Standlicht_li_def 0;
BA_ "GenSigSwitchedByIgnition" SG_ 1624 LV_Abblendlicht_li_def 0;
BA_ "GenSigSendType" SG_ 1624 LV_Abblendlicht_li_def 0;
BA_ "GenSigSwitchedByIgnition" SG_ 1624 LV_Fernlicht_li_def 0;
BA_ "GenSigSendType" SG_ 1624 LV_Fernlicht_li_def 0;
BA_ "GenSigSwitchedByIgnition" SG_ 1624 LV_Nebellicht_li_def 0;
BA_ "GenSigSendType" SG_ 1624 LV_Nebellicht_li_def 0;
BA_ "GenSigSwitchedByIgnition" SG_ 1624 LV_Blk_li_Seite_def 0;
BA_ "GenSigSendType" SG_ 1624 LV_Blk_li_Seite_def 0;
BA_ "GenSigSwitchedByIgnition" SG_ 1624 LV_Tagfahrlicht_li_def 0;
BA_ "GenSigSendType" SG_ 1624 LV_Tagfahrlicht_li_def 0;
BA_ "GenSigSwitchedByIgnition" SG_ 1624 LV_FLA_aktiv_Anzeige 0;
BA_ "GenSigSendType" SG_ 1624 LV_FLA_aktiv_Anzeige 3;
BA_ "GenSigSwitchedByIgnition" SG_ 1624 LV_FLA_defekt 0;
BA_ "GenSigSendType" SG_ 1624 LV_FLA_defekt 0;
BA_ "GenSigSwitchedByIgnition" SG_ 1624 LV_FLA_Sensor_blockiert 0;
BA_ "GenSigSendType" SG_ 1624 LV_FLA_Sensor_blockiert 0;
BA_ "GenSigSwitchedByIgnition" SG_ 1624 LV_Blinker_re_def 0;
BA_ "GenSigSendType" SG_ 1624 LV_Blinker_re_def 3;
BA_ "GenSigSwitchedByIgnition" SG_ 1624 LV_Standlicht_re_def 0;
BA_ "GenSigSendType" SG_ 1624 LV_Standlicht_re_def 0;
BA_ "GenSigSwitchedByIgnition" SG_ 1624 LV_Abblendlicht_re_def 0;
BA_ "GenSigSendType" SG_ 1624 LV_Abblendlicht_re_def 0;
BA_ "GenSigSwitchedByIgnition" SG_ 1624 LV_Fernlicht_re_def 0;
BA_ "GenSigSendType" SG_ 1624 LV_Fernlicht_re_def 0;
BA_ "GenSigSwitchedByIgnition" SG_ 1624 LV_Nebellicht_re_def 0;
BA_ "GenSigSendType" SG_ 1624 LV_Nebellicht_re_def 0;
BA_ "GenSigSwitchedByIgnition" SG_ 1624 LV_Blk_re_Seite_def 0;
BA_ "GenSigSendType" SG_ 1624 LV_Blk_re_Seite_def 0;
BA_ "GenSigSwitchedByIgnition" SG_ 1624 LV_Tagfahrlicht_re_def 0;
BA_ "GenSigSendType" SG_ 1624 LV_Tagfahrlicht_re_def 0;
BA_ "GenSigSwitchedByIgnition" SG_ 1624 LV_Aussenlicht_def 0;
BA_ "GenSigSendType" SG_ 1624 LV_Aussenlicht_def 3;
BA_ "GenSigSwitchedByIgnition" SG_ 1624 LV_Abblendlicht_TFL_li_def 0;
BA_ "GenSigSendType" SG_ 1624 LV_Abblendlicht_TFL_li_def 0;
BA_ "GenSigSwitchedByIgnition" SG_ 1624 LV_Nebellicht_TFL_li_def 0;
BA_ "GenSigSendType" SG_ 1624 LV_Nebellicht_TFL_li_def 0;
BA_ "GenSigSwitchedByIgnition" SG_ 1624 LV_Standlicht_TFL_li_def 0;
BA_ "GenSigSendType" SG_ 1624 LV_Standlicht_TFL_li_def 0;
BA_ "GenSigSwitchedByIgnition" SG_ 1624 LV_Abblend_Fernlicht_li_def 0;
BA_ "GenSigSendType" SG_ 1624 LV_Abblend_Fernlicht_li_def 0;
BA_ "GenSigSwitchedByIgnition" SG_ 1624 LV_Abblendlicht_TFL_re_def 0;
BA_ "GenSigSendType" SG_ 1624 LV_Abblendlicht_TFL_re_def 0;
BA_ "GenSigSwitchedByIgnition" SG_ 1624 LV_Nebellicht_TFL_re_def 0;
BA_ "GenSigSendType" SG_ 1624 LV_Nebellicht_TFL_re_def 0;
BA_ "GenSigSwitchedByIgnition" SG_ 1624 LV_Standlicht_TFL_re_def 0;
BA_ "GenSigSendType" SG_ 1624 LV_Standlicht_TFL_re_def 0;
BA_ "GenSigSwitchedByIgnition" SG_ 1624 LV_Abblend_Fernlicht_re_def 0;
BA_ "GenSigSendType" SG_ 1624 LV_Abblend_Fernlicht_re_def 0;
BA_ "GenSigSwitchedByIgnition" SG_ 1624 LV_Abbiegelicht_li_def 0;
BA_ "GenSigSendType" SG_ 1624 LV_Abbiegelicht_li_def 0;
BA_ "GenSigSwitchedByIgnition" SG_ 1624 LV_Abbiegelicht_re_def 0;
BA_ "GenSigSendType" SG_ 1624 LV_Abbiegelicht_re_def 0;
BA_ "GenSigSwitchedByIgnition" SG_ 1624 BCM1_Linksverkehr 0;
BA_ "GenSigSendType" SG_ 1624 BCM1_Linksverkehr 0;
BA_ "GenSigSwitchedByIgnition" SG_ 1624 BCM1_Licht_Dunkelheit_aktiv 0;
BA_ "GenSigSendType" SG_ 1624 BCM1_Licht_Dunkelheit_aktiv 3;
BA_ "GenSigSwitchedByIgnition" SG_ 1624 LV_LED_Scheinwerfer_li_def 0;
BA_ "GenSigSendType" SG_ 1624 LV_LED_Scheinwerfer_li_def 0;
BA_ "GenSigSwitchedByIgnition" SG_ 1624 LV_LED_Scheinwerfer_re_def 0;
BA_ "GenSigSendType" SG_ 1624 LV_LED_Scheinwerfer_re_def 0;
BA_ "GenSigSwitchedByIgnition" SG_ 1624 LV_Blinker_VL_aktiv 0;
BA_ "GenSigSendType" SG_ 1624 LV_Blinker_VL_aktiv 3;
BA_ "GenSigSwitchedByIgnition" SG_ 1624 LV_Blinker_VR_aktiv 0;
BA_ "GenSigSendType" SG_ 1624 LV_Blinker_VR_aktiv 3;
BA_ "GenSigSendType" SG_ 917 AFS_Abbiegelicht_li_Anf 0;
BA_ "GenSigSendType" SG_ 917 AFS_Abbiegelicht_re_Anf 0;
BA_ "GenSigSendType" SG_ 917 AFS_Abbiegelicht_Dimm_Anf 0;
BA_ "GenSigStartValue" SG_ 917 AFS_Verfuegbarkeit_GLW 1;
BA_ "GenSigSendType" SG_ 917 AFS_Verfuegbarkeit_GLW 0;
BA_ "GenSigStartValue" SG_ 917 AFS_Status_adaptive_LV 1;
BA_ "GenSigSendType" SG_ 917 AFS_Status_adaptive_LV 0;
BA_ "GenSigSendType" SG_ 917 AFS_Fernlicht_li_defekt 0;
BA_ "GenSigSendType" SG_ 917 AFS_Fernlicht_re_defekt 0;
BA_ "GenSigSendType" SG_ 917 AFS_Fernlicht_Status 3;
BA_ "GenSigFuncType" SG_ 917 LWR_AFS_01_BZ 1;
BA_ "GenSigSendType" SG_ 917 LWR_AFS_01_BZ 0;
BA_ "GenSigSendType" SG_ 917 AFS_Lampe 0;
BA_ "GenSigSendType" SG_ 917 LWR_Lampe 0;
BA_ "GenSigSendType" SG_ 917 AFS_Fehlertext 0;
BA_ "GenSigSendType" SG_ 917 AFS_LED_Blinkmode 0;
BA_ "GenSigSendType" SG_ 917 LWR_Touristenmodus_aktiv 0;
BA_ "GenSigSendType" SG_ 917 AFS_Charisma_FahrPr 0;
BA_ "GenSigSendType" SG_ 917 AFS_Charisma_Status 0;
BA_ "GenSigSendType" SG_ 917 LWR_Sicherheitsposition_re 0;
BA_ "GenSigSendType" SG_ 917 AFS_Allwetterlicht 0;
BA_ "GenSigSendType" SG_ 917 LWR_Touristenmodus_verbaut 0;
BA_ "GenSigSendType" SG_ 917 AFS_adaptive_LV_verbaut 0;
BA_ "GenSigSendType" SG_ 917 LWR_Reisemodus_Texte 0;
BA_ "GenSigSendType" SG_ 917 GLW_Sensor_blockiert 0;
BA_ "GenSigSendType" SG_ 917 AFS_Charisma_Umschaltung 3;
BA_ "Fehlerwert" SG_ 917 LWR_Pos_Schrittmotor 255;
BA_ "GenSigStartValue" SG_ 917 LWR_Pos_Schrittmotor 254;
BA_ "GenSigSendType" SG_ 917 LWR_Pos_Schrittmotor 0;
BA_ "Fehlerwert" SG_ 917 LWR_Hoehenwert_VL 255;
BA_ "GenSigStartValue" SG_ 917 LWR_Hoehenwert_VL 254;
BA_ "GenSigSendType" SG_ 917 LWR_Hoehenwert_VL 0;
BA_ "Fehlerwert" SG_ 917 LWR_Hoehenwert_HL 255;
BA_ "GenSigStartValue" SG_ 917 LWR_Hoehenwert_HL 254;
BA_ "GenSigSendType" SG_ 917 LWR_Hoehenwert_HL 0;
BA_ "GenSigSendType" SG_ 917 AFS_Ersatzlicht_Links 0;
BA_ "GenSigSendType" SG_ 917 AFS_Ersatzlicht_Rechts 0;
BA_ "GenSigSendType" SG_ 917 LWR_AFS_Grundeinstellung 0;
BA_ "GenSigSendType" SG_ 917 LWR_AFS_Parametrisierung 0;
BA_ "GenSigSendType" SG_ 917 LWR_Initialisierungslauf 0;
BA_ "GenSigSendType" SG_ 917 LWR_Sicherheitsposition_li 0;
BA_ "GenSigSendType" SG_ 917 LWR_Modus 0;
BA_REL_ "GenSigTimeoutTime" BU_SG_REL_ Gateway SG_ 2549088300 MFG_Nachlauftyp 5000;
BA_REL_ "GenSigTimeoutTime" BU_SG_REL_ Gateway SG_ 2549088300 MFG_SNI 5000;
BA_REL_ "GenSigTimeoutTime" BU_SG_REL_ Gateway SG_ 2549088300 KN_MFG_BusKnockOutTimer 5000;
BA_REL_ "GenSigTimeoutTime" BU_SG_REL_ Gateway SG_ 2549088300 NM_MFG_Lokalaktiv 5000;
BA_REL_ "GenSigTimeoutTime" BU_SG_REL_ Gateway SG_ 2549088300 NM_MFG_Subsystemaktiv 5000;
BA_REL_ "GenSigTimeoutTime" BU_SG_REL_ Gateway SG_ 2549088300 MFG_KD_Fehler 2500;
BA_REL_ "GenSigTimeoutTime" BU_SG_REL_ Gateway SG_ 2549088388 SAD_Nachlauftyp 5000;
BA_REL_ "GenSigTimeoutTime" BU_SG_REL_ Gateway SG_ 2549088388 SAD_SNI 5000;
BA_REL_ "GenSigTimeoutTime" BU_SG_REL_ Gateway SG_ 2549088388 NM_SAD_Lokalaktiv 5000;
BA_REL_ "GenSigTimeoutTime" BU_SG_REL_ Gateway SG_ 2549088388 NM_SAD_Subsystemaktiv 5000;
BA_REL_ "GenSigTimeoutTime" BU_SG_REL_ Gateway SG_ 2549088388 SAD_KD_Fehler 2500;
BA_REL_ "GenSigTimeoutTime" BU_SG_REL_ Gateway SG_ 2549088416 SAD2_Nachlauftyp 5000;
BA_REL_ "GenSigTimeoutTime" BU_SG_REL_ Gateway SG_ 2549088416 SAD2_SNI 5000;
BA_REL_ "GenSigTimeoutTime" BU_SG_REL_ Gateway SG_ 2549088416 NM_SAD2_Lokalaktiv 5000;
BA_REL_ "GenSigTimeoutTime" BU_SG_REL_ Gateway SG_ 2549088416 SAD2_KD_Fehler 2500;
BA_REL_ "GenSigTimeoutTime" BU_SG_REL_ Gateway SG_ 2549088411 SBBR_Nachlauftyp 5000;
BA_REL_ "GenSigTimeoutTime" BU_SG_REL_ Gateway SG_ 2549088411 SBBR_SNI 5000;
BA_REL_ "GenSigTimeoutTime" BU_SG_REL_ Gateway SG_ 2549088411 NM_MSBBR_Lokalaktiv 5000;
BA_REL_ "GenSigTimeoutTime" BU_SG_REL_ Gateway SG_ 2549088411 NM_MSBBR_Subsystemaktiv 5000;
BA_REL_ "GenSigTimeoutTime" BU_SG_REL_ Gateway SG_ 2549088411 SBBR_KD_Fehler 2500;
BA_REL_ "GenSigTimeoutTime" BU_SG_REL_ Gateway SG_ 2549088392 Mem_BFSFo_Nachlauftyp 5000;
BA_REL_ "GenSigTimeoutTime" BU_SG_REL_ Gateway SG_ 2549088392 Mem_BFSFo_SNI 5000;
BA_REL_ "GenSigTimeoutTime" BU_SG_REL_ Gateway SG_ 2549088392 NM_Mem_BFSFo_Lokalaktiv 5000;
BA_REL_ "GenSigTimeoutTime" BU_SG_REL_ Gateway SG_ 2549088392 NM_Mem_BFSFo_Subsystemaktiv 5000;
BA_REL_ "GenSigTimeoutTime" BU_SG_REL_ Gateway SG_ 2549088392 Mem_BFSFo_KD_Fehler 2500;
BA_REL_ "GenSigTimeoutTime" BU_SG_REL_ Gateway SG_ 2549088391 Mem_FSFo_Nachlauftyp 5000;
BA_REL_ "GenSigTimeoutTime" BU_SG_REL_ Gateway SG_ 2549088391 Mem_FSFo_SNI 5000;
BA_REL_ "GenSigTimeoutTime" BU_SG_REL_ Gateway SG_ 2549088391 NM_Mem_FSFo_Lokalaktiv 5000;
BA_REL_ "GenSigTimeoutTime" BU_SG_REL_ Gateway SG_ 2549088391 NM_Mem_FSFo_Subsystemaktiv 5000;
BA_REL_ "GenSigTimeoutTime" BU_SG_REL_ Gateway SG_ 2549088391 Mem_FSFo_KD_Fehler 2500;
BA_REL_ "GenSigTimeoutTime" BU_SG_REL_ Gateway SG_ 2549088405 SitzMem_SR3_Nachlauftyp 5000;
BA_REL_ "GenSigTimeoutTime" BU_SG_REL_ Gateway SG_ 2549088405 SitzMem_SR3_SNI 5000;
BA_REL_ "GenSigTimeoutTime" BU_SG_REL_ Gateway SG_ 2549088405 NM_SitzMem_SR3_Lokalaktiv 5000;
BA_REL_ "GenSigTimeoutTime" BU_SG_REL_ Gateway SG_ 2549088405 SitzMem_SR3_KD_Fehler 2500;
BA_REL_ "GenSigTimeoutTime" BU_SG_REL_ Gateway SG_ 2549088333 Sitzmemo_BFS_Nachlauftyp 5000;
BA_REL_ "GenSigTimeoutTime" BU_SG_REL_ Gateway SG_ 2549088333 Sitzmemo_BFS_SNI 5000;
BA_REL_ "GenSigTimeoutTime" BU_SG_REL_ Gateway SG_ 2549088333 NM_Sitzmemo_BFS_Subsystemaktiv 5000;
BA_REL_ "GenSigTimeoutTime" BU_SG_REL_ Gateway SG_ 2549088333 NM_Sitzmemo_BFS_Lokalaktiv 5000;
BA_REL_ "GenSigTimeoutTime" BU_SG_REL_ Gateway SG_ 2549088333 Mem_BFS_KD_Fehler 2500;
BA_REL_ "GenSigTimeoutTime" BU_SG_REL_ Gateway SG_ 2549088332 Sitzmemo_FS_Nachlauftyp 5000;
BA_REL_ "GenSigTimeoutTime" BU_SG_REL_ Gateway SG_ 2549088332 Sitzmemo_FS_SNI 5000;
BA_REL_ "GenSigTimeoutTime" BU_SG_REL_ Gateway SG_ 2549088332 NM_Sitzmemo_FS_Lokalaktiv 5000;
BA_REL_ "GenSigTimeoutTime" BU_SG_REL_ Gateway SG_ 2549088332 NM_Sitzmemo_FS_Subsystemaktiv 5000;
BA_REL_ "GenSigTimeoutTime" BU_SG_REL_ Gateway SG_ 2549088332 Mem_FS_KD_Fehler 2500;
BA_REL_ "GenSigTimeoutTime" BU_SG_REL_ Gateway SG_ 2549088292 SpoilerSG_Nachlauftyp 5000;
BA_REL_ "GenSigTimeoutTime" BU_SG_REL_ Gateway SG_ 2549088292 SpoilerSG_SNI 5000;
BA_REL_ "GenSigTimeoutTime" BU_SG_REL_ Gateway SG_ 2549088292 KN_SpoilerSG_ECUKnockOut 5000;
BA_REL_ "GenSigTimeoutTime" BU_SG_REL_ Gateway SG_ 2549088292 KN_SpoilerSG_WakePrevention 5000;
BA_REL_ "GenSigTimeoutTime" BU_SG_REL_ Gateway SG_ 2549088292 SpoilerSG_KD_Fehler 2500;
BA_REL_ "GenSigTimeoutTime" BU_SG_REL_ Gateway SG_ 2549088299 STS_Nachlauftyp 5000;
BA_REL_ "GenSigTimeoutTime" BU_SG_REL_ Gateway SG_ 2549088299 STS_SNI 5000;
BA_REL_ "GenSigTimeoutTime" BU_SG_REL_ Gateway SG_ 2549088299 KN_VTS_BusKnockOutTimer 5000;
BA_REL_ "GenSigTimeoutTime" BU_SG_REL_ Gateway SG_ 2549088299 KN_VTS_ECUKnockOut 5000;
BA_REL_ "GenSigTimeoutTime" BU_SG_REL_ Gateway SG_ 2549088299 KN_VTS_WakePrevention 5000;
BA_REL_ "GenSigTimeoutTime" BU_SG_REL_ Gateway SG_ 2549088299 NM_STS_Lokalaktiv 5000;
BA_REL_ "GenSigTimeoutTime" BU_SG_REL_ Gateway SG_ 2549088299 NM_STS_Subsystemaktiv 5000;
BA_REL_ "GenSigTimeoutTime" BU_SG_REL_ Gateway SG_ 2549088299 STS_KD_Fehler 2500;
BA_REL_ "GenSigTimeoutTime" BU_SG_REL_ Gateway SG_ 2549088331 TSG_BFS_Nachlauftyp 5000;
BA_REL_ "GenSigTimeoutTime" BU_SG_REL_ Gateway SG_ 2549088331 TSG_BFS_SNI 5000;
BA_REL_ "GenSigTimeoutTime" BU_SG_REL_ Gateway SG_ 2549088331 KN_TSG_BFS_BusKnockOutTimer 5000;
BA_REL_ "GenSigTimeoutTime" BU_SG_REL_ Gateway SG_ 2549088331 KN_TSG_BFS_ECUKnockOut 5000;
BA_REL_ "GenSigTimeoutTime" BU_SG_REL_ Gateway SG_ 2549088331 KN_TSG_BFS_WakePrevention 5000;
BA_REL_ "GenSigTimeoutTime" BU_SG_REL_ Gateway SG_ 2549088331 NM_TSG_BFS_Lokalaktiv 5000;
BA_REL_ "GenSigTimeoutTime" BU_SG_REL_ Gateway SG_ 2549088331 NM_TSG_BFS_Subsystemaktiv 5000;
BA_REL_ "GenSigTimeoutTime" BU_SG_REL_ Gateway SG_ 2549088331 TSG_BFS_KD_Fehler 2500;
BA_REL_ "GenSigTimeoutTime" BU_SG_REL_ Gateway SG_ 2549088330 TSG_FS_Nachlauftyp 5000;
BA_REL_ "GenSigTimeoutTime" BU_SG_REL_ Gateway SG_ 2549088330 TSG_FS_SNI 5000;
BA_REL_ "GenSigTimeoutTime" BU_SG_REL_ Gateway SG_ 2549088330 KN_TSG_FS_BusKnockOutTimer 5000;
BA_REL_ "GenSigTimeoutTime" BU_SG_REL_ Gateway SG_ 2549088330 KN_TSG_FS_ECUKnockOut 5000;
BA_REL_ "GenSigTimeoutTime" BU_SG_REL_ Gateway SG_ 2549088330 KN_TSG_FS_WakePrevention 5000;
BA_REL_ "GenSigTimeoutTime" BU_SG_REL_ Gateway SG_ 2549088330 NM_TSG_FS_Lokalaktiv 5000;
BA_REL_ "GenSigTimeoutTime" BU_SG_REL_ Gateway SG_ 2549088330 NM_TSG_FS_Subsystemaktiv 5000;
BA_REL_ "GenSigTimeoutTime" BU_SG_REL_ Gateway SG_ 2549088330 TSG_FS_KD_Fehler 2500;
BA_REL_ "GenSigTimeoutTime" BU_SG_REL_ Gateway SG_ 2549088301 VSG_Nachlauftyp 5000;
BA_REL_ "GenSigTimeoutTime" BU_SG_REL_ Gateway SG_ 2549088301 VSG_SNI 5000;
BA_REL_ "GenSigTimeoutTime" BU_SG_REL_ Gateway SG_ 2549088301 KN_VSG_BusKnockOutTimer 5000;
BA_REL_ "GenSigTimeoutTime" BU_SG_REL_ Gateway SG_ 2549088301 NM_VSG_Lokalaktiv 5000;
BA_REL_ "GenSigTimeoutTime" BU_SG_REL_ Gateway SG_ 2549088301 VSG_KD_Fehler 2500;
BA_REL_ "GenSigTimeoutTime" BU_SG_REL_ BCM1 SG_ 779 KBI_ESP_Lampe 2000;
BA_REL_ "GenSigTimeoutTime" BU_SG_REL_ VTS SG_ 779 KBI_Tankwarnung 2000;
BA_REL_ "GenSigTimeoutTime" BU_SG_REL_ BCM1 SG_ 779 KBI_PLA_in_Anzeige 2000;
BA_REL_ "GenSigTimeoutTime" BU_SG_REL_ VTS SG_ 779 KBI_Einheit_Tacho 2000;
BA_REL_ "GenSigTimeoutTime" BU_SG_REL_ BCM1 SG_ 1719 KBI_Standzeit_02 5000;
BA_REL_ "GenSigTimeoutTime" BU_SG_REL_ VTS SG_ 1719 KBI_Inhalt_Tank 5000;
BA_REL_ "GenSigTimeoutTime" BU_SG_REL_ BCM1 SG_ 1719 KBI_QBit_Aussen_Temp_gef 5000;
BA_REL_ "GenSigTimeoutTime" BU_SG_REL_ BCM2 SG_ 1719 KBI_QBit_Aussen_Temp_gef 5000;
BA_REL_ "GenSigTimeoutTime" BU_SG_REL_ SpoilerSG SG_ 1719 KBI_QBit_Aussen_Temp_gef 5000;
BA_REL_ "GenSigTimeoutTime" BU_SG_REL_ BCM1 SG_ 1719 KBI_Aussen_Temp_gef 5000;
BA_REL_ "GenSigTimeoutTime" BU_SG_REL_ BCM2 SG_ 1719 KBI_Aussen_Temp_gef 5000;
BA_REL_ "GenSigTimeoutTime" BU_SG_REL_ HDSG SG_ 1719 KBI_Aussen_Temp_gef 5000;
BA_REL_ "GenSigTimeoutTime" BU_SG_REL_ SAD SG_ 1719 KBI_Aussen_Temp_gef 5000;
BA_REL_ "GenSigTimeoutTime" BU_SG_REL_ SpoilerSG SG_ 1719 KBI_Aussen_Temp_gef 5000;
BA_REL_ "GenSigTimeoutTime" BU_SG_REL_ TSG_BFS SG_ 1719 KBI_Aussen_Temp_gef 5000;
BA_REL_ "GenSigTimeoutTime" BU_SG_REL_ TSG_FS SG_ 1719 KBI_Aussen_Temp_gef 5000;
BA_REL_ "GenSigTimeoutTime" BU_SG_REL_ VSG SG_ 1719 KBI_Aussen_Temp_gef 5000;
BA_REL_ "GenSigTimeoutTime" BU_SG_REL_ VTS SG_ 1719 KBI_Aussen_Temp_gef 5000;
BA_REL_ "GenSigTimeoutTime" BU_SG_REL_ BCM2 SG_ 1720 KBI_Reifenumfang 5000;
BA_REL_ "GenSigTimeoutTime" BU_SG_REL_ VTS SG_ 1720 KBI_Tankfuellstand_Prozent 5000;
BA_REL_ "GenSigTimeoutTime" BU_SG_REL_ BCM2 SG_ 1724 KBI_Oil_dis_status 5000;
BA_REL_ "GenSigTimeoutTime" BU_SG_REL_ BCM2 SG_ 1724 KBI_Oil_dis_unit 5000;
BA_REL_ "GenSigTimeoutTime" BU_SG_REL_ BCM2 SG_ 1724 KBI_Oil_dis 5000;
BA_REL_ "GenSigTimeoutTime" BU_SG_REL_ BCM2 SG_ 1724 KBI_Oil_time_status 5000;
BA_REL_ "GenSigTimeoutTime" BU_SG_REL_ BCM2 SG_ 1724 KBI_Oil_time 5000;
BA_REL_ "GenSigTimeoutTime" BU_SG_REL_ BCM2 SG_ 1724 KBI_Insp_dis_status 5000;
BA_REL_ "GenSigTimeoutTime" BU_SG_REL_ BCM2 SG_ 1724 KBI_Insp_dis_unit 5000;
BA_REL_ "GenSigTimeoutTime" BU_SG_REL_ BCM2 SG_ 1724 KBI_Insp_dis 5000;
BA_REL_ "GenSigTimeoutTime" BU_SG_REL_ BCM2 SG_ 1724 KBI_Insp_time_status 5000;
BA_REL_ "GenSigTimeoutTime" BU_SG_REL_ BCM2 SG_ 1724 KBI_Insp_time 5000;
BA_REL_ "GenSigTimeoutTime" BU_SG_REL_ BCM2 SG_ 1724 KBI_Warnung_ID 5000;
BA_REL_ "GenSigTimeoutTime" BU_SG_REL_ BCM2 SG_ 2589283471 KBI_Signatur_Wegstrecke_01 5000;
BA_REL_ "GenSigTimeoutTime" BU_SG_REL_ BCM2 SG_ 2589283471 KBI_Wegstrecke 5000;
BA_REL_ "GenSigTimeoutTime" BU_SG_REL_ BCM2 SG_ 2589283471 KBI_Signatur_Wegstrecke_02 5000;
BA_REL_ "GenSigTimeoutTime" BU_SG_REL_ BCM1 SG_ 919 HC_Uss_Anforderung 800;
BA_REL_ "GenSigTimeoutTime" BU_SG_REL_ BCM1 SG_ 810 EPS_01_CRC 500;
BA_REL_ "GenSigTimeoutTime" BU_SG_REL_ BCM1 SG_ 810 EPS_01_BZ 500;
BA_REL_ "GenSigTimeoutTime" BU_SG_REL_ BCM1 SG_ 810 EPS_PWR_Abbruch 500;
BA_REL_ "GenSigTimeoutTime" BU_SG_REL_ BCM1 SG_ 810 EPS_PWR_Fehler 500;
BA_REL_ "GenSigTimeoutTime" BU_SG_REL_ BCM1 SG_ 810 EPS_PLA_Status 500;
BA_REL_ "GenSigTimeoutTime" BU_SG_REL_ BCM1 SG_ 810 EPS_ARA_Status 500;
BA_REL_ "GenSigTimeoutTime" BU_SG_REL_ BCM1 SG_ 160 EPS_04_CRC 500;
BA_REL_ "GenSigTimeoutTime" BU_SG_REL_ BCM1 SG_ 160 EPS_04_BZ 500;
BA_REL_ "GenSigTimeoutTime" BU_SG_REL_ BCM1 SG_ 160 EPS_Lenkmoment_AbsReduz 500;
BA_REL_ "GenSigTimeoutTime" BU_SG_REL_ BCM1 SG_ 160 EPS_Zahnstangen_Pos 500;
BA_REL_ "GenSigTimeoutTime" BU_SG_REL_ BCM1 SG_ 160 EPS_VZ_Zahnstangenposition 500;
BA_REL_ "GenSigTimeoutTime" BU_SG_REL_ BCM1 SG_ 160 EPS_QBit_Zahnstangen_Pos 500;
BA_REL_ "GenSigTimeoutTime" BU_SG_REL_ AAG SG_ 981 Licht_Anf_01_CRC 1000;
BA_REL_ "GenSigTimeoutTime" BU_SG_REL_ BCM2 SG_ 981 Licht_Anf_01_CRC 1000;
BA_REL_ "GenSigTimeoutTime" BU_SG_REL_ MSBBR SG_ 981 Licht_Anf_01_CRC 1000;
BA_REL_ "GenSigTimeoutTime" BU_SG_REL_ AAG SG_ 981 Licht_Anf_01_BZ 1000;
BA_REL_ "GenSigTimeoutTime" BU_SG_REL_ BCM2 SG_ 981 Licht_Anf_01_BZ 1000;
BA_REL_ "GenSigTimeoutTime" BU_SG_REL_ Gateway SG_ 981 BCM1_Standlicht_Anf 1000;
BA_REL_ "GenSigTimeoutTime" BU_SG_REL_ MFG SG_ 981 BCM1_Standlicht_Anf 1000;
BA_REL_ "GenSigTimeoutTime" BU_SG_REL_ MSBBR SG_ 981 BCM1_Standlicht_Anf 1000;
BA_REL_ "GenSigTimeoutTime" BU_SG_REL_ Gateway SG_ 981 BCM1_Abblendlicht_Anf 1000;
BA_REL_ "GenSigTimeoutTime" BU_SG_REL_ MFG SG_ 981 BCM1_Abblendlicht_Anf 1000;
BA_REL_ "GenSigTimeoutTime" BU_SG_REL_ Gateway SG_ 981 BCM1_Fernlicht_Anf 1000;
BA_REL_ "GenSigTimeoutTime" BU_SG_REL_ MFG SG_ 981 BCM1_Fernlicht_Anf 1000;
BA_REL_ "GenSigTimeoutTime" BU_SG_REL_ Gateway SG_ 981 BCM1_Nebellicht_Anf 1000;
BA_REL_ "GenSigTimeoutTime" BU_SG_REL_ MFG SG_ 981 BCM1_Nebellicht_Anf 1000;
BA_REL_ "GenSigTimeoutTime" BU_SG_REL_ AAG SG_ 981 BCM1_Parklicht_li_Anf 1000;
BA_REL_ "GenSigTimeoutTime" BU_SG_REL_ BCM2 SG_ 981 BCM1_Parklicht_li_Anf 1000;
BA_REL_ "GenSigTimeoutTime" BU_SG_REL_ Gateway SG_ 981 BCM1_Parklicht_li_Anf 1000;
BA_REL_ "GenSigTimeoutTime" BU_SG_REL_ MSBBR SG_ 981 BCM1_Parklicht_li_Anf 1000;
BA_REL_ "GenSigTimeoutTime" BU_SG_REL_ AAG SG_ 981 BCM1_Parklicht_re_Anf 1000;
BA_REL_ "GenSigTimeoutTime" BU_SG_REL_ BCM2 SG_ 981 BCM1_Parklicht_re_Anf 1000;
BA_REL_ "GenSigTimeoutTime" BU_SG_REL_ Gateway SG_ 981 BCM1_Parklicht_re_Anf 1000;
BA_REL_ "GenSigTimeoutTime" BU_SG_REL_ MSBBR SG_ 981 BCM1_Parklicht_re_Anf 1000;
BA_REL_ "GenSigTimeoutTime" BU_SG_REL_ AAG SG_ 981 BCM1_Nebelschluss_Ahg_Anf 1000;
BA_REL_ "GenSigTimeoutTime" BU_SG_REL_ MFG SG_ 981 BCM1_Nebelschluss_Ahg_Anf 1000;
BA_REL_ "GenSigTimeoutTime" BU_SG_REL_ BCM2 SG_ 981 BCM1_Nebelschluss_Fzg_Anf 1000;
BA_REL_ "GenSigTimeoutTime" BU_SG_REL_ MFG SG_ 981 BCM1_Nebelschluss_Fzg_Anf 1000;
BA_REL_ "GenSigTimeoutTime" BU_SG_REL_ MSBBR SG_ 981 BCM1_Nebelschluss_Fzg_Anf 1000;
BA_REL_ "GenSigTimeoutTime" BU_SG_REL_ AAG SG_ 981 BCM1_Schlusslicht_Anf 1000;
BA_REL_ "GenSigTimeoutTime" BU_SG_REL_ BCM2 SG_ 981 BCM1_Schlusslicht_Anf 1000;
BA_REL_ "GenSigTimeoutTime" BU_SG_REL_ Gateway SG_ 981 BCM1_Schlusslicht_Anf 1000;
BA_REL_ "GenSigTimeoutTime" BU_SG_REL_ MFG SG_ 981 BCM1_Schlusslicht_Anf 1000;
BA_REL_ "GenSigTimeoutTime" BU_SG_REL_ MSBBR SG_ 981 BCM1_Schlusslicht_Anf 1000;
BA_REL_ "GenSigTimeoutTime" BU_SG_REL_ AAG SG_ 981 BCM_Rueckfahrlicht_Anf 1000;
BA_REL_ "GenSigTimeoutTime" BU_SG_REL_ BCM2 SG_ 981 BCM_Rueckfahrlicht_Anf 1000;
BA_REL_ "GenSigTimeoutTime" BU_SG_REL_ Gateway SG_ 981 BCM_Rueckfahrlicht_Anf 1000;
BA_REL_ "GenSigTimeoutTime" BU_SG_REL_ MFG SG_ 981 BCM_Rueckfahrlicht_Anf 1000;
BA_REL_ "GenSigTimeoutTime" BU_SG_REL_ MSBBR SG_ 981 BCM_Rueckfahrlicht_Anf 1000;
BA_REL_ "GenSigTimeoutTime" BU_SG_REL_ TSG_BFS SG_ 981 BCM_Rueckfahrlicht_Anf 1000;
BA_REL_ "GenSigTimeoutTime" BU_SG_REL_ TSG_FS SG_ 981 BCM_Rueckfahrlicht_Anf 1000;
BA_REL_ "GenSigTimeoutTime" BU_SG_REL_ TSG_BFS SG_ 981 BCM1_Umfeldleuchten_Anf 1000;
BA_REL_ "GenSigTimeoutTime" BU_SG_REL_ TSG_FS SG_ 981 BCM1_Umfeldleuchten_Anf 1000;
BA_REL_ "GenSigTimeoutTime" BU_SG_REL_ MFG SG_ 981 BCM1_Tagfahrlicht_Anf 1000;
BA_REL_ "GenSigTimeoutTime" BU_SG_REL_ MFG SG_ 981 BCM1_Regenlicht_Anf 1000;
BA_REL_ "GenSigTimeoutTime" BU_SG_REL_ MSBBR SG_ 981 BCM1_Regenlicht_Anf 1000;
BA_REL_ "GenSigTimeoutTime" BU_SG_REL_ MFG SG_ 981 BCM1_Autobahnlicht_Anf 1000;
BA_REL_ "GenSigTimeoutTime" BU_SG_REL_ MSBBR SG_ 981 BCM1_Touristen_Licht_Anf 1000;
BA_REL_ "GenSigTimeoutTime" BU_SG_REL_ Gateway SG_ 981 BCM1_CH_LH_aktiv 1000;
BA_REL_ "GenSigTimeoutTime" BU_SG_REL_ MSBBR SG_ 981 BCM1_CH_LH_aktiv 1000;
BA_REL_ "GenSigTimeoutTime" BU_SG_REL_ MSBBR SG_ 981 BCM1_Allwetterlicht_Anf 1000;
BA_REL_ "GenSigTimeoutTime" BU_SG_REL_ Gateway SG_ 982 LH_Aussenlicht_def 1000;
BA_REL_ "GenSigTimeoutTime" BU_SG_REL_ VTS SG_ 982 LH_Aussenlicht_def 1000;
BA_REL_ "GenSigTimeoutTime" BU_SG_REL_ Gateway SG_ 982 LH_Standlicht_H_aktiv 1000;
BA_REL_ "GenSigTimeoutTime" BU_SG_REL_ Gateway SG_ 982 LH_Parklicht_HL_aktiv 1000;
BA_REL_ "GenSigTimeoutTime" BU_SG_REL_ Gateway SG_ 982 LH_Parklicht_HR_aktiv 1000;
BA_REL_ "GenSigTimeoutTime" BU_SG_REL_ BCM1 SG_ 982 LH_Nebelschluss_aktiv 1000;
BA_REL_ "GenSigTimeoutTime" BU_SG_REL_ Gateway SG_ 982 LH_Nebelschluss_aktiv 1000;
BA_REL_ "GenSigTimeoutTime" BU_SG_REL_ Gateway SG_ 982 LH_Rueckfahrlicht_aktiv 1000;
BA_REL_ "GenSigTimeoutTime" BU_SG_REL_ SitzMem_FS SG_ 982 LH_Rueckfahrlicht_aktiv 1000;
BA_REL_ "GenSigTimeoutTime" BU_SG_REL_ TSG_BFS SG_ 982 LH_Rueckfahrlicht_aktiv 1000;
BA_REL_ "GenSigTimeoutTime" BU_SG_REL_ TSG_FS SG_ 982 LH_Rueckfahrlicht_aktiv 1000;
BA_REL_ "GenSigTimeoutTime" BU_SG_REL_ Gateway SG_ 982 LH_Blinker_HL_akt 1000;
BA_REL_ "GenSigTimeoutTime" BU_SG_REL_ Gateway SG_ 982 LH_Blinker_HR_akt 1000;
BA_REL_ "GenSigTimeoutTime" BU_SG_REL_ Gateway SG_ 982 LH_Blinker_li_def 1000;
BA_REL_ "GenSigTimeoutTime" BU_SG_REL_ VTS SG_ 982 LH_Blinker_li_def 1000;
BA_REL_ "GenSigTimeoutTime" BU_SG_REL_ Gateway SG_ 982 LH_Bremsl_li_def 1000;
BA_REL_ "GenSigTimeoutTime" BU_SG_REL_ VTS SG_ 982 LH_Bremsl_li_def 1000;
BA_REL_ "GenSigTimeoutTime" BU_SG_REL_ Gateway SG_ 982 LH_Schlusslicht_li_def 1000;
BA_REL_ "GenSigTimeoutTime" BU_SG_REL_ VTS SG_ 982 LH_Schlusslicht_li_def 1000;
BA_REL_ "GenSigTimeoutTime" BU_SG_REL_ Gateway SG_ 982 LH_Rueckf_li_def 1000;
BA_REL_ "GenSigTimeoutTime" BU_SG_REL_ VTS SG_ 982 LH_Rueckf_li_def 1000;
BA_REL_ "GenSigTimeoutTime" BU_SG_REL_ Gateway SG_ 982 LH_Nebel_li_def 1000;
BA_REL_ "GenSigTimeoutTime" BU_SG_REL_ VTS SG_ 982 LH_Nebel_li_def 1000;
BA_REL_ "GenSigTimeoutTime" BU_SG_REL_ Gateway SG_ 982 LH_Schluss_Brems_Nebel_li_def 1000;
BA_REL_ "GenSigTimeoutTime" BU_SG_REL_ VTS SG_ 982 LH_Schluss_Brems_Nebel_li_def 1000;
BA_REL_ "GenSigTimeoutTime" BU_SG_REL_ Gateway SG_ 982 LH_Schluss_Brems_Nebel_re_def 1000;
BA_REL_ "GenSigTimeoutTime" BU_SG_REL_ VTS SG_ 982 LH_Schluss_Brems_Nebel_re_def 1000;
BA_REL_ "GenSigTimeoutTime" BU_SG_REL_ Gateway SG_ 982 LH_Schluss_Brems_li_def 1000;
BA_REL_ "GenSigTimeoutTime" BU_SG_REL_ VTS SG_ 982 LH_Schluss_Brems_li_def 1000;
BA_REL_ "GenSigTimeoutTime" BU_SG_REL_ Gateway SG_ 982 LH_Schluss_Nebel_li_def 1000;
BA_REL_ "GenSigTimeoutTime" BU_SG_REL_ VTS SG_ 982 LH_Schluss_Nebel_li_def 1000;
BA_REL_ "GenSigTimeoutTime" BU_SG_REL_ Gateway SG_ 982 LH_SL_BRL_BLK_li_def 1000;
BA_REL_ "GenSigTimeoutTime" BU_SG_REL_ Gateway SG_ 982 LH_Brems_Blk_li_def 1000;
BA_REL_ "GenSigTimeoutTime" BU_SG_REL_ VTS SG_ 982 LH_Brems_Blk_li_def 1000;
BA_REL_ "GenSigTimeoutTime" BU_SG_REL_ Gateway SG_ 982 LH_Blinker_re_def 1000;
BA_REL_ "GenSigTimeoutTime" BU_SG_REL_ VTS SG_ 982 LH_Blinker_re_def 1000;
BA_REL_ "GenSigTimeoutTime" BU_SG_REL_ Gateway SG_ 982 LH_Bremsl_re_def 1000;
BA_REL_ "GenSigTimeoutTime" BU_SG_REL_ VTS SG_ 982 LH_Bremsl_re_def 1000;
BA_REL_ "GenSigTimeoutTime" BU_SG_REL_ Gateway SG_ 982 LH_Schlusslicht_re_def 1000;
BA_REL_ "GenSigTimeoutTime" BU_SG_REL_ VTS SG_ 982 LH_Schlusslicht_re_def 1000;
BA_REL_ "GenSigTimeoutTime" BU_SG_REL_ Gateway SG_ 982 LH_Rueckf_re_def 1000;
BA_REL_ "GenSigTimeoutTime" BU_SG_REL_ VTS SG_ 982 LH_Rueckf_re_def 1000;
BA_REL_ "GenSigTimeoutTime" BU_SG_REL_ Gateway SG_ 982 LH_Nebel_re_def 1000;
BA_REL_ "GenSigTimeoutTime" BU_SG_REL_ VTS SG_ 982 LH_Nebel_re_def 1000;
BA_REL_ "GenSigTimeoutTime" BU_SG_REL_ Gateway SG_ 982 LH_Schluss_Brems_re_def 1000;
BA_REL_ "GenSigTimeoutTime" BU_SG_REL_ VTS SG_ 982 LH_Schluss_Brems_re_def 1000;
BA_REL_ "GenSigTimeoutTime" BU_SG_REL_ Gateway SG_ 982 LH_Schluss_Nebel_re_def 1000;
BA_REL_ "GenSigTimeoutTime" BU_SG_REL_ VTS SG_ 982 LH_Schluss_Nebel_re_def 1000;
BA_REL_ "GenSigTimeoutTime" BU_SG_REL_ Gateway SG_ 982 LH_SL_BRL_BLK_re_def 1000;
BA_REL_ "GenSigTimeoutTime" BU_SG_REL_ VTS SG_ 982 LH_SL_BRL_BLK_re_def 1000;
BA_REL_ "GenSigTimeoutTime" BU_SG_REL_ Gateway SG_ 982 LH_Brems_Blk_re_def 1000;
BA_REL_ "GenSigTimeoutTime" BU_SG_REL_ VTS SG_ 982 LH_Brems_Blk_re_def 1000;
BA_REL_ "GenSigTimeoutTime" BU_SG_REL_ Gateway SG_ 982 LH_Kennzl_def 1000;
BA_REL_ "GenSigTimeoutTime" BU_SG_REL_ VTS SG_ 982 LH_Kennzl_def 1000;
BA_REL_ "GenSigTimeoutTime" BU_SG_REL_ Gateway SG_ 982 LH_3_Bremsl_def 1000;
BA_REL_ "GenSigTimeoutTime" BU_SG_REL_ VTS SG_ 982 LH_3_Bremsl_def 1000;
BA_REL_ "GenSigTimeoutTime" BU_SG_REL_ Gateway SG_ 982 LH_Nebel_mi_def 1000;
BA_REL_ "GenSigTimeoutTime" BU_SG_REL_ VTS SG_ 982 LH_Nebel_mi_def 1000;
BA_REL_ "GenSigTimeoutTime" BU_SG_REL_ Gateway SG_ 982 LH_Rueckf_mi_def 1000;
BA_REL_ "GenSigTimeoutTime" BU_SG_REL_ VTS SG_ 982 LH_Rueckf_mi_def 1000;
BA_REL_ "GenSigTimeoutTime" BU_SG_REL_ Gateway SG_ 982 LH_Bremsl_li_ges_def 1000;
BA_REL_ "GenSigTimeoutTime" BU_SG_REL_ VTS SG_ 982 LH_Bremsl_li_ges_def 1000;
BA_REL_ "GenSigTimeoutTime" BU_SG_REL_ Gateway SG_ 982 LH_Bremsl_re_ges_def 1000;
BA_REL_ "GenSigTimeoutTime" BU_SG_REL_ VTS SG_ 982 LH_Bremsl_re_ges_def 1000;
BA_REL_ "GenSigTimeoutTime" BU_SG_REL_ BCM2 SG_ 1624 Licht_Vorne_01_CRC 5000;
BA_REL_ "GenSigTimeoutTime" BU_SG_REL_ BCM2 SG_ 1624 Licht_Vorne_01_BZ 5000;
BA_REL_ "GenSigTimeoutTime" BU_SG_REL_ Gateway SG_ 1624 LV_Standlicht_Anzeige 5000;
BA_REL_ "GenSigTimeoutTime" BU_SG_REL_ VTS SG_ 1624 LV_Standlicht_Anzeige 5000;
BA_REL_ "GenSigTimeoutTime" BU_SG_REL_ Gateway SG_ 1624 LV_Abblendlicht_Anzeige 5000;
BA_REL_ "GenSigTimeoutTime" BU_SG_REL_ VTS SG_ 1624 LV_Abblendlicht_Anzeige 5000;
BA_REL_ "GenSigTimeoutTime" BU_SG_REL_ Gateway SG_ 1624 LV_Fernlicht_Anzeige 5000;
BA_REL_ "GenSigTimeoutTime" BU_SG_REL_ VTS SG_ 1624 LV_Fernlicht_Anzeige 5000;
BA_REL_ "GenSigTimeoutTime" BU_SG_REL_ Gateway SG_ 1624 LV_Nebellicht_Anzeige 5000;
BA_REL_ "GenSigTimeoutTime" BU_SG_REL_ VTS SG_ 1624 LV_Nebellicht_Anzeige 5000;
BA_REL_ "GenSigTimeoutTime" BU_SG_REL_ Gateway SG_ 1624 LV_Nebelschlusslicht_Anzeige 5000;
BA_REL_ "GenSigTimeoutTime" BU_SG_REL_ Gateway SG_ 1624 LV_Tagfahrlicht_Anzeige 5000;
BA_REL_ "GenSigTimeoutTime" BU_SG_REL_ VTS SG_ 1624 LV_Tagfahrlicht_Anzeige 5000;
BA_REL_ "GenSigTimeoutTime" BU_SG_REL_ Gateway SG_ 1624 LV_AFL_aktiv_Anzeige 5000;
BA_REL_ "GenSigTimeoutTime" BU_SG_REL_ Gateway SG_ 1624 LV_AFL_defekt 5000;
BA_REL_ "GenSigTimeoutTime" BU_SG_REL_ VTS SG_ 1624 LV_AFL_defekt 5000;
BA_REL_ "GenSigTimeoutTime" BU_SG_REL_ BCM2 SG_ 1624 LV_Blinker_li_def 5000;
BA_REL_ "GenSigTimeoutTime" BU_SG_REL_ Gateway SG_ 1624 LV_Blinker_li_def 5000;
BA_REL_ "GenSigTimeoutTime" BU_SG_REL_ VTS SG_ 1624 LV_Blinker_li_def 5000;
BA_REL_ "GenSigTimeoutTime" BU_SG_REL_ Gateway SG_ 1624 LV_Standlicht_li_def 5000;
BA_REL_ "GenSigTimeoutTime" BU_SG_REL_ VTS SG_ 1624 LV_Standlicht_li_def 5000;
BA_REL_ "GenSigTimeoutTime" BU_SG_REL_ Gateway SG_ 1624 LV_Abblendlicht_li_def 5000;
BA_REL_ "GenSigTimeoutTime" BU_SG_REL_ Gateway SG_ 1624 LV_Fernlicht_li_def 5000;
BA_REL_ "GenSigTimeoutTime" BU_SG_REL_ VTS SG_ 1624 LV_Fernlicht_li_def 5000;
BA_REL_ "GenSigTimeoutTime" BU_SG_REL_ Gateway SG_ 1624 LV_Nebellicht_li_def 5000;
BA_REL_ "GenSigTimeoutTime" BU_SG_REL_ VTS SG_ 1624 LV_Nebellicht_li_def 5000;
BA_REL_ "GenSigTimeoutTime" BU_SG_REL_ Gateway SG_ 1624 LV_Blk_li_Seite_def 5000;
BA_REL_ "GenSigTimeoutTime" BU_SG_REL_ VTS SG_ 1624 LV_Blk_li_Seite_def 5000;
BA_REL_ "GenSigTimeoutTime" BU_SG_REL_ Gateway SG_ 1624 LV_Tagfahrlicht_li_def 5000;
BA_REL_ "GenSigTimeoutTime" BU_SG_REL_ VTS SG_ 1624 LV_Tagfahrlicht_li_def 5000;
BA_REL_ "GenSigTimeoutTime" BU_SG_REL_ VTS SG_ 1624 LV_FLA_defekt 5000;
BA_REL_ "GenSigTimeoutTime" BU_SG_REL_ BCM2 SG_ 1624 LV_Blinker_re_def 5000;
BA_REL_ "GenSigTimeoutTime" BU_SG_REL_ Gateway SG_ 1624 LV_Blinker_re_def 5000;
BA_REL_ "GenSigTimeoutTime" BU_SG_REL_ VTS SG_ 1624 LV_Blinker_re_def 5000;
BA_REL_ "GenSigTimeoutTime" BU_SG_REL_ Gateway SG_ 1624 LV_Standlicht_re_def 5000;
BA_REL_ "GenSigTimeoutTime" BU_SG_REL_ VTS SG_ 1624 LV_Standlicht_re_def 5000;
BA_REL_ "GenSigTimeoutTime" BU_SG_REL_ Gateway SG_ 1624 LV_Abblendlicht_re_def 5000;
BA_REL_ "GenSigTimeoutTime" BU_SG_REL_ VTS SG_ 1624 LV_Abblendlicht_re_def 5000;
BA_REL_ "GenSigTimeoutTime" BU_SG_REL_ Gateway SG_ 1624 LV_Fernlicht_re_def 5000;
BA_REL_ "GenSigTimeoutTime" BU_SG_REL_ VTS SG_ 1624 LV_Fernlicht_re_def 5000;
BA_REL_ "GenSigTimeoutTime" BU_SG_REL_ Gateway SG_ 1624 LV_Nebellicht_re_def 5000;
BA_REL_ "GenSigTimeoutTime" BU_SG_REL_ VTS SG_ 1624 LV_Nebellicht_re_def 5000;
BA_REL_ "GenSigTimeoutTime" BU_SG_REL_ Gateway SG_ 1624 LV_Blk_re_Seite_def 5000;
BA_REL_ "GenSigTimeoutTime" BU_SG_REL_ VTS SG_ 1624 LV_Blk_re_Seite_def 5000;
BA_REL_ "GenSigTimeoutTime" BU_SG_REL_ Gateway SG_ 1624 LV_Tagfahrlicht_re_def 5000;
BA_REL_ "GenSigTimeoutTime" BU_SG_REL_ VTS SG_ 1624 LV_Tagfahrlicht_re_def 5000;
BA_REL_ "GenSigTimeoutTime" BU_SG_REL_ Gateway SG_ 1624 LV_Aussenlicht_def 5000;
BA_REL_ "GenSigTimeoutTime" BU_SG_REL_ Gateway SG_ 1624 LV_Abblendlicht_TFL_li_def 5000;
BA_REL_ "GenSigTimeoutTime" BU_SG_REL_ VTS SG_ 1624 LV_Abblendlicht_TFL_li_def 5000;
BA_REL_ "GenSigTimeoutTime" BU_SG_REL_ Gateway SG_ 1624 LV_Nebellicht_TFL_li_def 5000;
BA_REL_ "GenSigTimeoutTime" BU_SG_REL_ VTS SG_ 1624 LV_Nebellicht_TFL_li_def 5000;
BA_REL_ "GenSigTimeoutTime" BU_SG_REL_ Gateway SG_ 1624 LV_Standlicht_TFL_li_def 5000;
BA_REL_ "GenSigTimeoutTime" BU_SG_REL_ VTS SG_ 1624 LV_Standlicht_TFL_li_def 5000;
BA_REL_ "GenSigTimeoutTime" BU_SG_REL_ Gateway SG_ 1624 LV_Abblend_Fernlicht_li_def 5000;
BA_REL_ "GenSigTimeoutTime" BU_SG_REL_ VTS SG_ 1624 LV_Abblend_Fernlicht_li_def 5000;
BA_REL_ "GenSigTimeoutTime" BU_SG_REL_ Gateway SG_ 1624 LV_Abblendlicht_TFL_re_def 5000;
BA_REL_ "GenSigTimeoutTime" BU_SG_REL_ VTS SG_ 1624 LV_Abblendlicht_TFL_re_def 5000;
BA_REL_ "GenSigTimeoutTime" BU_SG_REL_ Gateway SG_ 1624 LV_Nebellicht_TFL_re_def 5000;
BA_REL_ "GenSigTimeoutTime" BU_SG_REL_ VTS SG_ 1624 LV_Nebellicht_TFL_re_def 5000;
BA_REL_ "GenSigTimeoutTime" BU_SG_REL_ Gateway SG_ 1624 LV_Standlicht_TFL_re_def 5000;
BA_REL_ "GenSigTimeoutTime" BU_SG_REL_ VTS SG_ 1624 LV_Standlicht_TFL_re_def 5000;
BA_REL_ "GenSigTimeoutTime" BU_SG_REL_ Gateway SG_ 1624 LV_Abblend_Fernlicht_re_def 5000;
BA_REL_ "GenSigTimeoutTime" BU_SG_REL_ VTS SG_ 1624 LV_Abblend_Fernlicht_re_def 5000;
BA_REL_ "GenSigTimeoutTime" BU_SG_REL_ MFG SG_ 1624 BCM1_Licht_Dunkelheit_aktiv 5000;
BA_REL_ "GenSigTimeoutTime" BU_SG_REL_ BCM2 SG_ 1624 LV_Blinker_VL_aktiv 5000;
BA_REL_ "GenSigTimeoutTime" BU_SG_REL_ Gateway SG_ 1624 LV_Blinker_VL_aktiv 5000;
BA_REL_ "GenSigTimeoutTime" BU_SG_REL_ BCM2 SG_ 1624 LV_Blinker_VR_aktiv 5000;
BA_REL_ "GenSigTimeoutTime" BU_SG_REL_ Gateway SG_ 1624 LV_Blinker_VR_aktiv 5000;
BA_REL_ "GenSigTimeoutTime" BU_SG_REL_ Gateway SG_ 917 AFS_Charisma_FahrPr 1000;
BA_REL_ "GenSigTimeoutTime" BU_SG_REL_ Gateway SG_ 917 AFS_Charisma_Status 1000;
VAL_ 2549088300 MFG_KompSchutz 0 "inaktiv" 1 "aktiv" ;
VAL_ 2549088300 MFG_Abschaltstufe 0 "keine_Einschraenkung" 1 "Funktionseinschraenkung" ;
VAL_ 2549088300 MFG_Transport_Mode 0 "keine_Einschraenkung" 1 "Funktionseinschraenkung" ;
VAL_ 2549088300 MFG_Nachlauftyp 0 "Komm_bei_KL15_EIN" 1 "Komm_nach_KL15_AUS" 2 "Komm_bei_KL15_AUS" ;
VAL_ 2549088300 MFG_SNI 44 "" ;
VAL_ 2549088300 KN_MFG_BusKnockOutTimer 255 "BusKnockOut_deaktiviert" ;
VAL_ 2549088300 NM_MFG_Wakeup 0 "Peripherie_Wakeup__Ursache_nicht_bekannt" 1 "Bus_Wakeup" 2 "KL15_HW" 3 "E01__Taster_Pedalbetaetigung_BF" 4 "E02__Taster_Taxialarm_aktiv__Fussraumbeleuchtung" 5 "E03_res" 6 "E04__Taster_Innenbeleuchtung__Fensterheber_FT_tief" 7 "E05__Fensterheber_FT_hoch" 8 "E06__Taster_Tuerentriegelung_hinten__Tagfahrlichtabschaltung_Fensterheber_BFT_tief" 9 "E07__Fensterheber_BFT_hoch" 10 "E08_res" 11 "E09_res" 12 "E10__Anhaltesignalgeber_1" 13 "E11__Anhaltesignalgeber_2" 14 "E12__Anhaltesignalgeber_3" 15 "E13_res" 16 "E14_res" 17 "E15__Funkempfaenger_Taxialarm" 18 "E16__SoSi_Lichtschaltung_aktiviert" 19 "E17_res" 20 "E18_res" 128 "Taxi_Innenbeleuchtung_abschalten" 129 "SoSi_Bedienung" 130 "Fussraumbeleuchtung_abschalten" 131 "Bus_Schnittstelle" ;
VAL_ 2549088300 NM_MFG_Lokalaktiv 0 "war_nicht_lokal_aktiv" 1 "war_lokal_aktiv" ;
VAL_ 2549088300 NM_MFG_Subsystemaktiv 0 "Subsystem_war_nicht_lokalaktiv" 1 "war_lokalaktiv" ;
VAL_ 2549088300 MFG_KD_Fehler 0 "kein_KD_Fehler" 1 "KD_Fehler" ;
VAL_ 2549088388 SAD_KompSchutz 0 "inaktiv" 1 "aktiv" ;
VAL_ 2549088388 SAD_Abschaltstufe 0 "keine_Einschraenkung" 1 "Funktionseinschraenkung" ;
VAL_ 2549088388 SAD_Transport_Mode 0 "keine_Einschraenkung" 1 "Funktionseinschraenkung" ;
VAL_ 2549088388 SAD_Nachlauftyp 0 "Komm_bei_KL15_EIN" 1 "Komm_nach_KL15_AUS" 2 "Komm_bei_KL15_AUS" ;
VAL_ 2549088388 SAD_SNI 132 "" ;
VAL_ 2549088388 NM_SAD_Wakeup 0 "Peripherie_Wakeup__Ursache_nicht_bekannt" 1 "Bus_Wakeup" 2 "KL15_HW" 3 "Taster_Rollo__Taster_Schiebedach_betaetigt" ;
VAL_ 2549088388 NM_SAD_Lokalaktiv 0 "war_nicht_lokal_aktiv" 1 "war_lokal_aktiv" ;
VAL_ 2549088388 NM_SAD_Subsystemaktiv 0 "Subsystem_war_nicht_lokalaktiv" 1 "war_lokalaktiv" ;
VAL_ 2549088388 SAD_KD_Fehler 0 "kein_KD_Fehler" 1 "KD_Fehler" ;
VAL_ 2549088416 SAD2_KompSchutz 0 "inaktiv" 1 "aktiv" ;
VAL_ 2549088416 SAD2_Abschaltstufe 0 "keine_Einschraenkung" 1 "Funktionseinschraenkung" ;
VAL_ 2549088416 SAD2_Transport_Mode 0 "keine_Einschraenkung" 1 "Funktionseinschraenkung" ;
VAL_ 2549088416 SAD2_Nachlauftyp 0 "Komm_bei_KL15_EIN" 1 "Komm_nach_KL15_AUS" 2 "Komm_bei_KL15_AUS" ;
VAL_ 2549088416 SAD2_SNI 160 "Init" ;
VAL_ 2549088416 NM_SAD2_Wakeup 0 "Peripherie_Wakeup__Ursache_nicht_bekannt" 1 "Bus_Wakeup" 2 "KL15_HW" 3 "Taster_Rollo__Taster_Schiebedach_betaetigt" ;
VAL_ 2549088416 NM_SAD2_Lokalaktiv 0 "war_nicht_lokal_aktiv" 1 "war_lokal_aktiv" ;
VAL_ 2549088416 NM_SAD2_Subsystemaktiv 0 "Subsystem_war_nicht_lokalaktiv" 1 "war_lokalaktiv" ;
VAL_ 2549088416 SAD2_KD_Fehler 0 "kein_KD_Fehler" 1 "KD_Fehler" ;
VAL_ 2549088411 MSBBR_KompSchutz 0 "inaktiv" 1 "aktiv" ;
VAL_ 2549088411 MSBBR_Abschaltstufe 0 "keine_Einschraenkung" 1 "Funktionseinschraenkung" ;
VAL_ 2549088411 MSBBR_Transport_Mode 0 "keine_Einschraenkung" 1 "Funktionseinschraenkung" ;
VAL_ 2549088411 SBBR_Nachlauftyp 0 "Komm_bei_KL15_EIN" 1 "Komm_nach_KL15_AUS" 2 "Komm_bei_KL15_AUS" ;
VAL_ 2549088411 SBBR_SNI 155 "SNI" ;
VAL_ 2549088411 NM_MSBBR_Wakeup 0 "Peripherie_Wakeup__Ursache_nicht_bekannt" 1 "Bus_Wakeup" 2 "KL15_HW" ;
VAL_ 2549088411 NM_MSBBR_Lokalaktiv 0 "war_nicht_lokal_aktiv" 1 "war_lokal_aktiv" ;
VAL_ 2549088411 NM_MSBBR_Subsystemaktiv 0 "Subsystem_war_nicht_lokalaktiv" 1 "war_lokalaktiv" ;
VAL_ 2549088411 SBBR_KD_Fehler 0 "kein_KD_Fehler" 1 "KD_Fehler" ;
VAL_ 2549088392 Mem_BFSFo_KompSchutz 0 "inaktiv" 1 "aktiv" ;
VAL_ 2549088392 Mem_BFSFo_Abschaltstufe 0 "keine_Einschraenkung" 1 "Funktionseinschraenkung" ;
VAL_ 2549088392 Mem_BFSFo_Transport_Mode 0 "keine_Einschraenkung" 1 "Funktionseinschraenkung" ;
VAL_ 2549088392 Mem_BFSFo_Nachlauftyp 0 "Komm_bei_KL15_EIN" 1 "Komm_nach_KL15_AUS" 2 "Komm_bei_KL15_AUS" ;
VAL_ 2549088392 Mem_BFSFo_SNI 136 "" ;
VAL_ 2549088392 NM_Mem_BFSFo_Wakeup 0 "Peripherie_Wakeup__Ursache_nicht_bekannt" 1 "Bus_Wakeup" 2 "KL15_HW" 3 "Sitzhandverstellschalter" 4 "Beifahrersitzverstellung_vorne" ;
VAL_ 2549088392 NM_Mem_BFSFo_Lokalaktiv 0 "war_nicht_lokal_aktiv" 1 "war_lokal_aktiv" ;
VAL_ 2549088392 NM_Mem_BFSFo_Subsystemaktiv 0 "Subsystem_war_nicht_lokalaktiv" 1 "war_lokalaktiv" ;
VAL_ 2549088392 Mem_BFSFo_KD_Fehler 0 "kein_KD_Fehler" 1 "KD_Fehler" ;
VAL_ 2549088391 Mem_FSFo_KompSchutz 0 "inaktiv" 1 "aktiv" ;
VAL_ 2549088391 Mem_FSFo_Abschaltstufe 0 "keine_Einschraenkung" 1 "Funktionseinschraenkung" ;
VAL_ 2549088391 Mem_FSFo_Transport_Mode 0 "keine_Einschraenkung" 1 "Funktionseinschraenkung" ;
VAL_ 2549088391 Mem_FSFo_Nachlauftyp 0 "Komm_bei_KL15_EIN" 1 "Komm_nach_KL15_AUS" 2 "Komm_bei_KL15_AUS" ;
VAL_ 2549088391 Mem_FSFo_SNI 135 "" ;
VAL_ 2549088391 NM_Mem_FSFo_Wakeup 0 "Peripherie_Wakeup__Ursache_nicht_bekannt" 1 "Bus_Wakeup" 2 "KL15_HW" 3 "Sitzhandverstellschalter" ;
VAL_ 2549088391 NM_Mem_FSFo_Lokalaktiv 0 "war_nicht_lokal_aktiv" 1 "war_lokal_aktiv" ;
VAL_ 2549088391 NM_Mem_FSFo_Subsystemaktiv 0 "Subsystem_war_nicht_lokalaktiv" 1 "war_lokalaktiv" ;
VAL_ 2549088391 Mem_FSFo_KD_Fehler 0 "kein_KD_Fehler" 1 "KD_Fehler" ;
VAL_ 2549088405 SitzMem_SR3_KompSchutz 0 "inaktiv" 1 "aktiv" ;
VAL_ 2549088405 SitzMem_SR3_Abschaltstufe 0 "keine_Einschraenkung" 1 "Funktionseinschraenkung" ;
VAL_ 2549088405 SitzMem_SR3_Transport_Mode 0 "keine_Einschraenkung" 1 "Funktionseinschraenkung" ;
VAL_ 2549088405 SitzMem_SR3_Nachlauftyp 0 "Komm_bei_KL15_EIN" 1 "Komm_nach_KL15_AUS" 2 "Komm_bei_KL15_AUS" ;
VAL_ 2549088405 SitzMem_SR3_SNI 149 "" ;
VAL_ 2549088405 NM_SitzMem_SR3_Wakeup 0 "Peripherie_Wakeup__Ursache_nicht_bekannt" 1 "Bus_Wakeup" 2 "KL15_HW" 3 "Sitzhandverstellung" ;
VAL_ 2549088405 NM_SitzMem_SR3_Lokalaktiv 0 "war_nicht_lokal_aktiv" 1 "war_lokal_aktiv" ;
VAL_ 2549088405 NM_SitzMem_SR3_Subsystemaktiv 0 "Subsystem_war_nicht_lokalaktiv" 1 "war_lokalaktiv" ;
VAL_ 2549088405 SitzMem_SR3_KD_Fehler 0 "kein_KD_Fehler" 1 "KD_Fehler" ;
VAL_ 2549088333 Sitzmemo_BFS_KompSchutz 0 "inaktiv" 1 "aktiv" ;
VAL_ 2549088333 Sitzmemo_BFS_Abschaltstufe 0 "keine_Einschraenkung" 1 "Funktionseinschraenkung" ;
VAL_ 2549088333 Sitzmemo_BFS_Transport_Mode 0 "keine_Einschraenkung" 1 "Funktionseinschraenkung" ;
VAL_ 2549088333 Sitzmemo_BFS_Nachlauftyp 0 "Komm_bei_KL15_EIN" 1 "Komm_nach_KL15_AUS" 2 "Komm_bei_KL15_AUS" ;
VAL_ 2549088333 Sitzmemo_BFS_SNI 77 "" ;
VAL_ 2549088333 NM_Sitzmemo_BFS_Wakeup 0 "Peripherie_Wakeup__Ursache_nicht_bekannt" 1 "Bus_Wakeup" 2 "KL15_HW" 3 "Sitzhandverstellung" ;
VAL_ 2549088333 NM_Sitzmemo_BFS_Subsystemaktiv 0 "Subsystem_war_nicht_lokalaktiv" 1 "war_lokalaktiv" ;
VAL_ 2549088333 NM_Sitzmemo_BFS_Lokalaktiv 0 "war_nicht_lokal_aktiv" 1 "war_lokal_aktiv" ;
VAL_ 2549088333 Mem_BFS_KD_Fehler 0 "kein_KD_Fehler" 1 "KD_Fehler" ;
VAL_ 2549088332 Sitzmemo_FS_KompSchutz 0 "inaktiv" 1 "aktiv" ;
VAL_ 2549088332 Sitzmemo_FS_Abschaltstufe 0 "keine_Einschraenkung" 1 "Funktionseinschraenkung" ;
VAL_ 2549088332 Sitzmemo_FS_Transport_Mode 0 "keine_Einschraenkung" 1 "Funktionseinschraenkung" ;
VAL_ 2549088332 Sitzmemo_FS_Nachlauftyp 0 "Komm_bei_KL15_EIN" 1 "Komm_nach_KL15_AUS" 2 "Komm_bei_KL15_AUS" ;
VAL_ 2549088332 Sitzmemo_FS_SNI 76 "" ;
VAL_ 2549088332 NM_Sitzmemo_FS_Wakeup 0 "Peripherie_Wakeup__Ursache_nicht_bekannt" 1 "Bus_Wakeup" 2 "KL15_HW" 3 "Sitzverstellschalter" 5 "P1_Taster" 6 "P2_Taster" 7 "P3_Taster" 8 "SET_Taster" ;
VAL_ 2549088332 NM_Sitzmemo_FS_Lokalaktiv 0 "war_nicht_lokal_aktiv" 1 "war_lokal_aktiv" ;
VAL_ 2549088332 NM_Sitzmemo_FS_Subsystemaktiv 0 "Subsystem_war_nicht_lokalaktiv" 1 "war_lokalaktiv" ;
VAL_ 2549088332 Mem_FS_KD_Fehler 0 "kein_KD_Fehler" 1 "KD_Fehler" ;
VAL_ 2549088292 SpoilerSG_KompSchutz 0 "inaktiv" 1 "aktiv" ;
VAL_ 2549088292 SpoilerSG_Abschaltstufe 0 "keine_Einschraenkung" 1 "Funktionseinschraenkung" ;
VAL_ 2549088292 SpoilerSG_Transport_Mode 0 "keine_Einschraenkung" 1 "Funktionseinschraenkung" ;
VAL_ 2549088292 SpoilerSG_Nachlauftyp 0 "Komm_bei_KL15_EIN" 1 "Komm_nach_KL15_AUS" 2 "Komm_bei_KL15_AUS" ;
VAL_ 2549088292 SpoilerSG_SNI 36 "" ;
VAL_ 2549088292 NM_SpoilerSG_Wakeup 0 "Peripherie_Wakeup__Ursache_nicht_bekannt" 1 "Bus_Wakeup" 2 "KL15_HW" ;
VAL_ 2549088292 KN_SpoilerSG_ECUKnockOut 0 "Funktion_nicht_ausgeloest" 2 "SG_wurde_ausgeschaltet" 3 "Funktion_deaktiviert" ;
VAL_ 2549088292 KN_SpoilerSG_WakePrevention 0 "Funktion_nicht_ausgeloest" 1 "WakePrevention_aktiv" 2 "Reset_durchgefuehrt" 3 "Funktion_deaktiviert" ;
VAL_ 2549088292 NM_SpoilerSG_Lokalaktiv 0 "war_nicht_lokal_aktiv" 1 "war_lokal_aktiv" ;
VAL_ 2549088292 NM_SpoilerSG_Subsystemaktiv 0 "Subsystem_war_nicht_lokalaktiv" 1 "war_lokalaktiv" ;
VAL_ 2549088292 SpoilerSG_KD_Fehler 0 "kein_KD_Fehler" 1 "KD_Fehler" ;
VAL_ 2549088299 STS_KompSchutz 0 "inaktiv" 1 "aktiv" ;
VAL_ 2549088299 STS_Abschaltstufe 0 "keine_Einschraenkung" 1 "Funktionseinschraenkung" ;
VAL_ 2549088299 STS_Transport_Mode 0 "keine_Einschraenkung" 1 "Funktionseinschraenkung" ;
VAL_ 2549088299 STS_Nachlauftyp 0 "Komm_bei_KL15_EIN" 1 "Komm_nach_KL15_AUS" 2 "Komm_bei_KL15_AUS" ;
VAL_ 2549088299 STS_SNI 43 "" ;
VAL_ 2549088299 KN_VTS_BusKnockOutTimer 255 "BusKnockOut_deaktiviert" ;
VAL_ 2549088299 NM_STS_Wakeup 0 "Peripherie_Wakeup__Ursache_nicht_bekannt" 1 "Bus_Wakeup" 2 "KL15_HW" ;
VAL_ 2549088299 KN_VTS_ECUKnockOut 0 "Funktion_nicht_ausgeloest" 2 "SG_wurde_ausgeschaltet" 3 "Funktion_deaktiviert" ;
VAL_ 2549088299 KN_VTS_WakePrevention 0 "Funktion_nicht_ausgeloest" 1 "WakePrevention_aktiv" 2 "Reset_durchgefuehrt" 3 "Funktion_deaktiviert" ;
VAL_ 2549088299 NM_STS_Lokalaktiv 0 "war_nicht_lokal_aktiv" 1 "war_lokal_aktiv" ;
VAL_ 2549088299 NM_STS_Subsystemaktiv 0 "Subsystem_war_nicht_lokalaktiv" 1 "war_lokalaktiv" ;
VAL_ 2549088299 STS_KD_Fehler 0 "kein_KD_Fehler" 1 "KD_Fehler" ;
VAL_ 2549088331 TSG_BFS_KompSchutz 0 "inaktiv" 1 "aktiv" ;
VAL_ 2549088331 TSG_BFS_Abschaltstufe 0 "keine_Einschraenkung" 1 "Funktionseinschraenkung" ;
VAL_ 2549088331 TSG_BFS_Transport_Mode 0 "keine_Einschraenkung" 1 "Funktionseinschraenkung" ;
VAL_ 2549088331 TSG_BFS_Nachlauftyp 0 "Komm_bei_KL15_EIN" 1 "Komm_nach_KL15_AUS" 2 "Komm_bei_KL15_AUS" ;
VAL_ 2549088331 TSG_BFS_SNI 75 "" ;
VAL_ 2549088331 KN_TSG_BFS_BusKnockOutTimer 255 "BusKnockOut_deaktiviert" ;
VAL_ 2549088331 NM_TSG_BFS_Wakeup 0 "Peripherie_Wakeup__Ursache_nicht_bekannt" 1 "Bus_Wakeup" 2 "KL15_HW" 4 "KL30_Reset" 5 "LIN_Wakeup" 6 "Drehfalle" 10 "Memory_Pos_Taste_1" 11 "Memory_Pos_Taste_2" 12 "Memory_Speichern_Taste" 13 "Schliesszylinder_entriegeln" 14 "Schliesszylinder_verriegeln" 15 "Innenverriegelungstaster_verriegeln" 16 "Innenverriegelungstaster_entriegeln" 18 "Tueraussengrifftaster" 19 "Tueraussengriffverriegelungstaster" 20 "Fensterheberbedienfeld" 24 "Schlossrueckmeldeleitung" 27 "Memory_Pos_Taste_3" ;
VAL_ 2549088331 KN_TSG_BFS_ECUKnockOut 0 "Funktion_nicht_ausgeloest" 2 "SG_wurde_ausgeschaltet" 3 "Funktion_deaktiviert" ;
VAL_ 2549088331 KN_TSG_BFS_WakePrevention 0 "Funktion_nicht_ausgeloest" 1 "WakePrevention_aktiv" 2 "Reset_durchgefuehrt" 3 "Funktion_deaktiviert" ;
VAL_ 2549088331 NM_TSG_BFS_Lokalaktiv 0 "war_nicht_lokal_aktiv" 1 "war_lokal_aktiv" ;
VAL_ 2549088331 NM_TSG_BFS_Subsystemaktiv 0 "Subsystem_war_nicht_lokalaktiv" 1 "war_lokalaktiv" ;
VAL_ 2549088331 TSG_BFS_KD_Fehler 0 "kein_KD_Fehler" 1 "KD_Fehler" ;
VAL_ 2549088330 TSG_FS_KompSchutz 0 "inaktiv" 1 "aktiv" ;
VAL_ 2549088330 TSG_FS_Abschaltstufe 0 "keine_Einschraenkung" 1 "Funktionseinschraenkung" ;
VAL_ 2549088330 TSG_FS_Transport_Mode 0 "keine_Einschraenkung" 1 "Funktionseinschraenkung" ;
VAL_ 2549088330 TSG_FS_Nachlauftyp 0 "Komm_bei_KL15_EIN" 1 "Komm_nach_KL15_AUS" 2 "Komm_bei_KL15_AUS" ;
VAL_ 2549088330 TSG_FS_SNI 74 "" ;
VAL_ 2549088330 KN_TSG_FS_BusKnockOutTimer 255 "BusKnockOut_deaktiviert" ;
VAL_ 2549088330 NM_TSG_FS_Wakeup 0 "Peripherie_Wakeup__Ursache_nicht_bekannt" 1 "Bus_Wakeup" 2 "KL15_HW" 4 "KL30_Reset" 5 "LIN_Wakeup" 6 "Drehfalle" 7 "HDF_Taster" 8 "KiSi_Links_Taster" 9 "KiSi_Rechts_Taster" 10 "Memory_Pos_Taste_1" 11 "Memory_Pos_Taste_2" 12 "Memory_Speichern_Taste" 13 "Schliesszylinder_entriegeln" 14 "Schliesszylinder_verriegeln" 15 "Innenverriegelungstaster_verriegeln" 16 "Innenverriegelungstaster_entriegeln" 17 "TDE_Taster" 18 "Türaussengrifftaster" 19 "Tueraussengriffverriegelungstaster" 20 "Fensterheberbedienfeld" 21 "Spiegelverstell_Taster" 22 "DWA_Taster" 24 "Schlossrueckmeldeleitung" 25 "Tuerinnengriff" 26 "SWA_Taster" 27 "Memory_Pos_Taste_3" ;
VAL_ 2549088330 KN_TSG_FS_ECUKnockOut 0 "Funktion_nicht_ausgeloest" 2 "SG_wurde_ausgeschaltet" 3 "Funktion_deaktiviert" ;
VAL_ 2549088330 KN_TSG_FS_WakePrevention 0 "Funktion_nicht_ausgeloest" 1 "WakePrevention_aktiv" 2 "Reset_durchgefuehrt" 3 "Funktion_deaktiviert" ;
VAL_ 2549088330 NM_TSG_FS_Lokalaktiv 0 "war_nicht_lokal_aktiv" 1 "war_lokal_aktiv" ;
VAL_ 2549088330 NM_TSG_FS_Subsystemaktiv 0 "Subsystem_war_nicht_lokalaktiv" 1 "war_lokalaktiv" ;
VAL_ 2549088330 TSG_FS_KD_Fehler 0 "kein_KD_Fehler" 1 "KD_Fehler" ;
VAL_ 2549088301 VSG_KompSchutz 0 "inaktiv" 1 "aktiv" ;
VAL_ 2549088301 VSG_Abschaltstufe 0 "keine_Einschraenkung" 1 "Funktionseinschraenkung" ;
VAL_ 2549088301 VSG_Transport_Mode 0 "keine_Einschraenkung" 1 "Funktionseinschraenkung" ;
VAL_ 2549088301 VSG_Nachlauftyp 0 "Komm_bei_KL15_EIN" 1 "Komm_nach_KL15_AUS" 2 "Komm_bei_KL15_AUS" ;
VAL_ 2549088301 VSG_SNI 45 "" ;
VAL_ 2549088301 KN_VSG_BusKnockOutTimer 255 "BusKnockOut_deaktiviert" ;
VAL_ 2549088301 NM_VSG_Wakeup 0 "Peripherie_Wakeup__Ursache_nicht_bekannt" 1 "Bus_Wakeup" 2 "KL15_HW" 3 "KL30_Reset" ;
VAL_ 2549088301 NM_VSG_Lokalaktiv 0 "war_nicht_lokal_aktiv" 1 "war_lokal_aktiv" ;
VAL_ 2549088301 NM_VSG_Subsystemaktiv 0 "Subsystem_war_nicht_lokalaktiv" 1 "war_lokalaktiv" ;
VAL_ 2549088301 VSG_KD_Fehler 0 "kein_KD_Fehler" 1 "KD_Fehler" ;
VAL_ 779 KBI_ABS_Lampe 0 "ABS Lampe aus" 1 "ABS Lampe ein" ;
VAL_ 779 KBI_ESP_Lampe 0 "ESP Lampe aus" 1 "ESP Lampe ein" ;
VAL_ 779 KBI_BKL_Lampe 0 "BKL aus" 1 "BKL ein" ;
VAL_ 779 KBI_Airbag_Lampe 0 "Airbag Lampe aus" 1 "Airbag Lampe ein" ;
VAL_ 779 KBI_SILA_gueltig 0 "ungueltig" 1 "gueltig" ;
VAL_ 779 KBI_Vorglueh_System_Lampe 0 "Lampe aus" 1 "Lampe ein" ;
VAL_ 779 KBI_NV_in_Anzeige 0 "NV_nicht_in_Anzeige" 1 "NV_in_Anzeige" ;
VAL_ 779 KBI_Anzeigestatus_ACC 0 "keine_ACC_Anzeige" 1 "ACC_Anzeige_aktiv" ;
VAL_ 779 KBI_Anzeigestatus_GRA 0 "nicht_vorhanden" 1 "Anzeigemoeglichkeit_vorhanden" 2 "reserviert" 3 "Fehler" ;
VAL_ 779 KBI_Oeldruck_Schalter 0 "offen____p_kleiner_pnenn" 1 "geschlossen____p_groessergleich_pnenn" ;
VAL_ 779 KBI_Tankwarnung 0 "Lampe aus" 1 "Lampe ein" ;
VAL_ 779 KBI_MFA_v_Einheit_01 0 "kmh" 1 "mph" ;
VAL_ 779 KBI_im_Stellgliedtest 0 "kein Stellgliedtest" 1 "Kombi im Stellgliedtest" ;
VAL_ 779 KBI_Anzeigefehler_LDW 0 "nicht vorhanden bzw. unterstützt" 1 "Anzeige iO" 2 "Anzeigefehler" 3 "nicht definiert" ;
VAL_ 779 KBI_Oeldruckwarnung 0 "inaktiv" 1 "aktiv" ;
VAL_ 779 KBI_Handbremse 0 "nicht_angezogen" 1 "angezogen" ;
VAL_ 779 KBI_PLA_in_Anzeige 0 "PLA_nicht_in_Anzeige" 1 "PLA_in_Anzeige" ;
VAL_ 779 KBI_Anzeigefehler_NV 0 "kein_Anzeigefehler" 1 "Anzeigefehler" ;
VAL_ 779 KBI_Anzeigestatus_LIM 0 "nicht_vorhanden" 1 "Anzeigemoeglichkeit_vorhanden" 2 "reserviert" 3 "Fehler" ;
VAL_ 779 KBI_ARA_in_Anzeige 0 "ARA nicht in Anzeige" 1 "ARA in Anzeige" ;
VAL_ 779 KBI_Einheit_Tacho 0 "km/h" 1 "mph" ;
VAL_ 779 KBI_Konsistenz_ACC 0 "ACC Botschaft konsistent" 1 "ACC Botschaft inkonsistent    " ;
VAL_ 779 KBI_Fehler_Anzeige_ACC 0 " iO" 1 "Anzeigefehler ACC" ;
VAL_ 779 KBI_Anzeigefehler_SWA 0 "nicht vorhanden bzw. unterstützt" 1 "Anzeige iO" 2 "Anzeigefehler" 3 "nicht definiert" ;
VAL_ 1719 KBI_Kilometerstand 1048574 "Init" 1048575 "Fehler" ;
VAL_ 1719 KBI_Standzeit_02 131069 "nicht_verfuegbar" 131070 "Init" 131071 "Fehler" ;
VAL_ 1719 KBI_Reserve_Warnung_Sek 0 "Keine_Warnung" 1 "Sekundaere_Reservewarnung" ;
VAL_ 1719 KBI_RDK_Kalibrier_Anf 0 "keine_Kalibrieranforderung" 1 "Kalibrieranforderung" ;
VAL_ 1719 KBI_Inhalt_Tank 126 "Init" 127 "Fehler" ;
VAL_ 1719 KBI_FStatus_Tank 0 "Tankfüllstand i.O." 1 "Tankfüllstand n.i.O" ;
VAL_ 1719 KBI_Oelwechsel_durchgefuehrt 0 "Oelwechsel_nicht_durchgefuehrt" 1 "Oelwechsel_durchgefuehrt" ;
VAL_ 1719 KBI_QBit_Aussen_Temp_gef 0 "gueltiger_Wert" 1 "Ersatz_Init_oder_Fehlerwert" ;
VAL_ 1719 KBI_Aussen_Temp_gef 253 "nicht verbaut" 254 "Init" 255 "Fehler" ;
VAL_ 1720 KBI_Variante_USA 0 "keine USA-Variante" 1 "USA-Variante" ;
VAL_ 1720 KBI_Variante 0 "Zeiger Kombiinstrument" 1 "Volldisplay Kombiinstrument" ;
VAL_ 1720 KBI_BCmE_aktiv 0 "Anzeige_nicht_aktiv" 1 "Anzeige_aktiv" ;
VAL_ 1720 KBI_Sparhinweis_quittiert 0 "nicht_quittiert" 1 "quittiert" ;
VAL_ 1720 KBI_Tankfuellstand_Prozent 126 "Init" 127 "Fehler" ;
VAL_ 1720 KBI_Nachtanken_erkannt 0 "Geberbetrieb" 1 "Nachtankmodus" ;
VAL_ 1720 KBI_Tankinhalt_hochaufl 16382 "Init" 16383 "Fehler" ;
VAL_ 1720 KBI_Max_Tankinhalt 254 "Init" 255 "Fehler" ;
VAL_ 1724 KBI_Oil_dis_status 0 "Funktion nicht verfügbar" 1 "kein Wert berechnet" 2 "Service in ..." 3 "Service seit ... " ;
VAL_ 1724 KBI_Oil_dis_unit 0 "km" 1 "Meilen" ;
VAL_ 1724 KBI_Oil_time_status 0 "Funktion nicht verfügbar" 1 "kein Wert berechnet" 2 "Service in ..." 3 "Service seit ... " ;
VAL_ 1724 KBI_Insp_dis_status 0 "Funktion nicht verfügbar" 1 "kein Wert berechnet" 2 "Service in ..." 3 "Service seit ... " ;
VAL_ 1724 KBI_Insp_dis_unit 0 "km" 1 "Meilen" ;
VAL_ 1724 KBI_Insp_time_status 0 "Funktion nicht verfügbar" 1 "kein Wert berechnet" 2 "Service in ..." 3 "Service seit ... " ;
VAL_ 2589283471 KBI_Signatur_Wegstrecke_01 0 "Init" ;
VAL_ 2589283471 KBI_Status_Aktive_Meldungen 0 "Keine_Aenderung_Init" 1 "Aenderung_aktiv" ;
VAL_ 2589283471 KBI_Status_Historie_Meldungen 0 "Keine_Aenderung_Init" 1 "Aenderung_aktiv" ;
VAL_ 2589283471 KBI_Status_SK_Meldungen 0 "Keine_Aenderung_Init" 1 "Aenderung_aktiv" ;
VAL_ 2589283471 KBI_Wegstrecke 1048575 "Init" ;
VAL_ 2589283471 KBI_Signatur_Wegstrecke_02 0 "Init" ;
VAL_ 919 LDW_Gong 0 "kein akustisches Signal" 1 "Gong_1" 2 "Gong_2" 3 "nicht definiert" ;
VAL_ 919 LDW_Frueh_Spaet 0 "frueh_frueh_aktiv" 1 "frueh_spaet_aktiv" 2 "spaet_spaet_aktiv" 3 "Fehler" ;
VAL_ 919 LDW_Texte 0 "keine Anzeige" 1 "Lane assist zur Zeit nicht verfügbar" 2 "Lane assist Systemfehler" 3 "Lane assist zur Zeit keine Sensorsicht" 4 "Lane assist Fahreruebernahme" 6 "Emergency_Alert_Fahreruebernahme" 7 "Lane_assist_Fahreruebernahme_leise" ;
VAL_ 919 LDW_Seite_DLCTLC 0 "links" 1 "rechts" ;
VAL_ 919 LDW_Lernmodus 0 "LDW aus" 1 "LDW an/inaktiv" 2 "LDW an/aktiv" 3 "Warnung rechts" 4 "Warnung links" 5 "nicht definiert" 6 "nicht definiert" 7 "nicht definiert" ;
VAL_ 919 LDW_Lernmodus_seitenabhaengig 0 "links_aus__rechts_aus" 1 "HCCA_links_an__rechts_an" 2 "HCCA_links_an__rechts_Warnung" 3 "HCCA_links_Warnung__rechts_an" 4 "nicht_definiert" 5 "links_outlined__rechts_outlined" 6 "links_outlined__rechts_an" 7 "links_outlined__rechts_Warnung" 8 "nicht_definiert" 9 "links_an__rechts_outlined" 10 "links_an__rechts_an" 11 "links_an__rechts_Warnung" 12 "nicht_definiert" 13 "links_Warnung__rechts_outlined" 14 "links_Warnung__rechts_an" 15 "links_Warnung__rechts_Warnung" ;
VAL_ 919 LDW_TLC 31 "Init" ;
VAL_ 919 HC_Uss_Anforderung 0 "Ultraschallsensoren Aus" 1 "Ultraschallsensoren An" ;
VAL_ 919 EA_Warnblinken 0 "aus" 1 "Statisch" 2 "Taster" 3 "Statisch_ohne_WBT" ;
VAL_ 919 LDW_Warnung_links 0 "Warnung links aus" 1 "Warnung links ein" ;
VAL_ 919 LDW_Warnung_rechts 0 "Warnung rechts aus" 1 "Warnung rechts ein" ;
VAL_ 919 LDW_Codierinfo_fuer_VLR 0 "ohne VLR, ohne Akustik" 1 "HMI-Variante VLR" 2 "HMI-Variante VLR + Akustik" 3 "HMI-Variante Akustik" ;
VAL_ 919 LDW_Status_LED_gelb 0 "LDW-Status gelb aus" 1 "LDW-Status gelb aktiv" ;
VAL_ 919 LDW_Status_LED_gruen 0 "LDW-Status gruen aus" 1 "LDW-Status gruen aktiv" ;
VAL_ 810 EPS_SpannungsAnf 0 "keine_Anforderung" 1 "Anforderung_Stufe1" 2 "Anforderung_Stufe2" 3 "Anforderung_Stufe3" ;
VAL_ 810 EPS_Fehlerlampe 0 "Lampe_aus" 1 "Lampe_ein" ;
VAL_ 810 EPS_Warnungen 0 "kein_Text" 1 "Text_1" 2 "Text_2" 3 "Text_3" 4 "Text_4" 5 "Text_5" ;
VAL_ 810 EPS_PWR_Abbruch 0 "Init/Invalid" 1 "PWR beendet durch EPS-SG wegen vFzg" 2 "PWR beendet durch EPS-SG wegen HM" 3 "Lenkwinkeldifferenz zu groß" 4 "Gradient der Zielanforderung zu groß" 5 "reserviert" 6 "reserviert" 7 "reserviert" 8 "Falscher PLA-Status" 9 "Falscher ARA-Status" 10 "reserviert" 11 "reserviert" 12 "reserviert" 13 "reserviert" 14 "reserviert" 15 "reserviert" ;
VAL_ 810 EPS_PWR_Fehler 0 "Init/Invalid" 1 "Unterstützungsleistung zu gering" 2 "reserviert" 3 "Rotorwinkel nicht initialisiert" 4 "BCM1/Rückfahrlicht veraltet" 5 "reserviert" 6 "reserviert" 7 "Fehler ESP(vFzg)" 8 "Fehler ESP(Raddrehzahlen)" 9 "reserviert" 10 "reserviert" 11 "reserviert" 12 "reserviert" 13 "reserviert" 14 "EPS_ARA_Satus == 6" 15 "EPS_PLA_Satus == 6" ;
VAL_ 810 EPS_PLA_Status 0 "EPS_PLA_Deaktiv" 1 "EPS_PLA_Init" 2 "EPS_PLA_Fehler_mit_Eintrag" 3 "reserviert" 4 "reserviert" 5 "reserviert" 6 "EPS_PLA_Lenkwinkel_aktiv" 7 "EPS_PLA_Abgewiesen" 8 "EPS_PLA_Funktionsbereit" 9 "reserviert" 10 "EPS_PLA_Abbruch" 11 "reserviert" 12 "reserviert" 13 "reserviert" 14 "reserviert" 15 "reserviert" ;
VAL_ 810 EPS_Charisma_FahrPr 0 "keine_Funktion" 1 "Programm_1" 2 "Programm_2" 3 "Programm_3" 4 "Programm_4" 5 "Programm_5" 6 "Programm_6" 7 "Programm_7" 8 "Programm_8" 9 "Programm_9" 10 "Programm_10" 11 "Programm_11" 12 "Programm_12" 13 "Programm_13" 14 "Programm_14" 15 "Programm_15" ;
VAL_ 810 EPS_Charisma_Status 0 "Init" 1 "verfuegbar" 2 "nicht_verfuegbar" 3 "asynchron_durch_Fahrerwunsch" ;
VAL_ 810 EPS_Lenkerposition 0 "unbekannt" 1 "Linkslenker" 2 "Rechtslenker" ;
VAL_ 810 EPS_Anf_KL 0 "keine_Anforderung" 1 "Anforderung_Kuehlung" ;
VAL_ 810 EPS_ARA_Status 0 "EPS_ARA_Deaktiv" 1 "EPS_ARA_Init" 2 "EPS_ARA_Fehler_mit_Eintrag" 3 "reserviert" 4 "reserviert" 5 "reserviert" 6 "EPS_ARA_Lenkwinkel_aktiv" 7 "EPS_ARA_Abgewiesen" 8 "EPS_ARA_Funktionsbereit" 9 "reserviert" 10 "EPS_ARA_Abbruch" 11 "reserviert" 12 "reserviert" 13 "reserviert" 14 "reserviert" 15 "reserviert" ;
VAL_ 160 EPS_Lenkmoment_AbsReduz 13 "MAX" 14 "Init" 15 "Fehler" ;
VAL_ 160 EPS_Zahnstangen_Pos 4094 "Init" 4095 "Fehler" ;
VAL_ 160 EPS_VZ_Zahnstangenposition 0 "pos_VZ" 1 "neg_VZ" ;
VAL_ 160 EPS_QBit_Zahnstangen_Pos 0 "gueltiger_Wert" 1 "Ersatz_Init_oder_Fehlerwert" ;
VAL_ 160 EPS_Versorgungsstatus 0 "kein_Fehler" 1 "Unterspannung" 2 "Ueberspannung" 3 "Stoerung" ;
VAL_ 160 EPS_Versorgungsspannung 254 "Init" 255 "Fehler" ;
VAL_ 160 EPS_AWA_Status 0 "AWA_deaktiviert" 1 "AWA_Anf_nicht_ausfuehrbar" 2 "Kom_AWA_gestoert" 3 "EPS_bzgl_AWA_funktionsbereit" 4 "AWA_Anf_abgew" 5 "ext_Momeingriff_aktiv" 6 "ext_LWeingriff_aktiv" 7 "ext_MomLWeingriff_aktiv" 8 "AWA_abgewiesen_aufgrund_Momentenpriorisierung" 14 "Init" ;
VAL_ 160 EPS_STA_Status 0 "STA_deaktiviert" 1 "Anf_nicht_ausfuehrbar" 2 "Komunikationsfehler" 3 "EPS_bzgl_STA_funktionsbereit" 4 "Anf_abgewiesen_Fehler" 5 "gesperrt" 6 "Winkeleingriff_aktiv" 7 "gesperrt" 8 "Anf_abgewiesen_Prio" 9 "reserviert" 10 "Winkeleingriff_abgebrochen" 11 "Rueckfallmodus_Winkeleingriff" 14 "Init" ;
VAL_ 981 BCM1_Kurvenlicht_links_Anf 0 "linkes_Kurvenlicht/Abbiegelicht_durch_BCM1_nicht_angesteuert" 1 "linkes_Kurven/Abbiegelicht_durch_BCM1_angesteuert" ;
VAL_ 981 BCM1_Kurvenlicht_rechts_Anf 0 "rechtes_Kurvenlicht/Abbiegelicht_durch_BCM1_nicht_angesteuert" 1 "rechtes_Kurvenlicht/Abbiegelicht_durch_BCM1_angesteuert" ;
VAL_ 981 BCM1_Standlicht_Anf 0 "Licht_nicht_angefordert" 1 "Licht ist einzuschalten" ;
VAL_ 981 BCM1_Abblendlicht_Anf 0 "Licht_nicht_angefordert" 1 "Licht ist einzuschalten" ;
VAL_ 981 BCM1_Fernlicht_Anf 0 "Licht_nicht_angefordert" 1 "Licht ist einzuschalten" ;
VAL_ 981 BCM1_Nebellicht_Anf 0 "Licht_nicht_angefordert" 1 "Licht ist einzuschalten" ;
VAL_ 981 BCM1_Parklicht_li_Anf 0 "Licht_nicht_angefordert" 1 "Licht ist einzuschalten" ;
VAL_ 981 BCM1_Parklicht_re_Anf 0 "Licht_nicht_angefordert" 1 "Licht ist einzuschalten" ;
VAL_ 981 BCM1_Nebelschluss_Ahg_Anf 0 "Licht_nicht_angefordert" 1 "Licht ist einzuschalten" ;
VAL_ 981 BCM1_Nebelschluss_Fzg_Anf 0 "Licht_nicht_angefordert" 1 "Licht ist einzuschalten" ;
VAL_ 981 BCM1_Schlusslicht_Anf 0 "Licht_nicht_angefordert" 1 "Licht ist einzuschalten" ;
VAL_ 981 BCM_Rueckfahrlicht_Anf 0 "Licht_nicht_angefordert" 1 "Licht_angefordert" ;
VAL_ 981 BCM1_Umfeldleuchten_Anf 0 "Licht_nicht_angefordert" 1 "Licht ist einzuschalten" ;
VAL_ 981 BCM1_Tagfahrlicht_Anf 0 "Licht_nicht_angefordert" 1 "Licht ist einzuschalten" ;
VAL_ 981 BCM1_Regenlicht_Anf 0 "Licht_nicht_angefordert" 1 "Licht ist einzuschalten" ;
VAL_ 981 BCM1_Autobahnlicht_Anf 0 "Licht_nicht_angefordert" 1 "Licht ist einzuschalten" ;
VAL_ 981 BCM1_Touristen_Licht_Anf 0 "Licht_nicht_angefordert" 1 "Anforderung von Touristenlicht" ;
VAL_ 981 BCM1_Gleitende_Leuchtw_Anf 0 "Aus" 1 "Ein" ;
VAL_ 981 BCM1_GLW_Fernlicht_Anf 0 "Aus" 1 "Ein" ;
VAL_ 981 BCM1_Adaptive_Lichtvert_Anf 0 "Aus" 1 "Ein" ;
VAL_ 981 BCM1_CH_LH_aktiv 0 "Comming_Home_Bzw._Leaving_Home_nicht_aktiv" 1 "Comming Home bzw. Leaving Home aktiv" ;
VAL_ 981 BCM1_Allwetterlicht_Anf 0 "Licht_nicht_angefordert" 1 "Licht_ist_einzuschalten" ;
VAL_ 982 BCM2_Bremsl_durch_ECD 0 "Bremslicht_ist_aus" 1 "Bremslicht_durch_ECD_aktiv" ;
VAL_ 982 LH_Aussenlicht_def 0 "OK" 1 "defekt" ;
VAL_ 982 LH_Standlicht_H_aktiv 1 "Standlicht hinten aktiv" ;
VAL_ 982 LH_Parklicht_HL_aktiv 0 "nicht aktiv" 1 "Parklicht hinten links aktiv" ;
VAL_ 982 LH_Parklicht_HR_aktiv 0 "nicht aktiv" 1 "Parklicht hinten rechts aktiv" ;
VAL_ 982 LH_Bremslicht_H_aktiv 1 "Bremslicht hinten aktiv" ;
VAL_ 982 LH_Nebelschluss_aktiv 0 "nicht aktiv" 1 "aktiv" ;
VAL_ 982 LH_Rueckfahrlicht_aktiv 0 "nicht aktiv" 1 "aktiv" ;
VAL_ 982 LH_Blinker_HL_akt 1 "Blinker hinten links aktiv" ;
VAL_ 982 LH_Blinker_HR_akt 1 "Blinker hinten rechts aktiv" ;
VAL_ 982 LH_Blinker_li_def 0 "OK" 1 "Blinker hinten links defekt" ;
VAL_ 982 LH_Bremsl_li_def 0 "OK" 1 "mindestens ein Bremslicht hinten links defekt" ;
VAL_ 982 LH_Schlusslicht_li_def 0 "OK" 1 "mindestens ein Schlusslicht hinten links defekt" ;
VAL_ 982 LH_Rueckf_li_def 0 "OK" 1 "Rückfahrlicht hinten links defekt" ;
VAL_ 982 LH_Nebel_li_def 0 "OK" 1 " Nebelschlusslicht hinten links defekt" ;
VAL_ 982 LH_Schluss_Brems_Nebel_li_def 0 "iO" 1 "defekt" ;
VAL_ 982 LH_Schluss_Brems_Nebel_re_def 0 "iO" 1 "defekt" ;
VAL_ 982 LH_Schluss_Brems_li_def 0 "OK" 1 "defekt" ;
VAL_ 982 LH_Schluss_Nebel_li_def 0 "OK" 1 "defekt" ;
VAL_ 982 LH_SL_BRL_BLK_li_def 0 "OK" 1 "defekt" ;
VAL_ 982 LH_Brems_Blk_li_def 0 "OK" 1 "defekt" ;
VAL_ 982 LH_Blinker_re_def 0 "OK" 1 "Blinker hinten rechts defekt" ;
VAL_ 982 LH_Bremsl_re_def 0 "OK" 1 "mindestens ein Bremslicht hinten rechts defekt" ;
VAL_ 982 LH_Schlusslicht_re_def 0 "OK" 1 "mindestens ein Schlusslicht hinten rechts defekt" ;
VAL_ 982 LH_Rueckf_re_def 0 "OK" 1 "Rückfahrlicht hinten rechts defekt" ;
VAL_ 982 LH_Nebel_re_def 0 "OK" 1 "Nebelschlusslicht hinten rechts defekt" ;
VAL_ 982 LH_Schluss_Brems_re_def 0 "OK" 1 "defekt" ;
VAL_ 982 LH_Schluss_Nebel_re_def 0 "OK" 1 "defekt" ;
VAL_ 982 LH_SL_BRL_BLK_re_def 0 "OK" 1 "defekt" ;
VAL_ 982 LH_Brems_Blk_re_def 0 "OK" 1 "defekt" ;
VAL_ 982 LH_Kennzl_def 0 "OK" 1 "Kennzeichenbeleuchtung hinten defekt" ;
VAL_ 982 LH_3_Bremsl_def 0 "OK" 1 "hochgesetzte  Bremsleuchte defekt" ;
VAL_ 982 LH_Nebel_mi_def 0 "OK" 1 " Nebelschlusslicht hinten Mitte defekt" ;
VAL_ 982 LH_Rueckf_mi_def 0 "OK" 1 "Rückfahllicht Mitte defekt" ;
VAL_ 982 LH_Bremsl_li_ges_def 0 "OK" 1 "Alle Bremslichter hinten links defekt" ;
VAL_ 982 LH_Bremsl_re_ges_def 0 "OK" 1 "Alle Bremslichter hinten rechts defekt" ;
VAL_ 1624 LV_Standlicht_Anzeige 0 "nicht aktiv" 1 "aktiv" ;
VAL_ 1624 LV_Abblendlicht_Anzeige 0 "nicht aktiv" 1 "aktiv" ;
VAL_ 1624 LV_Fernlicht_Anzeige 0 "nicht aktiv" 1 "aktiv" ;
VAL_ 1624 LV_Nebellicht_Anzeige 0 "nicht aktiv" 1 "aktiv" ;
VAL_ 1624 LV_Nebelschlusslicht_Anzeige 0 "nicht aktiv" 1 "aktiv" ;
VAL_ 1624 LV_Tagfahrlicht_Anzeige 0 "nicht aktiv" 1 "aktiv" ;
VAL_ 1624 LV_AFL_aktiv_Anzeige 0 "nicht aktiv" 1 "aktiv" ;
VAL_ 1624 LV_AFL_defekt 0 "OK" 1 "defekt" ;
VAL_ 1624 LV_Blinker_li_def 0 "OK" 1 "defekt" ;
VAL_ 1624 LV_Standlicht_li_def 0 "OK" 1 "defekt" ;
VAL_ 1624 LV_Abblendlicht_li_def 0 "OK" 1 "defekt" ;
VAL_ 1624 LV_Fernlicht_li_def 0 "OK" 1 "defekt" ;
VAL_ 1624 LV_Nebellicht_li_def 0 "OK" 1 "defekt" ;
VAL_ 1624 LV_Blk_li_Seite_def 0 "OK" 1 "defekt" ;
VAL_ 1624 LV_Tagfahrlicht_li_def 0 "OK" 1 "defekt" ;
VAL_ 1624 LV_FLA_aktiv_Anzeige 0 "aus" 1 "ein" ;
VAL_ 1624 LV_FLA_defekt 0 "i.O." 1 "FLA defekt" ;
VAL_ 1624 LV_FLA_Sensor_blockiert 0 "i.O." 1 "FLA-Sensor blockiert" ;
VAL_ 1624 LV_Blinker_re_def 0 "OK" 1 "defekt" ;
VAL_ 1624 LV_Standlicht_re_def 0 "OK" 1 "defekt" ;
VAL_ 1624 LV_Abblendlicht_re_def 0 "OK" 1 "defekt" ;
VAL_ 1624 LV_Fernlicht_re_def 0 "OK" 1 "defekt" ;
VAL_ 1624 LV_Nebellicht_re_def 0 "OK" 1 "defekt" ;
VAL_ 1624 LV_Blk_re_Seite_def 0 "OK" 1 "defekt" ;
VAL_ 1624 LV_Tagfahrlicht_re_def 0 "OK" 1 "defekt" ;
VAL_ 1624 LV_Aussenlicht_def 0 "OK" 1 "defekt" ;
VAL_ 1624 LV_Abblendlicht_TFL_li_def 0 "OK" 1 "defekt" ;
VAL_ 1624 LV_Nebellicht_TFL_li_def 0 "OK" 1 "defekt" ;
VAL_ 1624 LV_Standlicht_TFL_li_def 0 "OK" 1 "defekt" ;
VAL_ 1624 LV_Abblend_Fernlicht_li_def 0 "OK" 1 "defekt" ;
VAL_ 1624 LV_Abblendlicht_TFL_re_def 0 "OK" 1 "defekt" ;
VAL_ 1624 LV_Nebellicht_TFL_re_def 0 "OK" 1 "defekt" ;
VAL_ 1624 LV_Standlicht_TFL_re_def 0 "OK" 1 "defekt" ;
VAL_ 1624 LV_Abblend_Fernlicht_re_def 0 "OK" 1 "defekt" ;
VAL_ 1624 LV_Abbiegelicht_li_def 0 "OK" 1 "defekt" ;
VAL_ 1624 LV_Abbiegelicht_re_def 0 "OK" 1 "defekt" ;
VAL_ 1624 BCM1_Linksverkehr 0 "Rechtsverkehr" 1 "Linksverkehr" ;
VAL_ 1624 BCM1_Licht_Dunkelheit_aktiv 1 "Licht wegen Dunkelheit aktiv, nicht bei Autobahnlicht, Tagfahrlicht oder Regenlicht" ;
VAL_ 1624 LV_LED_Scheinwerfer_li_def 0 "OK" 1 "defekt" ;
VAL_ 1624 LV_LED_Scheinwerfer_re_def 0 "OK" 1 "defekt" ;
VAL_ 1624 LV_Blinker_VL_aktiv 0 "inaktiv" 1 "aktiv" ;
VAL_ 1624 LV_Blinker_VR_aktiv 0 "inaktiv" 1 "aktiv" ;
VAL_ 917 AFS_Abbiegelicht_li_Anf 0 "Abbiegelicht_aus" 1 "Abbiegelicht_ein" ;
VAL_ 917 AFS_Abbiegelicht_re_Anf 0 "Abbiegelicht_aus" 1 "Abbiegelicht_ein" ;
VAL_ 917 AFS_Abbiegelicht_Dimm_Anf 0 "Dimmung_angefordert" 1 "keine_Dimmung" ;
VAL_ 917 AFS_Verfuegbarkeit_GLW 0 "GLW_nicht_verfuegbar" 1 "GLW_verfuegbar" ;
VAL_ 917 AFS_Status_adaptive_LV 0 "adaptive_Lichtverteilung_aus" 1 "adaptive_Lichtverteilung_an" ;
VAL_ 917 AFS_Fernlicht_li_defekt 0 "Fernlicht_in_Ordnung" 1 "Fernlicht_defekt" ;
VAL_ 917 AFS_Fernlicht_re_defekt 0 "Fernlicht_in_Ordnung" 1 "Fernlicht_defekt" ;
VAL_ 917 AFS_Fernlicht_Status 0 "Fernlicht_aus" 1 "Fernlicht_ein" ;
VAL_ 917 AFS_Lampe 0 "Aus" 1 "Ein" ;
VAL_ 917 LWR_Lampe 0 "LWR Fehlerlampe aus" 1 "LWR Fehlerlampe ein" ;
VAL_ 917 AFS_Fehlertext 0 "kein Text" 1 "AFS ohne Funktion" ;
VAL_ 917 AFS_LED_Blinkmode 0 "kein Blinkmode angefordert" 1 "Blinkmode angefordert" ;
VAL_ 917 LWR_Touristenmodus_aktiv 0 "Touristenmodus inaktiv" 1 "Touristenmodus aktiv" ;
VAL_ 917 AFS_Charisma_FahrPr 0 "keine_Funktion" 1 "Programm_1" 2 "Programm_2" 3 "Programm_3" 4 "Programm_4" 5 "Programm_5" 6 "Programm_6" 7 "Programm_7" 8 "Programm_8" 9 "Programm_9" 10 "Programm_10" 11 "Programm_11" 12 "Programm_12" 13 "Programm_13" 14 "Programm_14" 15 "Programm_15" ;
VAL_ 917 AFS_Charisma_Status 0 "Init" 1 "verfuegbar" 2 "nicht_verfuegbar" 3 "asynchron_durch_Fahrerwunsch" ;
VAL_ 917 LWR_Sicherheitsposition_re 0 "inaktiv" 1 "aktiv" ;
VAL_ 917 AFS_Allwetterlicht 0 "Allwetterlicht_nicht_aktiv" 1 "Allwetterlicht_aktiv" ;
VAL_ 917 LWR_Touristenmodus_verbaut 0 "Touristenmodus_nicht_verbaut" 1 "Touristenmodus_verbaut" ;
VAL_ 917 AFS_adaptive_LV_verbaut 0 "adaptive_Lichtverteilung_nicht_verbaut" 1 "adaptive_Lichtverteilung_verbaut" ;
VAL_ 917 LWR_Reisemodus_Texte 0 "keine_Anzeige" 1 "Umschaltung_auf_Linksverkehr_aktiv" 2 "Umschaltung_auf_Rechtsverkehr_aktiv" ;
VAL_ 917 GLW_Sensor_blockiert 0 "Kamera_Sensor_nicht_blockiert" 1 "Kamera_Sensor_blockiert" ;
VAL_ 917 AFS_Charisma_Umschaltung 0 "Idle" 1 "Erkennung_Umschaltaufforderung" 2 "Steuerbotschaft_nicht_definiert" 3 "Umschaltung_verzoegert" ;
VAL_ 917 LWR_Pos_Schrittmotor 254 "Init" 255 "Fehler" ;
VAL_ 917 LWR_Hoehenwert_VL 254 "nicht_initialisiert" 255 "Fehler" ;
VAL_ 917 LWR_Hoehenwert_HL 254 "nicht_initialisiert" 255 "Fehler" ;
VAL_ 917 AFS_Ersatzlicht_Links 0 "keine Ersatzlichtfunktion links" 1 "Ersatzlichtfunktion links" ;
VAL_ 917 AFS_Ersatzlicht_Rechts 0 "keine Ersatzlichtfunktion rechts" 1 "Ersatzlichtfunktion rechts" ;
VAL_ 917 LWR_AFS_Grundeinstellung 0 "Grundeinstellung nicht erfolgt" 1 "Grundeinstellung erfolgt" ;
VAL_ 917 LWR_AFS_Parametrisierung 0 "Parametrisierung nicht erfolgt" 1 "Parametrisierung erfolgt" ;
VAL_ 917 LWR_Initialisierungslauf 0 "Initialisierungslauf nicht erfolgt" 1 "Initialisierungslauf erfolgt" ;
VAL_ 917 LWR_Sicherheitsposition_li 0 "inaktiv" 1 "aktiv" ;
VAL_ 917 LWR_Modus 0 "LWR statisch" 1 "LWR dynamisch" ;
